VERSION "V5.0.0"

NS_ :

BS_:

BU_: SGW_SG CGW_SG

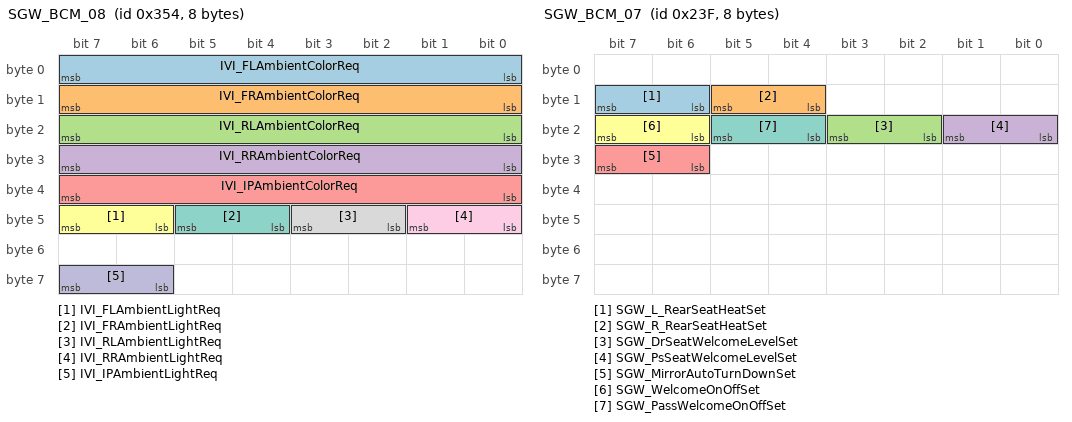
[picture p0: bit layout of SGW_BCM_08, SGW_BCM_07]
BO_ 852 SGW_BCM_08: 8 SGW_SG
 SG_ IVI_FLAmbientColorReq  : 7|8@0+ (1,0) [0|255] "" CGW_SG
 SG_ IVI_FRAmbientColorReq  : 15|8@0+ (1,0) [0|255] "" CGW_SG
 SG_ IVI_RLAmbientColorReq  : 23|8@0+ (1,0) [0|255] "" CGW_SG
 SG_ IVI_RRAmbientColorReq  : 31|8@0+ (1,0) [0|255] "" CGW_SG
 SG_ IVI_IPAmbientColorReq  : 39|8@0+ (1,0) [0|255] "" CGW_SG
 SG_ IVI_FLAmbientLightReq  : 47|2@0+ (1,0) [0|2] "" CGW_SG
 SG_ IVI_FRAmbientLightReq  : 45|2@0+ (1,0) [0|2] "" CGW_SG
 SG_ IVI_RLAmbientLightReq  : 43|2@0+ (1,0) [0|2] "" CGW_SG
 SG_ IVI_RRAmbientLightReq  : 41|2@0+ (1,0) [0|2] "" CGW_SG
 SG_ IVI_IPAmbientLightReq  : 63|2@0+ (1,0) [0|2] "" CGW_SG

BO_ 575 SGW_BCM_07: 8 SGW_SG
 SG_ SGW_L_RearSeatHeatSet  : 15|2@0+ (1,0) [0|3] "" CGW_SG
 SG_ SGW_R_RearSeatHeatSet  : 13|2@0+ (1,0) [0|3] "" CGW_SG
 SG_ SGW_DrSeatWelcomeLevelSet  : 19|2@0+ (1,0) [0|3] "" CGW_SG
 SG_ SGW_PsSeatWelcomeLevelSet  : 17|2@0+ (1,0) [0|3] "" CGW_SG
 SG_ SGW_MirrorAutoTurnDownSet  : 31|2@0+ (1,0) [0|3] "" CGW_SG
 SG_ SGW_WelcomeOnOffSet  : 23|2@0+ (1,0) [0|3] "" CGW_SG
 SG_ SGW_PassWelcomeOnOffSet  : 21|2@0+ (1,0) [0|3] "" CGW_SG

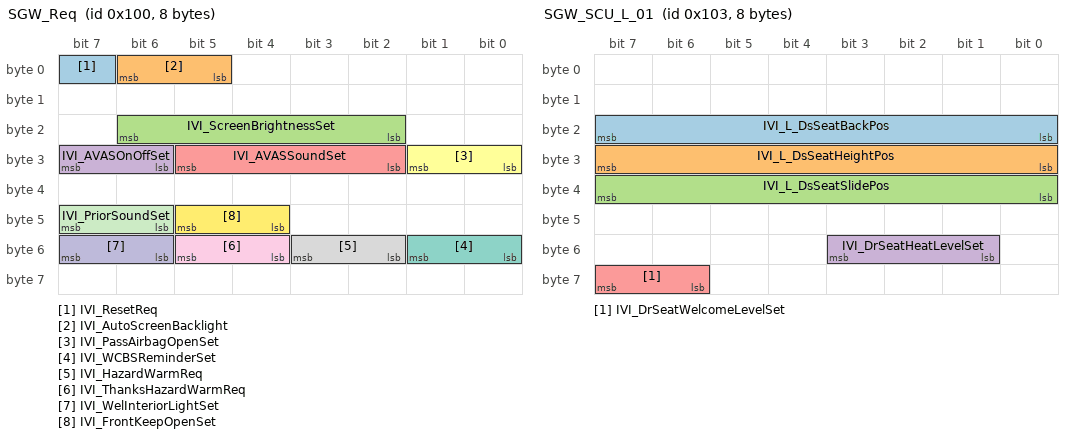
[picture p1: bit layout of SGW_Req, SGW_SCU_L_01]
BO_ 256 SGW_Req: 8 SGW_SG
 SG_ IVI_ResetReq  : 7|1@0+ (1,0) [0|1] "" CGW_SG
 SG_ IVI_AutoScreenBacklight  : 6|2@0+ (1,0) [0|3] "" CGW_SG
 SG_ IVI_ScreenBrightnessSet  : 22|5@0+ (1,0) [0|31] "" CGW_SG
 SG_ IVI_AVASOnOffSet  : 31|2@0+ (1,0) [0|3] "" CGW_SG
 SG_ IVI_AVASSoundSet  : 29|4@0+ (1,0) [0|9] "" CGW_SG
 SG_ IVI_PassAirbagOpenSet  : 25|2@0+ (1,0) [0|3] "" CGW_SG
 SG_ IVI_WCBSReminderSet  : 49|2@0+ (1,0) [0|3] "" CGW_SG
 SG_ IVI_HazardWarmReq  : 51|2@0+ (1,0) [0|2] "" CGW_SG
 SG_ IVI_ThanksHazardWarmReq  : 53|2@0+ (1,0) [0|1] "" CGW_SG
 SG_ IVI_WelInteriorLightSet  : 55|2@0+ (1,0) [0|2] "" CGW_SG
 SG_ IVI_PriorSoundSet  : 47|2@0+ (1,0) [0|3] "" CGW_SG
 SG_ IVI_FrontKeepOpenSet  : 45|2@0+ (1,0) [0|3] "" CGW_SG

BO_ 259 SGW_SCU_L_01: 8 SGW_SG
 SG_ IVI_L_DsSeatBackPos  : 23|8@0+ (1,0) [0|100] "percent" CGW_SG
 SG_ IVI_L_DsSeatHeightPos  : 31|8@0+ (1,0) [0|100] "percent" CGW_SG
 SG_ IVI_L_DsSeatSlidePos  : 39|8@0+ (1,0) [0|100] "percent" CGW_SG
 SG_ IVI_DrSeatHeatLevelSet  : 51|3@0+ (1,0) [0|7] "" CGW_SG
 SG_ IVI_DrSeatWelcomeLevelSet  : 63|2@0+ (1,0) [0|3] "" CGW_SG

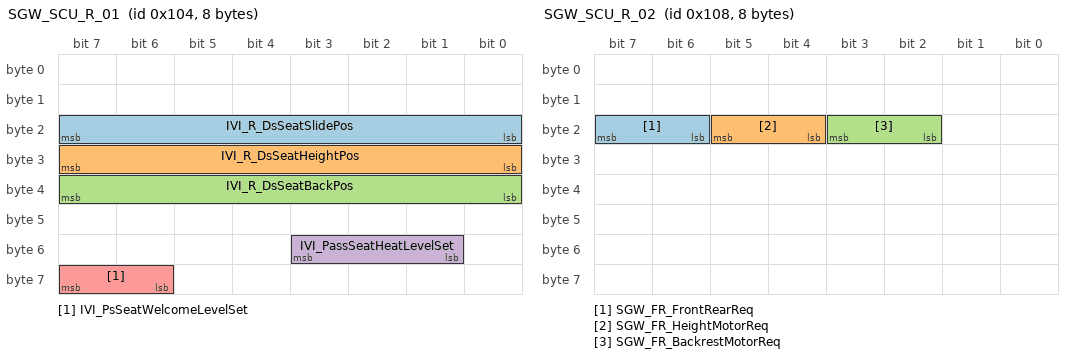
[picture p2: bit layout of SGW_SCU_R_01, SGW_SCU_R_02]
BO_ 260 SGW_SCU_R_01: 8 SGW_SG
 SG_ IVI_R_DsSeatSlidePos  : 23|8@0+ (1,0) [0|100] "percent" CGW_SG
 SG_ IVI_R_DsSeatHeightPos  : 31|8@0+ (1,0) [0|100] "percent" CGW_SG
 SG_ IVI_R_DsSeatBackPos  : 39|8@0+ (1,0) [0|100] "percent" CGW_SG
 SG_ IVI_PassSeatHeatLevelSet  : 51|3@0+ (1,0) [0|7] "" CGW_SG
 SG_ IVI_PsSeatWelcomeLevelSet  : 63|2@0+ (1,0) [0|3] "" CGW_SG

BO_ 264 SGW_SCU_R_02: 8 SGW_SG
 SG_ SGW_FR_FrontRearReq  : 23|2@0+ (1,0) [0|2] "" CGW_SG
 SG_ SGW_FR_HeightMotorReq  : 21|2@0+ (1,0) [0|2] "" CGW_SG
 SG_ SGW_FR_BackrestMotorReq  : 19|2@0+ (1,0) [0|2] "" CGW_SG

BO_ 710 SGW_SteerWhPos: 8 SGW_SG
 SG_ IVI_StWAnglePos  : 31|8@0+ (1,-100) [-100|100] "percent" CGW_SG
 SG_ IVI_StWLengthPos  : 39|8@0+ (1,-100) [-100|100] "percent" CGW_SG

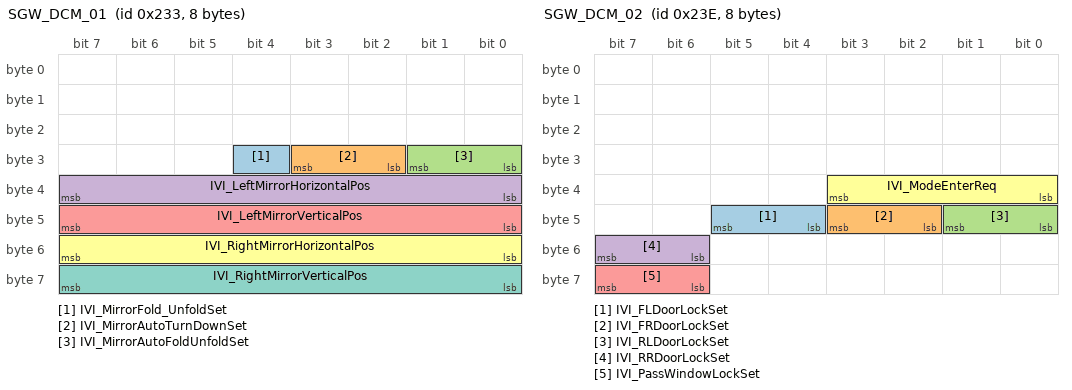
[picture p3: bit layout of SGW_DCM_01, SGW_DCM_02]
BO_ 563 SGW_DCM_01: 8 SGW_SG
 SG_ IVI_MirrorFold_UnfoldSet  : 28|1@0+ (1,0) [0|1] "" CGW_SG
 SG_ IVI_MirrorAutoTurnDownSet  : 27|2@0+ (1,0) [0|3] "" CGW_SG
 SG_ IVI_MirrorAutoFoldUnfoldSet  : 25|2@0+ (1,0) [0|3] "" CGW_SG
 SG_ IVI_LeftMirrorHorizontalPos  : 39|8@0+ (1,0) [0|100] "percent" CGW_SG
 SG_ IVI_LeftMirrorVerticalPos  : 47|8@0+ (1,0) [0|100] "percent" CGW_SG
 SG_ IVI_RightMirrorHorizontalPos  : 55|8@0+ (1,0) [0|100] "percent" CGW_SG
 SG_ IVI_RightMirrorVerticalPos  : 63|8@0+ (1,0) [0|100] "percent" CGW_SG

BO_ 574 SGW_DCM_02: 8 SGW_SG
 SG_ IVI_FLDoorLockSet  : 45|2@0+ (1,0) [0|3] "" CGW_SG
 SG_ IVI_FRDoorLockSet  : 43|2@0+ (1,0) [0|3] "" CGW_SG
 SG_ IVI_RLDoorLockSet  : 41|2@0+ (1,0) [0|3] "" CGW_SG
 SG_ IVI_RRDoorLockSet  : 55|2@0+ (1,0) [0|3] "" CGW_SG
 SG_ IVI_PassWindowLockSet  : 63|2@0+ (1,0) [0|3] "" CGW_SG
 SG_ IVI_ModeEnterReq  : 35|4@0+ (1,0) [0|15] "" CGW_SG

BO_ 689 SGW_HUD_01: 8 SGW_SG
 SG_ IVI_HUDALTITUDESet  : 7|8@0+ (1,0) [0|255] "" CGW_SG
 SG_ IVI_HUDOnOffSet  : 15|2@0+ (1,0) [0|3] "" CGW_SG

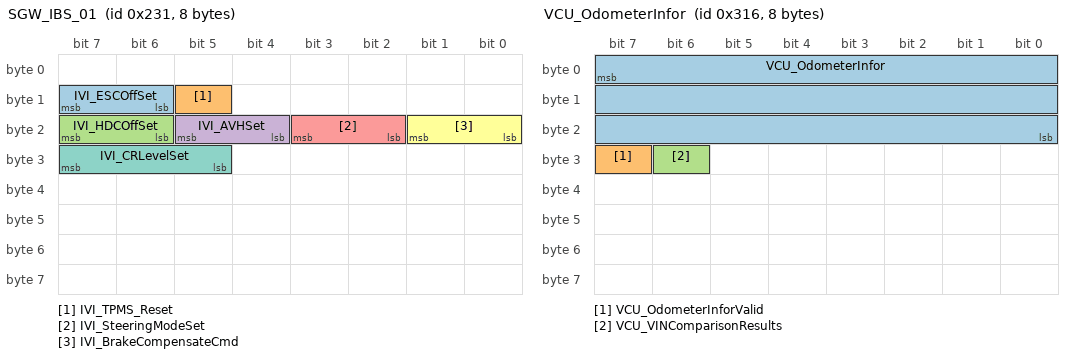
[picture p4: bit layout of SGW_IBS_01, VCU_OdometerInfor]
BO_ 561 SGW_IBS_01: 8 SGW_SG
 SG_ IVI_ESCOffSet  : 15|2@0+ (1,0) [0|3] "" CGW_SG
 SG_ IVI_TPMS_Reset  : 13|1@0+ (1,0) [0|1] "" CGW_SG
 SG_ IVI_HDCOffSet  : 23|2@0+ (1,0) [0|3] "" CGW_SG
 SG_ IVI_AVHSet  : 21|2@0+ (1,0) [0|3] "" CGW_SG
 SG_ IVI_SteeringModeSet  : 19|2@0+ (1,0) [0|3] "" CGW_SG
 SG_ IVI_BrakeCompensateCmd  : 17|2@0+ (1,0) [0|3] "" CGW_SG
 SG_ IVI_CRLevelSet  : 31|3@0+ (1,0) [0|7] "" CGW_SG

BO_ 790 VCU_OdometerInfor: 8 CGW_SG
 SG_ VCU_OdometerInfor  : 7|24@0+ (0.1,0) [0|999999.9] "km" SGW_SG
 SG_ VCU_OdometerInforValid  : 31|1@0+ (1,0) [0|1] "" SGW_SG
 SG_ VCU_VINComparisonResults  : 30|1@0+ (1,0) [0|1] "" SGW_SG

BO_ 945 SGW_OdometerInfor_02: 8 SGW_SG
 SG_ SGW_OdometerInfor  : 23|24@0+ (0.1,0) [0|999999.9] "" CGW_SG
 SG_ SGW_OdometerInforValid  : 47|1@0+ (1,0) [0|1] "" CGW_SG

BO_ 946 SGW_OdometerInfor_03: 8 SGW_SG
 SG_ SGW_VIN  : 7|64@0+ (1,0) [0|6.51062E+18] "" CGW_SG

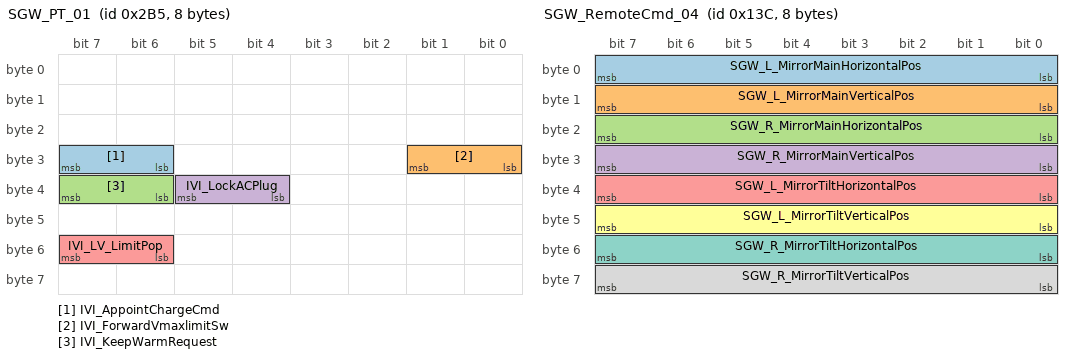
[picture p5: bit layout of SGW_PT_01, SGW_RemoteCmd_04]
BO_ 693 SGW_PT_01: 8 SGW_SG
 SG_ IVI_AppointChargeCmd  : 31|2@0+ (1,0) [0|2] "" CGW_SG
 SG_ IVI_ForwardVmaxlimitSw  : 25|2@0+ (1,0) [0|3] "" CGW_SG
 SG_ IVI_KeepWarmRequest  : 39|2@0+ (1,0) [0|2] "" CGW_SG
 SG_ IVI_LockACPlug  : 37|2@0+ (1,0) [0|2] "" CGW_SG
 SG_ IVI_LV_LimitPop  : 55|2@0+ (1,0) [0|2] "" CGW_SG

BO_ 694 IVI_01: 8 CGW_SG
 SG_ IVI_GearRequest  : 15|3@0+ (1,0) [0|5] "" SGW_SG

BO_ 261 SGW_RemoteCmd_01: 8 SGW_SG
 SG_ SGW_RemoteAirCondAUTOReq  : 13|2@0+ (1,0) [0|3] "" CGW_SG
 SG_ SGW_RemoteAirCondOnOFFReq  : 15|2@0+ (1,0) [0|3] "" CGW_SG
 SG_ SGW_RearDoorAngleSet  : 19|2@0+ (1,0) [0|2] "" CGW_SG
 SG_ SGW_FrontDoorAngleSet  : 21|2@0+ (1,0) [0|2] "" CGW_SG
 SG_ SGW_RemoteFrontDefrostReq  : 23|2@0+ (1,0) [0|3] "" CGW_SG
 SG_ SGW_RemoteSteerHeatReq  : 25|2@0+ (1,0) [0|3] "" CGW_SG
 SG_ SGW_RemoteDrSeatHeatReq  : 28|3@0+ (1,0) [0|4] "" CGW_SG
 SG_ SGW_LeftChdLockCtrlReq  : 31|2@0+ (1,0) [0|2] "" CGW_SG
 SG_ SGW_RearDefrostCtrlSet  : 32|1@0+ (1,0) [0|1] "" CGW_SG
 SG_ SGW_RemoteFrontWindHeatReq  : 34|2@0+ (1,0) [0|3] "" CGW_SG
 SG_ SGW_RemoteRearMirHeatReq  : 36|2@0+ (1,0) [0|3] "" CGW_SG
 SG_ SGW_RemotePassSeatHeatReq  : 39|3@0+ (1,0) [0|4] "" CGW_SG
 SG_ SGW_oneTouchCoolSet  : 43|2@0+ (1,0) [0|2] "" CGW_SG
 SG_ SGW_RemoteRearWindHeatReq  : 47|2@0+ (1,0) [0|3] "" CGW_SG
 SG_ SGW_TakePicCtrl  : 51|3@0+ (1,0) [0|7] "" CGW_SG
 SG_ SGW_RemoteACOnOffReq  : 57|2@0+ (1,0) [0|2] "" CGW_SG
 SG_ SGW_RightChdLockCtrlReq  : 59|2@0+ (1,0) [0|2] "" CGW_SG
 SG_ SGW_RemoteTailgateLockCtrlReq  : 63|2@0+ (1,0) [0|3] "" CGW_SG
 SG_ SGW_HDCOffSet  : 7|2@0+ (1,0) [0|3] "" Vector__XXX
 SG_ SGW_AVHSet  : 5|2@0+ (1,0) [0|3] "" Vector__XXX
 SG_ SGW_SteeringModeSet  : 61|2@0+ (1,0) [0|3] "" Vector__XXX
 SG_ SGW_AVASSoundSet  : 3|4@0+ (1,0) [0|9] "" Vector__XXX
 SG_ SGW_DriveModeSet  : 11|3@0+ (1,0) [0|4] "" Vector__XXX
 SG_ SGW_ImuCarParkBeStolen  : 55|3@0+ (1,0) [0|4] "" Vector__XXX

BO_ 262 SGW_RemoteCmd_02: 8 SGW_SG
 SG_ IVI_HUDScreenBrightnessSet  : 31|5@0+ (1,0) [0|31] "" CGW_SG

BO_ 263 SGW_RemoteCmd_03: 8 SGW_SG
 SG_ SGW_AutoCloseWinFunSet  : 1|2@0+ (1,0) [0|2] "" CGW_SG
 SG_ SGW_RemoteDrvSetTempSteplsReq  : 7|6@0+ (1,0) [0|63] "" CGW_SG
 SG_ SGW_FrontWiperAutoSet  : 9|2@0+ (1,0) [0|2] "" CGW_SG
 SG_ SGW_RemotePassSetTempSteplsReq  : 15|6@0+ (1,0) [0|63] "" CGW_SG
 SG_ SGW_AllDoorReq  : 17|2@0+ (1,0) [0|2] "" CGW_SG
 SG_ SGW_RemoteCarSearchReq  : 19|2@0+ (1,0) [0|3] "" CGW_SG
 SG_ SGW_RemoteLockCtrlReq  : 21|2@0+ (1,0) [0|3] "" CGW_SG
 SG_ SGW_RRDoorReq  : 25|2@0+ (1,0) [0|2] "" CGW_SG
 SG_ SGW_RLDoorReq  : 27|2@0+ (1,0) [0|2] "" CGW_SG
 SG_ SGW_FRDoorReq  : 29|2@0+ (1,0) [0|2] "" CGW_SG
 SG_ SGW_FLDoorReq  : 31|2@0+ (1,0) [0|2] "" CGW_SG
 SG_ SGW_WelInteriorLightSet  : 39|2@0+ (1,0) [0|2] "" CGW_SG
 SG_ SGW_CarSharingLightSet  : 37|2@0+ (1,0) [0|2] "" CGW_SG
 SG_ SGW_CarSharingColorSet  : 47|8@0+ (1,0) [0|255] "" CGW_SG
 SG_ SGW_CarSharingTimeSet  : 35|4@0+ (1,0) [0|10] "s" CGW_SG
 SG_ SGW_FRDomeLampSet  : 55|2@0+ (1,0) [0|2] "" CGW_SG
 SG_ SGW_RRDomeLampSet  : 53|2@0+ (1,0) [0|2] "" CGW_SG

BO_ 316 SGW_RemoteCmd_04: 8 SGW_SG
 SG_ SGW_L_MirrorMainHorizontalPos  : 7|8@0+ (1,0) [0|100] "percent" CGW_SG
 SG_ SGW_L_MirrorMainVerticalPos  : 15|8@0+ (1,0) [0|100] "percent" CGW_SG
 SG_ SGW_R_MirrorMainHorizontalPos  : 23|8@0+ (1,0) [0|100] "percent" CGW_SG
 SG_ SGW_R_MirrorMainVerticalPos  : 31|8@0+ (1,0) [0|100] "percent" CGW_SG
 SG_ SGW_L_MirrorTiltHorizontalPos  : 39|8@0+ (1,0) [0|100] "percent" CGW_SG
 SG_ SGW_L_MirrorTiltVerticalPos  : 47|8@0+ (1,0) [0|100] "percent" CGW_SG
 SG_ SGW_R_MirrorTiltHorizontalPos  : 55|8@0+ (1,0) [0|100] "percent" CGW_SG
 SG_ SGW_R_MirrorTiltVerticalPos  : 63|8@0+ (1,0) [0|100] "percent" CGW_SG

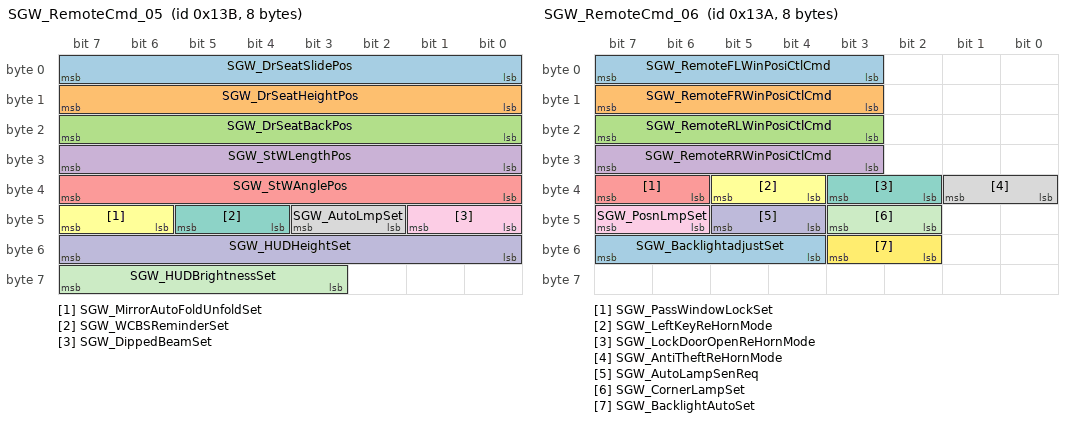
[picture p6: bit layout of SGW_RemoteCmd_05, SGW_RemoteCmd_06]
BO_ 315 SGW_RemoteCmd_05: 8 SGW_SG
 SG_ SGW_DrSeatSlidePos  : 7|8@0+ (1,0) [0|100] "percent" CGW_SG
 SG_ SGW_DrSeatHeightPos  : 15|8@0+ (1,0) [0|100] "percent" CGW_SG
 SG_ SGW_DrSeatBackPos  : 23|8@0+ (1,0) [0|100] "percent" CGW_SG
 SG_ SGW_StWLengthPos  : 31|8@0+ (1,-100) [-100|100] "percent" CGW_SG
 SG_ SGW_StWAnglePos  : 39|8@0+ (1,-100) [-100|100] "percent" CGW_SG
 SG_ SGW_MirrorAutoFoldUnfoldSet  : 47|2@0+ (1,0) [0|3] "" CGW_SG
 SG_ SGW_WCBSReminderSet  : 45|2@0+ (1,0) [0|3] "" CGW_SG
 SG_ SGW_AutoLmpSet  : 43|2@0+ (1,0) [0|3] "" CGW_SG
 SG_ SGW_DippedBeamSet  : 41|2@0+ (1,0) [0|3] "" CGW_SG
 SG_ SGW_HUDHeightSet  : 55|8@0+ (1,0) [0|255] "" CGW_SG
 SG_ SGW_HUDBrightnessSet  : 63|5@0+ (1,0) [0|31] "" CGW_SG

BO_ 314 SGW_RemoteCmd_06: 8 SGW_SG
 SG_ SGW_RemoteFLWinPosiCtlCmd  : 7|5@0+ (1,0) [0|21] "" CGW_SG
 SG_ SGW_RemoteFRWinPosiCtlCmd  : 15|5@0+ (1,0) [0|21] "" CGW_SG
 SG_ SGW_RemoteRLWinPosiCtlCmd  : 23|5@0+ (1,0) [0|21] "" CGW_SG
 SG_ SGW_RemoteRRWinPosiCtlCmd  : 31|5@0+ (1,0) [0|21] "" CGW_SG
 SG_ SGW_PassWindowLockSet  : 39|2@0+ (1,0) [0|3] "" CGW_SG
 SG_ SGW_LeftKeyReHornMode  : 37|2@0+ (1,0) [0|2] "" CGW_SG
 SG_ SGW_LockDoorOpenReHornMode  : 35|2@0+ (1,0) [0|2] "" CGW_SG
 SG_ SGW_AntiTheftReHornMode  : 33|2@0+ (1,0) [0|2] "" CGW_SG
 SG_ SGW_PosnLmpSet  : 47|2@0+ (1,0) [0|2] "" CGW_SG
 SG_ SGW_AutoLampSenReq  : 45|2@0+ (1,0) [0|3] "" CGW_SG
 SG_ SGW_CornerLampSet  : 43|2@0+ (1,0) [0|3] "" CGW_SG
 SG_ SGW_BacklightAutoSet  : 51|2@0+ (1,0) [0|2] "" CGW_SG
 SG_ SGW_BacklightadjustSet  : 55|4@0+ (1,0) [0|13] "" CGW_SG

BO_ 562 SGW_TCU_01: 8 SGW_SG
 SG_ SGW_DrvSetTempSteplsReq  : 7|6@0+ (1,0) [0|63] "" CGW_SG
 SG_ SGW_DemistReq  : 1|2@0+ (1,0) [0|3] "" CGW_SG
 SG_ SGW_HVACBatterySaveModeSetReq  : 15|2@0+ (1,0) [0|3] "" CGW_SG
 SG_ SGW_PassSetTempSteplsReq  : 13|6@0+ (1,0) [0|63] "" CGW_SG
 SG_ SGW_AirCondAUTOReq  : 23|2@0+ (1,0) [0|3] "" CGW_SG
 SG_ SGW_DualReq  : 21|2@0+ (1,0) [0|3] "" CGW_SG
 SG_ SGW_AirDistributionModeReq  : 19|3@0+ (1,0) [0|7] "" CGW_SG
 SG_ SGW_FrontDefrostReq  : 16|2@0+ (1,0) [0|3] "" CGW_SG
 SG_ SGW_AqsReq  : 39|2@0+ (1,0) [0|3] "" CGW_SG
 SG_ SGW_ClimateSystemStsReq  : 35|2@0+ (1,0) [0|3] "" CGW_SG
 SG_ SGW_ACCmprStsReq  : 33|2@0+ (1,0) [0|3] "" CGW_SG
 SG_ SGW_AirCirclnReq  : 47|2@0+ (1,0) [0|3] "" CGW_SG
 SG_ SGW_BlowersteplsSpdReq  : 43|4@0+ (1,0) [0|15] "" CGW_SG
 SG_ SGW_PresetModeEnable  : 55|2@0+ (1,0) [0|2] "" CGW_SG
 SG_ SGW_PresetModeReq  : 53|3@0+ (1,0) [0|7] "" CGW_SG
 SG_ SGW_VentilationModeReq  : 50|2@0+ (1,0) [0|2] "" CGW_SG
 SG_ SGW_AirCondEcoSet  : 60|2@0+ (1,0) [0|3] "" CGW_SG

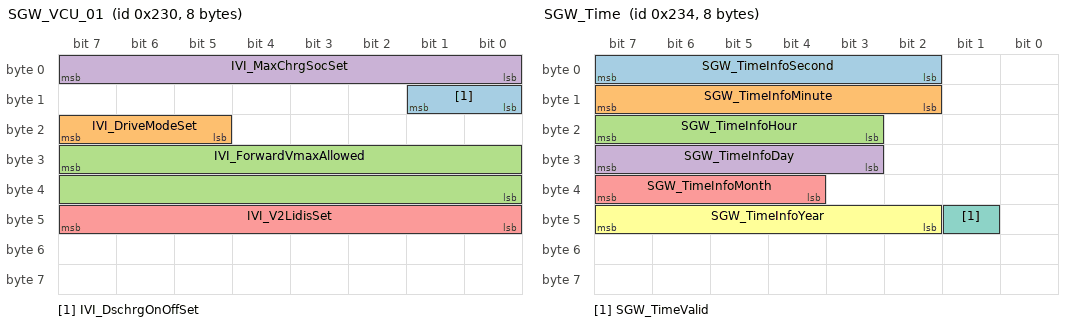
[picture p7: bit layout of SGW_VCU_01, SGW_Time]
BO_ 560 SGW_VCU_01: 8 SGW_SG
 SG_ IVI_DschrgOnOffSet  : 9|2@0+ (1,0) [0|3] "" CGW_SG
 SG_ IVI_DriveModeSet  : 23|3@0+ (1,0) [0|4] "" CGW_SG
 SG_ IVI_ForwardVmaxAllowed  : 31|16@0+ (0.01,0) [0|360] "km/h" CGW_SG
 SG_ IVI_MaxChrgSocSet  : 7|8@0+ (1,0) [0|100] "percent" CGW_SG
 SG_ IVI_V2LidisSet  : 47|8@0+ (1,0) [0|100] "percent" CGW_SG

BO_ 564 SGW_Time: 8 SGW_SG
 SG_ SGW_TimeInfoSecond  : 7|6@0+ (1,0) [0|59] "" CGW_SG
 SG_ SGW_TimeInfoMinute  : 15|6@0+ (1,0) [0|59] "" CGW_SG
 SG_ SGW_TimeInfoHour  : 23|5@0+ (1,0) [0|23] "" CGW_SG
 SG_ SGW_TimeInfoDay  : 31|5@0+ (1,0) [1|31] "" CGW_SG
 SG_ SGW_TimeInfoMonth  : 39|4@0+ (1,0) [1|12] "" CGW_SG
 SG_ SGW_TimeInfoYear  : 47|6@0+ (1,2000) [2000|2059] "" CGW_SG
 SG_ SGW_TimeValid  : 41|1@0+ (1,0) [0|1] "" CGW_SG

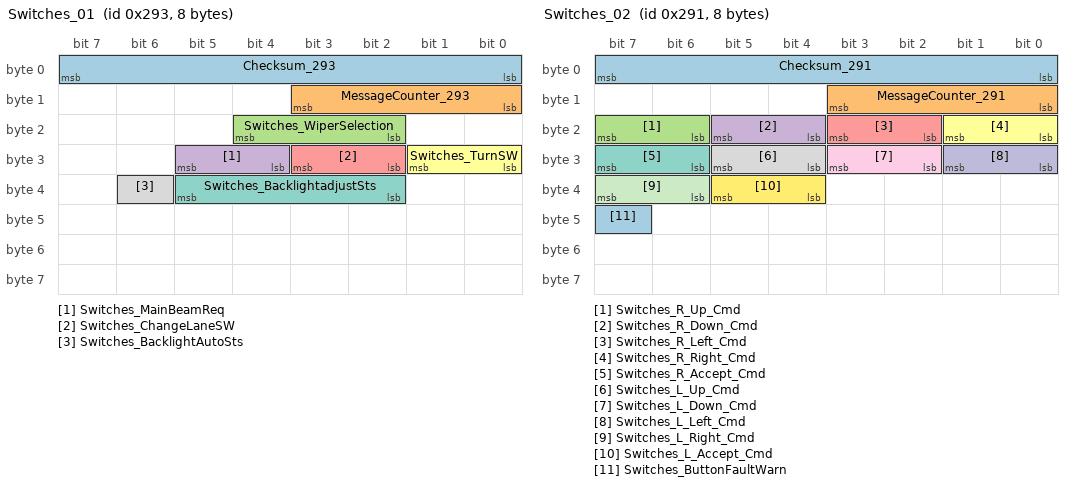
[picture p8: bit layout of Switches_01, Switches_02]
BO_ 659 Switches_01: 8 CGW_SG
 SG_ Checksum_293  : 7|8@0+ (1,0) [0|255] "" SGW_SG
 SG_ MessageCounter_293  : 11|4@0+ (1,0) [0|15] "" SGW_SG
 SG_ Switches_WiperSelection  : 20|3@0+ (1,0) [0|5] "" SGW_SG
 SG_ Switches_MainBeamReq  : 29|2@0+ (1,0) [0|3] "" SGW_SG
 SG_ Switches_ChangeLaneSW  : 27|2@0+ (1,0) [0|3] "" SGW_SG
 SG_ Switches_TurnSW  : 25|2@0+ (1,0) [0|3] "" SGW_SG
 SG_ Switches_BacklightadjustSts  : 37|4@0+ (1,0) [0|12] "" SGW_SG
 SG_ Switches_BacklightAutoSts  : 38|1@0+ (1,0) [0|1] "" SGW_SG

BO_ 657 Switches_02: 8 CGW_SG
 SG_ Checksum_291  : 7|8@0+ (1,0) [0|255] "" SGW_SG
 SG_ MessageCounter_291  : 11|4@0+ (1,0) [0|15] "" SGW_SG
 SG_ Switches_R_Up_Cmd  : 23|2@0+ (1,0) [0|1] "" SGW_SG
 SG_ Switches_R_Down_Cmd  : 21|2@0+ (1,0) [0|1] "" SGW_SG
 SG_ Switches_R_Left_Cmd  : 19|2@0+ (1,0) [0|1] "" SGW_SG
 SG_ Switches_R_Right_Cmd  : 17|2@0+ (1,0) [0|1] "" SGW_SG
 SG_ Switches_R_Accept_Cmd  : 31|2@0+ (1,0) [0|1] "" SGW_SG
 SG_ Switches_L_Up_Cmd  : 29|2@0+ (1,0) [0|1] "" SGW_SG
 SG_ Switches_L_Down_Cmd  : 27|2@0+ (1,0) [0|1] "" SGW_SG
 SG_ Switches_L_Left_Cmd  : 25|2@0+ (1,0) [0|1] "" SGW_SG
 SG_ Switches_L_Right_Cmd  : 39|2@0+ (1,0) [0|1] "" SGW_SG
 SG_ Switches_L_Accept_Cmd  : 37|2@0+ (1,0) [0|1] "" SGW_SG
 SG_ Switches_ButtonFaultWarn  : 47|1@0+ (1,0) [0|1] "" SGW_SG

BO_ 271 Switches_03: 8 CGW_SG
 SG_ Switches_L_SWipe_Cmd  : 0|4@0+ (1,0) [0|15] "" SGW_SG

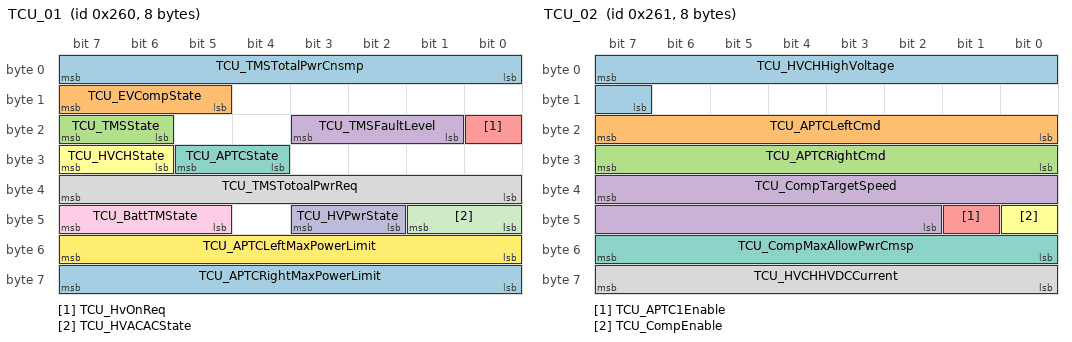
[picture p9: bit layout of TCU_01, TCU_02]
BO_ 608 TCU_01: 8 CGW_SG
 SG_ TCU_TMSTotalPwrCnsmp  : 7|8@0+ (200,0) [0|40000] "w" SGW_SG
 SG_ TCU_EVCompState  : 15|3@0+ (1,0) [0|7] "" SGW_SG
 SG_ TCU_TMSState  : 23|2@0+ (1,0) [0|2] "" SGW_SG
 SG_ TCU_TMSFaultLevel  : 19|3@0+ (1,0) [0|7] "" SGW_SG
 SG_ TCU_HvOnReq  : 16|1@0+ (1,0) [0|1] "" SGW_SG
 SG_ TCU_HVCHState  : 31|2@0+ (1,0) [0|3] "" SGW_SG
 SG_ TCU_APTCState  : 29|2@0+ (1,0) [0|3] "" SGW_SG
 SG_ TCU_TMSTotoalPwrReq  : 39|8@0+ (200,0) [0|40000] "w" SGW_SG
 SG_ TCU_BattTMState  : 47|3@0+ (1,0) [0|7] "" SGW_SG
 SG_ TCU_HVPwrState  : 43|2@0+ (1,0) [0|3] "" SGW_SG
 SG_ TCU_HVACACState  : 41|2@0+ (1,0) [0|3] "" SGW_SG
 SG_ TCU_APTCLeftMaxPowerLimit  : 55|8@0+ (0.04,0) [0|10.2] "KW" SGW_SG
 SG_ TCU_APTCRightMaxPowerLimit  : 63|8@0+ (0.04,0) [0|10.2] "KW" SGW_SG

BO_ 609 TCU_02: 8 CGW_SG
 SG_ TCU_HVCHHighVoltage  : 7|9@0+ (1,0) [0|508] "V" SGW_SG
 SG_ TCU_APTCLeftCmd  : 23|8@0+ (1,0) [0|100] "percent" SGW_SG
 SG_ TCU_APTCRightCmd  : 31|8@0+ (1,0) [0|100] "percent" SGW_SG
 SG_ TCU_CompTargetSpeed  : 39|14@0+ (1,0) [0|9200] "rpm" SGW_SG
 SG_ TCU_APTC1Enable  : 41|1@0+ (1,0) [0|1] "" SGW_SG
 SG_ TCU_CompEnable  : 40|1@0+ (1,0) [0|1] "" SGW_SG
 SG_ TCU_CompMaxAllowPwrCmsp  : 55|8@0+ (0.04,0) [0|10.16] "KW" SGW_SG
 SG_ TCU_HVCHHVDCCurrent  : 63|8@0+ (0.25,0) [0|63.5] "A" SGW_SG

BO_ 610 TCU_03: 8 CGW_SG
 SG_ TCU_CabinTemperature  : 23|8@0+ (1,-50) [-50|205] "celsius" SGW_SG
 SG_ TCU_CabinTemperatureValid  : 31|1@0+ (1,0) [0|1] "" SGW_SG

BO_ 768 TCU_IVI: 8 CGW_SG
 SG_ TCU_AirCondAUTOSts  : 3|1@0+ (1,0) [0|1] "" SGW_SG
 SG_ TCU_AirCirclnSts  : 5|2@0+ (1,0) [0|2] "" SGW_SG
 SG_ TCU_AirCondEcoSetSts  : 8|1@0+ (1,0) [0|1] "" SGW_SG
 SG_ TCU_SelfDryingSetSts  : 9|1@0+ (1,0) [0|1] "" SGW_SG
 SG_ TCU_DrvTempSts  : 15|6@0+ (1,0) [0|63] "" SGW_SG
 SG_ TCU_AqsSts  : 16|1@0+ (1,0) [0|1] "" SGW_SG
 SG_ TCU_DualSts  : 17|1@0+ (1,0) [0|1] "" SGW_SG
 SG_ TCU_PassTempSts  : 23|6@0+ (1,0) [0|63] "" SGW_SG
 SG_ TCU_CoolantLowWarnReq  : 25|2@0+ (1,0) [0|3] "" SGW_SG
 SG_ TCU_FreonLowWarnReq  : 27|2@0+ (1,0) [0|3] "" SGW_SG
 SG_ TCU_BlowerSpdSts  : 31|4@0+ (1,0) [0|15] "" SGW_SG
 SG_ TCU_AirDistributionModeSts  : 39|3@0+ (1,0) [0|7] "" SGW_SG
 SG_ TCU_PresetModeSts  : 35|3@0+ (1,0) [0|7] "" SGW_SG
 SG_ TCU_VentilationModeSts  : 32|1@0+ (1,0) [0|1] "" SGW_SG
 SG_ TCU_ACCmprSts  : 42|1@0+ (1,0) [0|1] "" SGW_SG
 SG_ TCU_ClimateSystemSts  : 43|1@0+ (1,0) [0|1] "" SGW_SG
 SG_ TCU_PowerLimitSts  : 44|1@0+ (1,0) [0|1] "" SGW_SG
 SG_ TCU_OutsideAQSLevel  : 47|3@0+ (1,0) [0|7] "" SGW_SG
 SG_ TCU_WindowClosRemind  : 50|1@0+ (1,0) [0|1] "" SGW_SG
 SG_ TCU_DemistSts  : 51|1@0+ (1,0) [0|1] "" SGW_SG

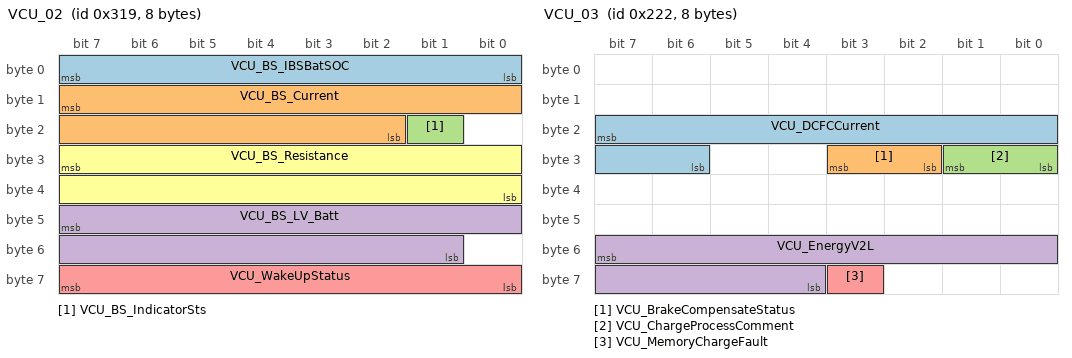
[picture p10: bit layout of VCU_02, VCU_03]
BO_ 793 VCU_02: 8 CGW_SG
 SG_ VCU_BS_IBSBatSOC  : 7|8@0+ (1,0) [0|100] "percent" SGW_SG
 SG_ VCU_BS_Current  : 15|14@0+ (0.001,-8.192) [-8.192|8.191] "" SGW_SG
 SG_ VCU_BS_IndicatorSts  : 17|1@0+ (1,0) [0|1] "" SGW_SG
 SG_ VCU_BS_LV_Batt  : 47|15@0+ (0.001,0) [0|32.767] "V" SGW_SG
 SG_ VCU_WakeUpStatus  : 63|8@0+ (1,0) [0|255] "" SGW_SG
 SG_ VCU_BS_Resistance  : 31|16@0+ (0.01,0) [0|65535] "mOhm" SGW_SG

BO_ 546 VCU_03: 8 CGW_SG
 SG_ VCU_DCFCCurrent  : 23|10@0+ (1,0) [0|1023] "A" SGW_SG
 SG_ VCU_BrakeCompensateStatus  : 27|2@0+ (1,0) [0|3] "" SGW_SG
 SG_ VCU_ChargeProcessComment  : 25|2@0+ (1,0) [0|3] "" SGW_SG
 SG_ VCU_EnergyV2L  : 55|12@0+ (0.1,0) [0|102.3] "kWh" SGW_SG
 SG_ VCU_MemoryChargeFault  : 59|1@0+ (1,0) [0|1] "" SGW_SG

BO_ 547 VCU_04: 8 CGW_SG
 SG_ VCU_ForwardVmaxlimitStatus  : 15|1@0+ (1,0) [0|1] "" SGW_SG
 SG_ VCU_ManuallyUnlockComment  : 14|1@0+ (1,0) [0|1] "" SGW_SG

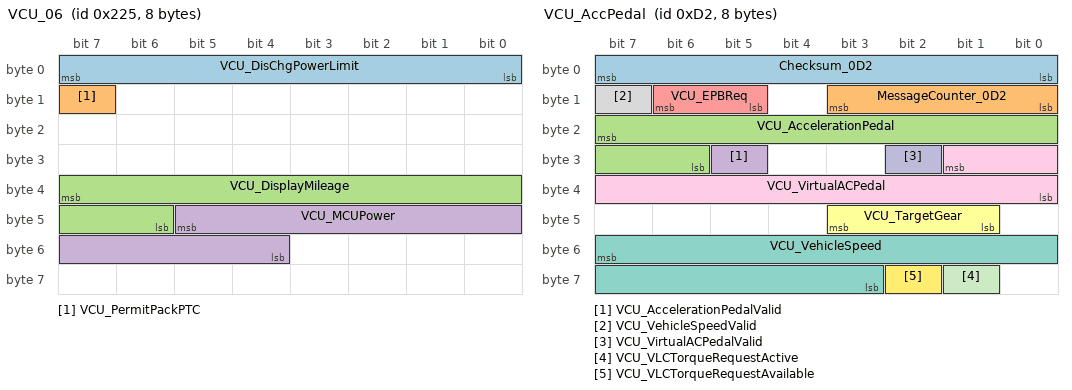
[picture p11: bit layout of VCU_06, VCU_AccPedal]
BO_ 549 VCU_06: 8 CGW_SG
 SG_ VCU_DisChgPowerLimit  : 7|8@0+ (0.1,0) [0|25.5] "kW" SGW_SG
 SG_ VCU_PermitPackPTC  : 15|1@0+ (1,0) [0|1] "" SGW_SG
 SG_ VCU_DisplayMileage  : 39|10@0+ (1,0) [0|1023] "km" SGW_SG
 SG_ VCU_MCUPower  : 45|10@0+ (1,-400) [-400|623] "kW" SGW_SG

BO_ 210 VCU_AccPedal: 8 CGW_SG
 SG_ Checksum_0D2  : 7|8@0+ (1,0) [0|255] "" SGW_SG
 SG_ MessageCounter_0D2  : 11|4@0+ (1,0) [0|15] "" SGW_SG
 SG_ VCU_AccelerationPedal  : 23|10@0+ (0.1,0) [0|100] "percent" SGW_SG
 SG_ VCU_AccelerationPedalValid  : 29|1@0+ (1,0) [0|1] "" SGW_SG
 SG_ VCU_EPBReq  : 14|2@0+ (1,0) [0|3] "" SGW_SG
 SG_ VCU_TargetGear  : 43|3@0+ (1,0) [0|4] "" SGW_SG
 SG_ VCU_VehicleSpeed  : 55|13@0+ (0.05625,0) [0|360] "km/h" SGW_SG
 SG_ VCU_VehicleSpeedValid  : 15|1@0+ (1,0) [0|1] "" SGW_SG
 SG_ VCU_VirtualACPedal  : 25|10@0+ (0.1,0) [0|100] "percent" SGW_SG
 SG_ VCU_VirtualACPedalValid  : 26|1@0+ (1,0) [0|1] "" SGW_SG
 SG_ VCU_VLCTorqueRequestActive  : 57|1@0+ (1,0) [0|1] "" SGW_SG
 SG_ VCU_VLCTorqueRequestAvailable  : 58|1@0+ (1,0) [0|1] "" SGW_SG

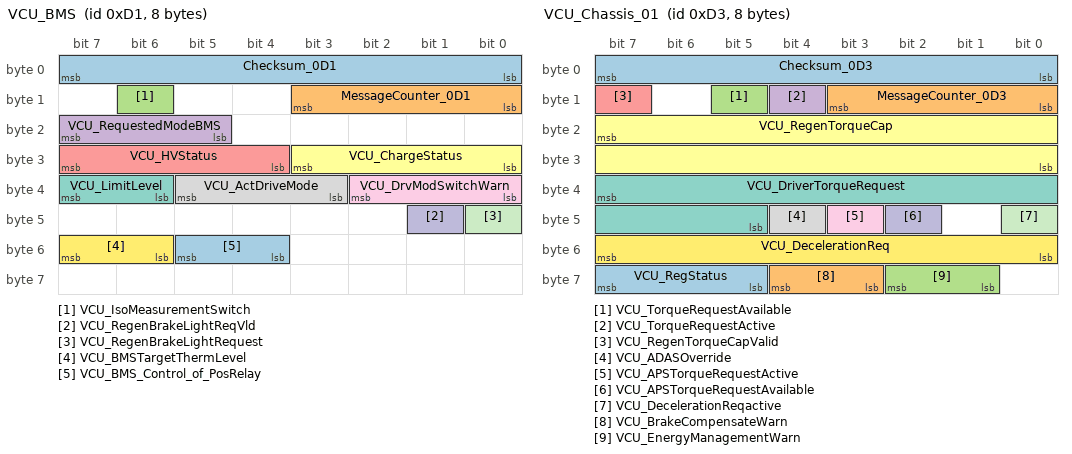
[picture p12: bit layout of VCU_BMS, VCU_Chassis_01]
BO_ 209 VCU_BMS: 8 CGW_SG
 SG_ Checksum_0D1  : 7|8@0+ (1,0) [0|255] "" SGW_SG
 SG_ MessageCounter_0D1  : 11|4@0+ (1,0) [0|15] "" SGW_SG
 SG_ VCU_IsoMeasurementSwitch  : 14|1@0+ (1,0) [0|1] "" SGW_SG
 SG_ VCU_RequestedModeBMS  : 23|3@0+ (1,0) [0|7] "" SGW_SG
 SG_ VCU_HVStatus  : 31|4@0+ (1,0) [0|5] "" SGW_SG
 SG_ VCU_ChargeStatus  : 27|4@0+ (1,0) [0|14] "" SGW_SG
 SG_ VCU_LimitLevel  : 39|2@0+ (1,0) [0|3] "" SGW_SG
 SG_ VCU_ActDriveMode  : 37|3@0+ (1,0) [0|4] "" SGW_SG
 SG_ VCU_DrvModSwitchWarn  : 34|3@0+ (1,0) [0|7] "" SGW_SG
 SG_ VCU_RegenBrakeLightReqVld  : 41|1@0+ (1,0) [0|1] "" SGW_SG
 SG_ VCU_RegenBrakeLightRequest  : 40|1@0+ (1,0) [0|1] "" SGW_SG
 SG_ VCU_BMSTargetThermLevel  : 55|2@0+ (1,0) [0|3] "" SGW_SG
 SG_ VCU_BMS_Control_of_PosRelay  : 53|2@0+ (1,0) [0|2] "" SGW_SG

BO_ 211 VCU_Chassis_01: 8 CGW_SG
 SG_ Checksum_0D3  : 7|8@0+ (1,0) [0|255] "" SGW_SG
 SG_ MessageCounter_0D3  : 11|4@0+ (1,0) [0|15] "" SGW_SG
 SG_ VCU_TorqueRequestAvailable  : 13|1@0+ (1,0) [0|1] "" SGW_SG
 SG_ VCU_TorqueRequestActive  : 12|1@0+ (1,0) [0|1] "" SGW_SG
 SG_ VCU_RegenTorqueCapValid  : 15|1@0+ (1,0) [0|1] "" SGW_SG
 SG_ VCU_RegenTorqueCap  : 23|16@0+ (1,-20000) [-20000|20000] "" SGW_SG
 SG_ VCU_DriverTorqueRequest  : 39|11@0+ (1,-1023) [-1023|1022] "" SGW_SG
 SG_ VCU_ADASOverride  : 44|1@0+ (1,0) [0|1] "" SGW_SG
 SG_ VCU_APSTorqueRequestActive  : 43|1@0+ (1,0) [0|1] "" SGW_SG
 SG_ VCU_APSTorqueRequestAvailable  : 42|1@0+ (1,0) [0|1] "" SGW_SG
 SG_ VCU_DecelerationReqactive  : 40|1@0+ (1,0) [0|1] "" SGW_SG
 SG_ VCU_DecelerationReq  : 55|8@0+ (0.05,-5) [-5|7.75] "m/s^2" SGW_SG
 SG_ VCU_RegStatus  : 63|3@0+ (1,0) [0|7] "" SGW_SG
 SG_ VCU_BrakeCompensateWarn  : 60|2@0+ (1,0) [0|3] "" SGW_SG
 SG_ VCU_EnergyManagementWarn  : 58|2@0+ (1,0) [0|3] "" SGW_SG

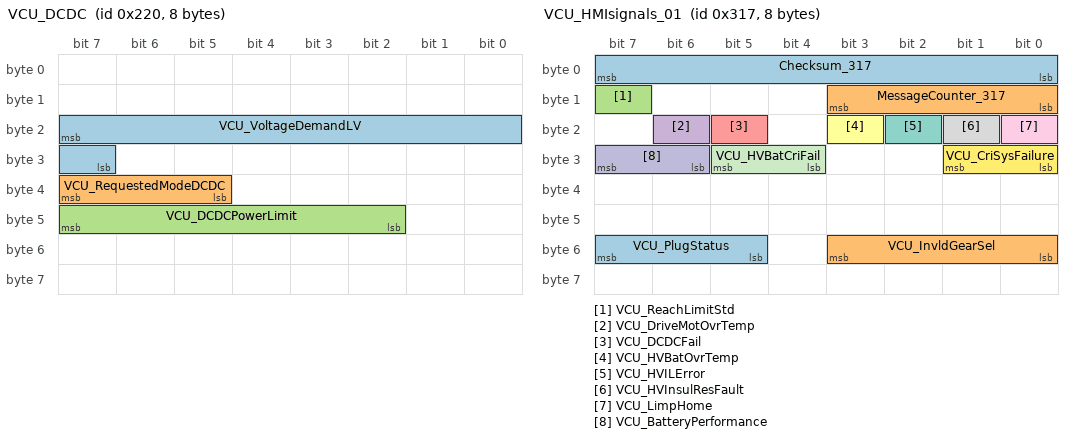
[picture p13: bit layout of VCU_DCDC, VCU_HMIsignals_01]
BO_ 544 VCU_DCDC: 8 CGW_SG
 SG_ VCU_VoltageDemandLV  : 23|9@0+ (0.125,0) [0|63.625] "V" SGW_SG
 SG_ VCU_RequestedModeDCDC  : 39|3@0+ (1,0) [0|2] "" SGW_SG
 SG_ VCU_DCDCPowerLimit  : 47|6@0+ (0.1,0) [0|6.3] "kW" SGW_SG

BO_ 791 VCU_HMIsignals_01: 8 CGW_SG
 SG_ Checksum_317  : 7|8@0+ (1,0) [0|255] "" SGW_SG
 SG_ MessageCounter_317  : 11|4@0+ (1,0) [0|15] "" SGW_SG
 SG_ VCU_ReachLimitStd  : 15|1@0+ (1,0) [0|1] "" SGW_SG
 SG_ VCU_DriveMotOvrTemp  : 22|1@0+ (1,0) [0|1] "" SGW_SG
 SG_ VCU_DCDCFail  : 21|1@0+ (1,0) [0|1] "" SGW_SG
 SG_ VCU_HVBatOvrTemp  : 19|1@0+ (1,0) [0|1] "" SGW_SG
 SG_ VCU_HVILError  : 18|1@0+ (1,0) [0|1] "" SGW_SG
 SG_ VCU_HVInsulResFault  : 17|1@0+ (1,0) [0|1] "" SGW_SG
 SG_ VCU_LimpHome  : 16|1@0+ (1,0) [0|1] "" SGW_SG
 SG_ VCU_BatteryPerformance  : 31|2@0+ (1,0) [0|3] "" SGW_SG
 SG_ VCU_HVBatCriFail  : 29|2@0+ (1,0) [0|3] "" SGW_SG
 SG_ VCU_CriSysFailure  : 25|2@0+ (1,0) [0|3] "" SGW_SG
 SG_ VCU_PlugStatus  : 55|3@0+ (1,0) [0|7] "" SGW_SG
 SG_ VCU_InvldGearSel  : 51|4@0+ (1,0) [0|15] "" SGW_SG

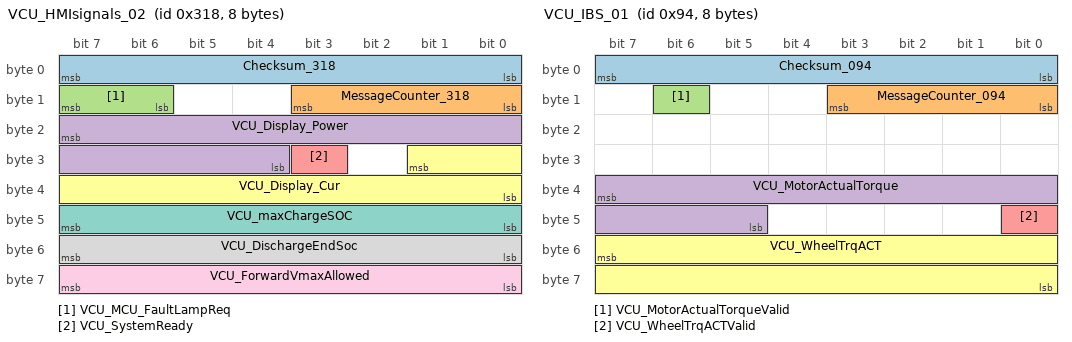
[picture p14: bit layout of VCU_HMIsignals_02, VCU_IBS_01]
BO_ 792 VCU_HMIsignals_02: 8 CGW_SG
 SG_ Checksum_318  : 7|8@0+ (1,0) [0|255] "" SGW_SG
 SG_ MessageCounter_318  : 11|4@0+ (1,0) [0|15] "" SGW_SG
 SG_ VCU_MCU_FaultLampReq  : 15|2@0+ (1,0) [0|3] "" SGW_SG
 SG_ VCU_Display_Power  : 23|12@0+ (0.1,0) [0|409.5] "kW" SGW_SG
 SG_ VCU_SystemReady  : 27|1@0+ (1,0) [0|1] "" SGW_SG
 SG_ VCU_Display_Cur  : 25|10@0+ (1,0) [0|1023] "A" SGW_SG
 SG_ VCU_maxChargeSOC  : 47|8@0+ (1,0) [0|255] "" SGW_SG
 SG_ VCU_DischargeEndSoc  : 55|8@0+ (1,0) [0|255] "percent" SGW_SG
 SG_ VCU_ForwardVmaxAllowed  : 63|8@0+ (1,0) [0|255] "" SGW_SG

BO_ 795 VCU_HMIsignals_03: 8 CGW_SG
 SG_ VCU_Display_voltage  : 23|10@0+ (1,0) [0|1023] "V" SGW_SG

BO_ 148 VCU_IBS_01: 8 CGW_SG
 SG_ Checksum_094  : 7|8@0+ (1,0) [0|255] "" SGW_SG
 SG_ MessageCounter_094  : 11|4@0+ (1,0) [0|15] "" SGW_SG
 SG_ VCU_MotorActualTorqueValid  : 14|1@0+ (1,0) [0|1] "" SGW_SG
 SG_ VCU_MotorActualTorque  : 39|11@0+ (1,-1024) [-1024|1023] "" SGW_SG
 SG_ VCU_WheelTrqACTValid  : 40|1@0+ (1,0) [0|1] "" SGW_SG
 SG_ VCU_WheelTrqACT  : 55|16@0+ (1,-20000) [-20000|20000] "Nm" SGW_SG

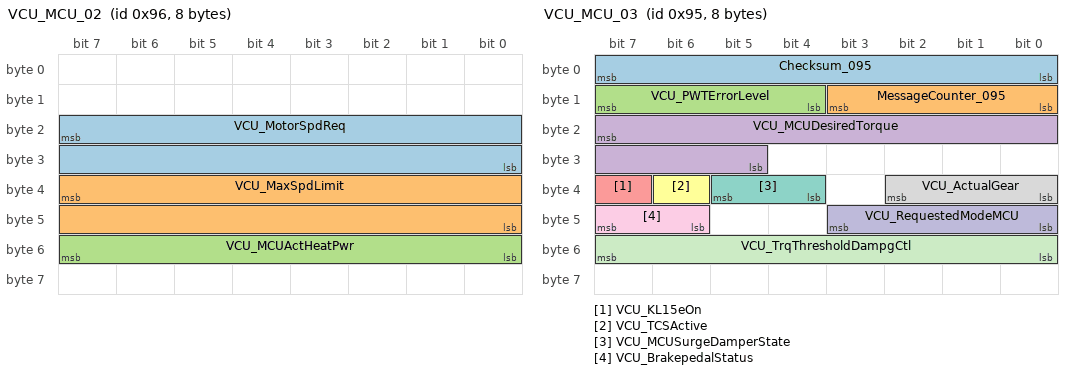
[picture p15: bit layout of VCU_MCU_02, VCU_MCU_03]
BO_ 150 VCU_MCU_02: 8 CGW_SG
 SG_ VCU_MotorSpdReq  : 23|16@0+ (1,-32767) [-32767|32767] "" SGW_SG
 SG_ VCU_MaxSpdLimit  : 39|16@0+ (1,-32767) [-32767|32767] "" SGW_SG
 SG_ VCU_MCUActHeatPwr  : 55|8@0+ (0.1,0) [0|10] "kW" SGW_SG

BO_ 149 VCU_MCU_03: 8 CGW_SG
 SG_ Checksum_095  : 7|8@0+ (1,0) [0|255] "" SGW_SG
 SG_ MessageCounter_095  : 11|4@0+ (1,0) [0|15] "" SGW_SG
 SG_ VCU_PWTErrorLevel  : 15|4@0+ (1,0) [0|15] "" SGW_SG
 SG_ VCU_MCUDesiredTorque  : 23|11@0+ (1,-1023) [-1023|1022] "Nm" SGW_SG
 SG_ VCU_KL15eOn  : 39|1@0+ (1,0) [0|1] "" SGW_SG
 SG_ VCU_TCSActive  : 38|1@0+ (1,0) [0|1] "" SGW_SG
 SG_ VCU_MCUSurgeDamperState  : 37|2@0+ (1,0) [0|2] "SED" SGW_SG
 SG_ VCU_ActualGear  : 34|3@0+ (1,0) [0|4] "" SGW_SG
 SG_ VCU_BrakepedalStatus  : 47|2@0+ (1,0) [0|2] "" SGW_SG
 SG_ VCU_RequestedModeMCU  : 43|4@0+ (1,0) [0|4] "" SGW_SG
 SG_ VCU_TrqThresholdDampgCtl  : 55|8@0+ (0.1,0) [0|25] "Nm" SGW_SG

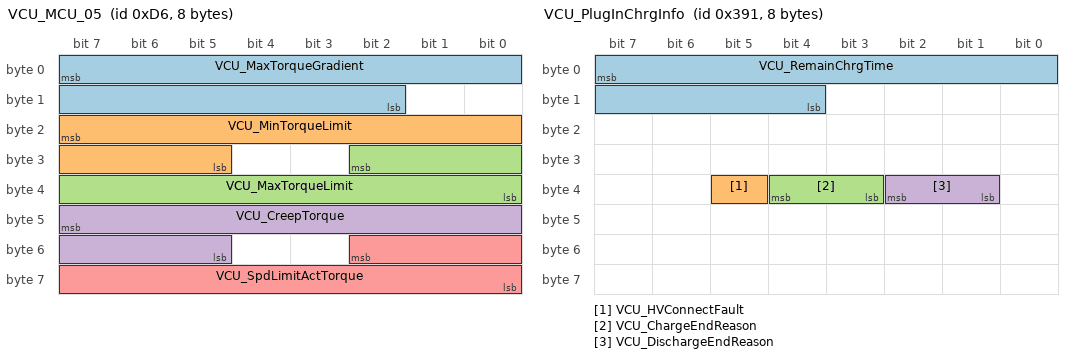
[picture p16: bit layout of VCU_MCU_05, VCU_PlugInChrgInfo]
BO_ 214 VCU_MCU_05: 8 CGW_SG
 SG_ VCU_MaxTorqueGradient  : 7|14@0+ (32,0) [0|524192] "Nm/s" SGW_SG
 SG_ VCU_MinTorqueLimit  : 23|11@0+ (1,-1023) [-1023|1022] "Nm" SGW_SG
 SG_ VCU_MaxTorqueLimit  : 26|11@0+ (1,-1023) [-1023|1022] "Nm" SGW_SG
 SG_ VCU_CreepTorque  : 47|11@0+ (1,-1024) [-1024|1023] "" SGW_SG
 SG_ VCU_SpdLimitActTorque  : 50|11@0+ (1,-1024) [-1024|1023] "" SGW_SG

BO_ 913 VCU_PlugInChrgInfo: 8 CGW_SG
 SG_ VCU_RemainChrgTime  : 7|12@0+ (1,0) [0|3600] "min" SGW_SG
 SG_ VCU_HVConnectFault  : 37|1@0+ (1,0) [0|1] "" SGW_SG
 SG_ VCU_ChargeEndReason  : 36|2@0+ (1,0) [0|3] "" SGW_SG
 SG_ VCU_DischargeEndReason  : 34|2@0+ (1,0) [0|3] "" SGW_SG

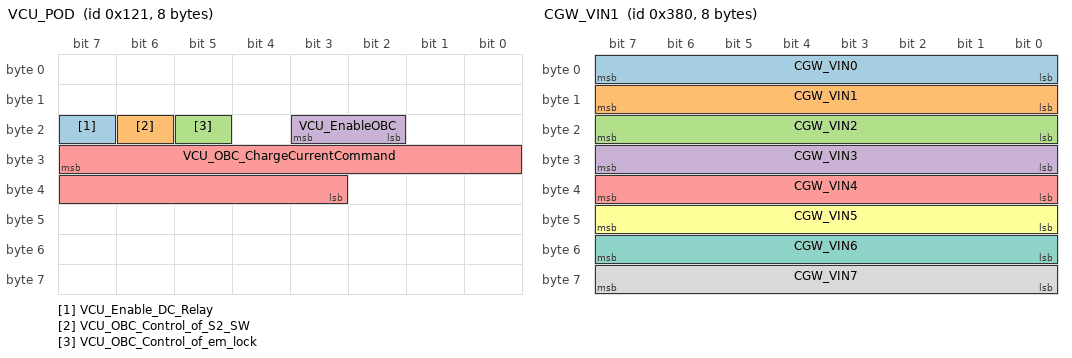
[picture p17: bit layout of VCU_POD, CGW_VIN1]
BO_ 289 VCU_POD: 8 CGW_SG
 SG_ VCU_Enable_DC_Relay  : 23|1@0+ (1,0) [0|1] "" SGW_SG
 SG_ VCU_OBC_Control_of_S2_SW  : 22|1@0+ (1,0) [0|1] "" SGW_SG
 SG_ VCU_OBC_Control_of_em_lock  : 21|1@0+ (1,0) [0|1] "" SGW_SG
 SG_ VCU_EnableOBC  : 19|2@0+ (1,0) [0|3] "" SGW_SG
 SG_ VCU_OBC_ChargeCurrentCommand  : 31|13@0+ (0.1,0) [0|500] "A" SGW_SG

BO_ 545 VCU_TCU: 8 CGW_SG
 SG_ VCU_RequestedModeTCU  : 15|2@0+ (1,0) [0|3] "" SGW_SG
 SG_ VCU_TCUPowerAllowed  : 13|13@0+ (40,0) [0|64000] "W" SGW_SG

BO_ 663 WCBS_01: 8 CGW_SG
 SG_ WCBS1_Reminder  : 0|1@0+ (1,0) [0|1] "" SGW_SG
 SG_ WCBS1_ReminderSts  : 1|1@0+ (1,0) [0|1] "" SGW_SG

BO_ 664 WCBS_02: 8 CGW_SG
 SG_ WCBS2_Reminder  : 0|1@0+ (1,0) [0|1] "" SGW_SG
 SG_ WCBS2_ReminderSts  : 1|1@0+ (1,0) [0|1] "" SGW_SG

BO_ 317 BCM_SynReq_01: 8 CGW_SG
 SG_ BCM_SynRequest  : 7|24@0+ (1,0) [0|16777215] "" SGW_SG

BO_ 319 VCU_SynReq_01: 8 CGW_SG
 SG_ VCU_SynRequest  : 7|24@0+ (1,0) [0|16777215] "" SGW_SG

BO_ 896 CGW_VIN1: 8 CGW_SG
 SG_ CGW_VIN0  : 7|8@0+ (1,0) [0|255] "" SGW_SG
 SG_ CGW_VIN1  : 15|8@0+ (1,0) [0|255] "" SGW_SG
 SG_ CGW_VIN2  : 23|8@0+ (1,0) [0|255] "" SGW_SG
 SG_ CGW_VIN3  : 31|8@0+ (1,0) [0|255] "" SGW_SG
 SG_ CGW_VIN4  : 39|8@0+ (1,0) [0|255] "" SGW_SG
 SG_ CGW_VIN5  : 47|8@0+ (1,0) [0|255] "" SGW_SG
 SG_ CGW_VIN6  : 55|8@0+ (1,0) [0|255] "" SGW_SG
 SG_ CGW_VIN7  : 63|8@0+ (1,0) [0|255] "" SGW_SG

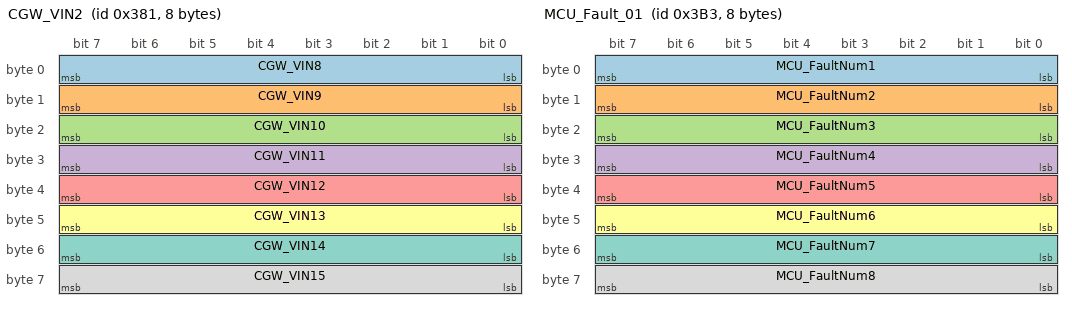
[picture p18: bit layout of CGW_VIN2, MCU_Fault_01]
BO_ 897 CGW_VIN2: 8 CGW_SG
 SG_ CGW_VIN8  : 7|8@0+ (1,0) [0|255] "" SGW_SG
 SG_ CGW_VIN9  : 15|8@0+ (1,0) [0|255] "" SGW_SG
 SG_ CGW_VIN10  : 23|8@0+ (1,0) [0|255] "" SGW_SG
 SG_ CGW_VIN11  : 31|8@0+ (1,0) [0|255] "" SGW_SG
 SG_ CGW_VIN12  : 39|8@0+ (1,0) [0|255] "" SGW_SG
 SG_ CGW_VIN13  : 47|8@0+ (1,0) [0|255] "" SGW_SG
 SG_ CGW_VIN14  : 55|8@0+ (1,0) [0|255] "" SGW_SG
 SG_ CGW_VIN15  : 63|8@0+ (1,0) [0|255] "" SGW_SG

BO_ 898 CGW_VIN3VER: 8 CGW_SG
 SG_ CGW_VIN16  : 7|8@0+ (1,0) [0|255] "" SGW_SG
 SG_ CGW_VERSION1  : 15|8@0+ (1,0) [0|5] "" SGW_SG
 SG_ CGW_VERSION2  : 23|8@0+ (1,0) [0|255] "" SGW_SG

BO_ 858 CGW_02: 8 CGW_SG
 SG_ CGW_SGWSts  : 0|1@0+ (1,0) [0|1] "" SGW_SG
 SG_ CGW_CGWSts  : 1|1@0+ (1,0) [0|1] "" SGW_SG
 SG_ CGW_CBMSts  : 2|1@0+ (1,0) [0|1] "" SGW_SG
 SG_ CGW_DCM_FLSts  : 3|1@0+ (1,0) [0|1] "" SGW_SG
 SG_ CGW_DCM_FRSts  : 4|1@0+ (1,0) [0|1] "" SGW_SG
 SG_ CGW_DCM_RLSts  : 5|1@0+ (1,0) [0|1] "" SGW_SG
 SG_ CGW_DCM_RRSts  : 6|1@0+ (1,0) [0|1] "" SGW_SG
 SG_ CGW_SCU_LSts  : 7|1@0+ (1,0) [0|1] "" SGW_SG
 SG_ CGW_SCU_RSts  : 8|1@0+ (1,0) [0|1] "" SGW_SG
 SG_ CGW_HLRSts  : 9|1@0+ (1,0) [0|1] "" SGW_SG
 SG_ CGW_HLLSts  : 10|1@0+ (1,0) [0|1] "" SGW_SG
 SG_ CGW_MFP_RCSts  : 11|1@0+ (1,0) [0|1] "" SGW_SG
 SG_ CGW_MFP_FCSts  : 12|1@0+ (1,0) [0|1] "" SGW_SG
 SG_ CGW_IVISts  : 13|1@0+ (1,0) [0|1] "" SGW_SG
 SG_ CGW_ADCUSts  : 14|1@0+ (1,0) [0|1] "" SGW_SG
 SG_ CGW_VCUSts  : 15|1@0+ (1,0) [0|1] "" SGW_SG
 SG_ CGW_BMSSts  : 16|1@0+ (1,0) [0|1] "" SGW_SG
 SG_ CGW_BCMSts  : 17|1@0+ (1,0) [0|1] "" SGW_SG
 SG_ CGW_SWPSts  : 18|1@0+ (1,0) [0|1] "" SGW_SG
 SG_ CGW_HOD_HeatingSts  : 19|1@0+ (1,0) [0|1] "" SGW_SG
 SG_ CGW_SwichesSts  : 20|1@0+ (1,0) [0|1] "" SGW_SG
 SG_ CGW_PRNDSts  : 21|1@0+ (1,0) [0|1] "" SGW_SG

BO_ 857 SGW_06: 8 SGW_SG
 SG_ SGW_SGWSts  : 0|1@0+ (1,0) [0|1] "" CGW_SG
 SG_ SGW_CGWSts  : 1|1@0+ (1,0) [0|1] "" CGW_SG
 SG_ SGW_CBMSts  : 2|1@0+ (1,0) [0|1] "" CGW_SG
 SG_ SGW_DCM_FLSts  : 3|1@0+ (1,0) [0|1] "" CGW_SG
 SG_ SGW_DCM_FRSts  : 4|1@0+ (1,0) [0|1] "" CGW_SG
 SG_ SGW_DCM_RLSts  : 5|1@0+ (1,0) [0|1] "" CGW_SG
 SG_ SGW_DCM_RRSts  : 6|1@0+ (1,0) [0|1] "" CGW_SG
 SG_ SGW_SCU_LSts  : 7|1@0+ (1,0) [0|1] "" CGW_SG
 SG_ SGW_SCU_RSts  : 8|1@0+ (1,0) [0|1] "" CGW_SG
 SG_ SGW_HLRSts  : 9|1@0+ (1,0) [0|1] "" CGW_SG
 SG_ SGW_HLLSts  : 10|1@0+ (1,0) [0|1] "" CGW_SG
 SG_ SGW_MFP_RCSts  : 11|1@0+ (1,0) [0|1] "" CGW_SG
 SG_ SGW_MFP_FCSts  : 12|1@0+ (1,0) [0|1] "" CGW_SG
 SG_ SGW_IVISts  : 13|1@0+ (1,0) [0|1] "" CGW_SG
 SG_ SGW_ADCUSts  : 14|1@0+ (1,0) [0|1] "" CGW_SG
 SG_ SGW_VCUSts  : 15|1@0+ (1,0) [0|1] "" CGW_SG
 SG_ SGW_BMSSts  : 16|1@0+ (1,0) [0|1] "" CGW_SG
 SG_ SGW_BCMSts  : 17|1@0+ (1,0) [0|1] "" CGW_SG
 SG_ SGW_SWPSts  : 18|1@0+ (1,0) [0|1] "" CGW_SG
 SG_ SGW_HOD_HeatingSts  : 19|1@0+ (1,0) [0|1] "" CGW_SG
 SG_ SGW_SwichesSts  : 20|1@0+ (1,0) [0|1] "" CGW_SG
 SG_ SGW_PRNDSts  : 21|1@0+ (1,0) [0|1] "" CGW_SG

BO_ 1283 NM_SGW: 8 SGW_SG
 SG_ SGW_RMR  : 8|1@0+ (1,0) [0|1] "" CGW_SG
 SG_ SGW_AWB  : 12|1@0+ (1,0) [0|1] "" CGW_SG
 SG_ SGW_PNI  : 14|1@0+ (1,0) [0|1] "" CGW_SG
 SG_ SGW_PNC0  : 24|1@0+ (1,0) [0|1] "" CGW_SG
 SG_ SGW_PNC1  : 25|1@0+ (1,0) [0|1] "" CGW_SG
 SG_ SGW_PNC2  : 26|1@0+ (1,0) [0|1] "" CGW_SG
 SG_ SGW_PNC3  : 27|1@0+ (1,0) [0|1] "" CGW_SG
 SG_ SGW_PNC4  : 28|1@0+ (1,0) [0|1] "" CGW_SG
 SG_ SGW_PNC5  : 29|1@0+ (1,0) [0|1] "" CGW_SG
 SG_ SGW_PNC6  : 30|1@0+ (1,0) [0|1] "" CGW_SG
 SG_ SGW_PNC7  : 31|1@0+ (1,0) [0|1] "" CGW_SG
 SG_ SGW_PNC8  : 32|1@0+ (1,0) [0|1] "" CGW_SG
 SG_ SGW_PNC9  : 33|1@0+ (1,0) [0|1] "" CGW_SG
 SG_ SGW_PNC10  : 34|1@0+ (1,0) [0|1] "" CGW_SG
 SG_ SGW_PNC11  : 35|1@0+ (1,0) [0|1] "" CGW_SG
 SG_ SGW_PNC12  : 36|1@0+ (1,0) [0|1] "" CGW_SG
 SG_ SGW_PNC13  : 37|1@0+ (1,0) [0|1] "" CGW_SG
 SG_ SGW_PNC14  : 38|1@0+ (1,0) [0|1] "" CGW_SG
 SG_ SGW_PNC15  : 39|1@0+ (1,0) [0|1] "" CGW_SG
 SG_ SGW_PNC16  : 40|1@0+ (1,0) [0|1] "" CGW_SG
 SG_ SGW_PNC17  : 41|1@0+ (1,0) [0|1] "" CGW_SG
 SG_ SGW_PNC18  : 42|1@0+ (1,0) [0|1] "" CGW_SG
 SG_ SGW_PNC19  : 43|1@0+ (1,0) [0|1] "" CGW_SG
 SG_ SGW_PNC20  : 44|1@0+ (1,0) [0|1] "" CGW_SG
 SG_ SGW_PNC21  : 45|1@0+ (1,0) [0|1] "" CGW_SG
 SG_ SGW_PNC22  : 46|1@0+ (1,0) [0|1] "" CGW_SG
 SG_ SGW_PNC23  : 47|1@0+ (1,0) [0|1] "" CGW_SG
 SG_ SGW_PNC24  : 48|1@0+ (1,0) [0|1] "" CGW_SG
 SG_ SGW_PNC25  : 49|1@0+ (1,0) [0|1] "" CGW_SG
 SG_ SGW_PNC26  : 50|1@0+ (1,0) [0|1] "" CGW_SG
 SG_ SGW_PNC27  : 51|1@0+ (1,0) [0|1] "" CGW_SG
 SG_ SGW_PNC28  : 52|1@0+ (1,0) [0|1] "" CGW_SG
 SG_ SGW_PNC29  : 53|1@0+ (1,0) [0|1] "" CGW_SG
 SG_ SGW_PNC30  : 54|1@0+ (1,0) [0|1] "" CGW_SG
 SG_ SGW_PNC31  : 55|1@0+ (1,0) [0|1] "" CGW_SG
 SG_ SGW_PNC32  : 56|1@0+ (1,0) [0|1] "" CGW_SG
 SG_ SGW_PNC33  : 57|1@0+ (1,0) [0|1] "" CGW_SG
 SG_ SGW_PNC34  : 58|1@0+ (1,0) [0|1] "" CGW_SG
 SG_ SGW_PNC35  : 59|1@0+ (1,0) [0|1] "" CGW_SG
 SG_ SGW_PNC36  : 60|1@0+ (1,0) [0|1] "" CGW_SG
 SG_ SGW_PNC37  : 61|1@0+ (1,0) [0|1] "" CGW_SG
 SG_ SGW_PNC38  : 62|1@0+ (1,0) [0|1] "" CGW_SG
 SG_ SGW_PNC39  : 63|1@0+ (1,0) [0|1] "" CGW_SG

BO_ 1282 NM_CGW: 8 CGW_SG
 SG_ CGW_RMR  : 8|1@0+ (1,0) [0|1] "" SGW_SG
 SG_ CGW_AWB  : 12|1@0+ (1,0) [0|1] "" SGW_SG
 SG_ CGW_PNI  : 14|1@0+ (1,0) [0|1] "" SGW_SG
 SG_ CGW_PNC0  : 24|1@0+ (1,0) [0|1] "" SGW_SG
 SG_ CGW_PNC1  : 25|1@0+ (1,0) [0|1] "" SGW_SG
 SG_ CGW_PNC2  : 26|1@0+ (1,0) [0|1] "" SGW_SG
 SG_ CGW_PNC3  : 27|1@0+ (1,0) [0|1] "" SGW_SG
 SG_ CGW_PNC4  : 28|1@0+ (1,0) [0|1] "" SGW_SG
 SG_ CGW_PNC5  : 29|1@0+ (1,0) [0|1] "" SGW_SG
 SG_ CGW_PNC6  : 30|1@0+ (1,0) [0|1] "" SGW_SG
 SG_ CGW_PNC7  : 31|1@0+ (1,0) [0|1] "" SGW_SG
 SG_ CGW_PNC8  : 32|1@0+ (1,0) [0|1] "" SGW_SG
 SG_ CGW_PNC9  : 33|1@0+ (1,0) [0|1] "" SGW_SG
 SG_ CGW_PNC10  : 34|1@0+ (1,0) [0|1] "" SGW_SG
 SG_ CGW_PNC11  : 35|1@0+ (1,0) [0|1] "" SGW_SG
 SG_ CGW_PNC12  : 36|1@0+ (1,0) [0|1] "" SGW_SG
 SG_ CGW_PNC13  : 37|1@0+ (1,0) [0|1] "" SGW_SG
 SG_ CGW_PNC14  : 38|1@0+ (1,0) [0|1] "" SGW_SG
 SG_ CGW_PNC15  : 39|1@0+ (1,0) [0|1] "" SGW_SG
 SG_ CGW_PNC16  : 40|1@0+ (1,0) [0|1] "" SGW_SG
 SG_ CGW_PNC17  : 41|1@0+ (1,0) [0|1] "" SGW_SG
 SG_ CGW_PNC18  : 42|1@0+ (1,0) [0|1] "" SGW_SG
 SG_ CGW_PNC19  : 43|1@0+ (1,0) [0|1] "" SGW_SG
 SG_ CGW_PNC20  : 44|1@0+ (1,0) [0|1] "" SGW_SG
 SG_ CGW_PNC21  : 45|1@0+ (1,0) [0|1] "" SGW_SG
 SG_ CGW_PNC22  : 46|1@0+ (1,0) [0|1] "" SGW_SG
 SG_ CGW_PNC23  : 47|1@0+ (1,0) [0|1] "" SGW_SG
 SG_ CGW_PNC24  : 48|1@0+ (1,0) [0|1] "" SGW_SG
 SG_ CGW_PNC25  : 49|1@0+ (1,0) [0|1] "" SGW_SG
 SG_ CGW_PNC26  : 50|1@0+ (1,0) [0|1] "" SGW_SG
 SG_ CGW_PNC27  : 51|1@0+ (1,0) [0|1] "" SGW_SG
 SG_ CGW_PNC28  : 52|1@0+ (1,0) [0|1] "" SGW_SG
 SG_ CGW_PNC29  : 53|1@0+ (1,0) [0|1] "" SGW_SG
 SG_ CGW_PNC30  : 54|1@0+ (1,0) [0|1] "" SGW_SG
 SG_ CGW_PNC31  : 55|1@0+ (1,0) [0|1] "" SGW_SG
 SG_ CGW_PNC32  : 56|1@0+ (1,0) [0|1] "" SGW_SG
 SG_ CGW_PNC33  : 57|1@0+ (1,0) [0|1] "" SGW_SG
 SG_ CGW_PNC34  : 58|1@0+ (1,0) [0|1] "" SGW_SG
 SG_ CGW_PNC35  : 59|1@0+ (1,0) [0|1] "" SGW_SG
 SG_ CGW_PNC36  : 60|1@0+ (1,0) [0|1] "" SGW_SG
 SG_ CGW_PNC37  : 61|1@0+ (1,0) [0|1] "" SGW_SG
 SG_ CGW_PNC38  : 62|1@0+ (1,0) [0|1] "" SGW_SG
 SG_ CGW_PNC39  : 63|1@0+ (1,0) [0|1] "" SGW_SG

BO_ 2047 DiagReq_ALL: 8 SGW_SG
 SG_ ALL_DiagReq  : 7|64@0+ (1,0) [0|1] "" CGW_SG

BO_ 2015 DiagReq_FUN: 8 SGW_SG
 SG_ FUN_DiagReq  : 7|64@0+ (1,0) [0|1] "" CGW_SG

BO_ 1843 DiagReq_OBD: 8 SGW_SG
 SG_ OBD_DiagReq  : 7|64@0+ (1,0) [0|1] "" CGW_SG

BO_ 2016 DiagReq_VCU_OBD: 8 SGW_SG
 SG_ VCU_OBD_DiagReq  : 7|64@0+ (1,0) [0|1] "" CGW_SG

BO_ 2024 DiagResp_VCU_OBD: 8 CGW_SG
 SG_ VCU_OBD_DiagResp  : 7|64@0+ (1,0) [0|1] "" SGW_SG

BO_ 2025 DiagReq_BD: 8 SGW_SG
 SG_ BD_DiagReq  : 7|64@0+ (1,0) [0|1] "" CGW_SG

BO_ 2029 DiagReq_ET: 8 SGW_SG
 SG_ ET_DiagReq  : 7|64@0+ (1,0) [0|1] "" CGW_SG

BO_ 2026 DiagReq_PT: 8 SGW_SG
 SG_ PT_DiagReq  : 7|64@0+ (1,0) [0|1] "" CGW_SG

BO_ 2027 DiagReq_CH: 8 SGW_SG
 SG_ CH_DiagReq  : 7|64@0+ (1,0) [0|1] "" CGW_SG

BO_ 1922 DiagReq_CGW: 8 SGW_SG
 SG_ CGW_DiagReq  : 7|64@0+ (1,0) [0|1] "" CGW_SG

BO_ 1921 DiagReq_BCM1: 8 SGW_SG
 SG_ BCM1_DiagReq  : 7|64@0+ (1,0) [0|1] "" CGW_SG

BO_ 1946 DiagReq_BCM2: 8 SGW_SG
 SG_ BCM2_DiagReq  : 7|64@0+ (1,0) [0|1] "" CGW_SG

BO_ 1947 DiagReq_SCUL: 8 SGW_SG
 SG_ SCUL_DiagReq  : 7|64@0+ (1,0) [0|1] "" CGW_SG

BO_ 1948 DiagReq_SCUR: 8 SGW_SG
 SG_ SCUR_DiagReq  : 7|64@0+ (1,0) [0|1] "" CGW_SG

BO_ 1951 DiagReq_WCBS_01: 8 SGW_SG
 SG_ WCBS1_DiagReq  : 7|64@0+ (1,0) [0|1] "" CGW_SG

BO_ 1952 DiagReq_WCBS_02: 8 SGW_SG
 SG_ WCBS2_DiagReq  : 7|64@0+ (1,0) [0|1] "" CGW_SG

BO_ 1967 DiagReq_DCM_FL: 8 SGW_SG
 SG_ DCM_FL_DiagReq  : 7|64@0+ (1,0) [0|1] "" CGW_SG

BO_ 1975 DiagReq_DCM_FR: 8 SGW_SG
 SG_ DCM_FR_DiagReq  : 7|64@0+ (1,0) [0|1] "" CGW_SG

BO_ 1979 DiagReq_DCM_RL: 8 SGW_SG
 SG_ DCM_RL_DiagReq  : 7|64@0+ (1,0) [0|1] "" CGW_SG

BO_ 1980 DiagReq_DCM_RR: 8 SGW_SG
 SG_ DCM_RR_DiagReq  : 7|64@0+ (1,0) [0|1] "" CGW_SG

BO_ 1950 DiagReq_HLR: 8 SGW_SG
 SG_ HLR_DiagReq  : 7|64@0+ (1,0) [0|1] "" CGW_SG

BO_ 1949 DiagReq_HLL: 8 SGW_SG
 SG_ HLL_DiagReq  : 7|64@0+ (1,0) [0|1] "" CGW_SG

BO_ 1963 DiagReq_PAT: 8 SGW_SG
 SG_ PAT_DiagReq  : 7|64@0+ (1,0) [0|1] "" CGW_SG

BO_ 1924 DiagReq_IVI: 8 SGW_SG
 SG_ IVI_DiagReq  : 7|64@0+ (1,0) [0|1] "" CGW_SG

BO_ 1933 DiagReq_HUD: 8 SGW_SG
 SG_ HUD_DiagReq  : 7|64@0+ (1,0) [0|1] "" CGW_SG

BO_ 1945 DiagReq_MFP_RC: 8 SGW_SG
 SG_ MFP_RC_DiagReq  : 7|64@0+ (1,0) [0|1] "" CGW_SG

BO_ 1942 DiagReq_MFP_FC: 8 SGW_SG
 SG_ MFP_FC_DiagReq  : 7|64@0+ (1,0) [0|1] "" CGW_SG

BO_ 1927 DiagReq_SWP: 8 SGW_SG
 SG_ SWP_DiagReq  : 7|64@0+ (1,0) [0|1] "" CGW_SG

BO_ 1926 DiagReq_Switches: 8 SGW_SG
 SG_ Switches_DiagReq  : 7|64@0+ (1,0) [0|1] "" CGW_SG

BO_ 1940 DiagReq_Switches2: 8 SGW_SG
 SG_ Switches2_DiagReq  : 7|64@0+ (1,0) [0|1] "" CGW_SG

BO_ 1929 DiagReq_HOD_heating: 8 SGW_SG
 SG_ HOD_heating_DiagReq  : 7|64@0+ (1,0) [0|1] "" CGW_SG

BO_ 1934 DiagReq_DIM: 8 SGW_SG
 SG_ DIM_DiagReq  : 7|64@0+ (1,0) [0|1] "" CGW_SG

BO_ 1928 DiagReq_NDT: 8 SGW_SG
 SG_ NDT_DiagReq  : 7|64@0+ (1,0) [0|1] "" CGW_SG

BO_ 1991 DiagReq_POD: 8 SGW_SG
 SG_ POD_DiagReq  : 7|64@0+ (1,0) [0|1] "" CGW_SG

BO_ 1939 DiagReq_BMS: 8 SGW_SG
 SG_ BMS_DiagReq  : 7|64@0+ (1,0) [0|1] "" CGW_SG

BO_ 1992 DiagReq_TCU: 8 SGW_SG
 SG_ TCU_DiagReq  : 7|64@0+ (1,0) [0|1] "" CGW_SG

BO_ 1998 DiagReq_AIRPTC: 8 SGW_SG
 SG_ AIRPTC_DiagReq  : 7|64@0+ (1,0) [0|1] "" CGW_SG

BO_ 1964 DiagReq_VCU: 8 SGW_SG
 SG_ VCU_DiagReq  : 7|64@0+ (1,0) [0|1] "" CGW_SG

BO_ 1986 DiagReq_MCU: 8 SGW_SG
 SG_ MCU_DiagReq  : 7|64@0+ (1,0) [0|1] "" CGW_SG

BO_ 1999 DiagReq_PRND: 8 SGW_SG
 SG_ PRND_DiagReq  : 7|64@0+ (1,0) [0|1] "" CGW_SG

BO_ 1993 DiagReq_EVCOM: 8 SGW_SG
 SG_ EVCOM_DiagReq  : 7|64@0+ (1,0) [0|1] "" CGW_SG

BO_ 1958 DiagReq_IBS: 8 SGW_SG
 SG_ IBS_DiagReq  : 7|64@0+ (1,0) [0|1] "" CGW_SG

BO_ 2033 DiagReq_ACU: 8 SGW_SG
 SG_ ACU_DiagReq  : 7|64@0+ (1,0) [0|1] "" CGW_SG

BO_ 1961 DiagReq_EPS: 8 SGW_SG
 SG_ EPS_DiagReq  : 7|64@0+ (1,0) [0|1] "" CGW_SG

BO_ 1987 DiagReq_AVAS: 8 SGW_SG
 SG_ AVAS_DiagReq  : 7|64@0+ (1,0) [0|1] "" CGW_SG

BO_ 1984 DiagReq_ADCU: 8 SGW_SG
 SG_ ADCU_DiagReq  : 7|64@0+ (1,0) [0|1] "" CGW_SG

BO_ 1794 DiagResp_CGW: 8 CGW_SG
 SG_ CGW_DiagResp  : 7|64@0+ (1,0) [0|1] "" SGW_SG

BO_ 1793 DiagResp_BCM1: 8 CGW_SG
 SG_ BCM1_DiagResp  : 7|64@0+ (1,0) [0|1] "" SGW_SG

BO_ 1818 DiagResp_BCM2: 8 CGW_SG
 SG_ BCM2_DiagResp  : 7|64@0+ (1,0) [0|1] "" SGW_SG

BO_ 1819 DiagResp_SCUL: 8 CGW_SG
 SG_ SCUL_DiagResp  : 7|64@0+ (1,0) [0|1] "" SGW_SG

BO_ 1820 DiagResp_SCUR: 8 CGW_SG
 SG_ SCUR_DiagResp  : 7|64@0+ (1,0) [0|1] "" SGW_SG

BO_ 1823 DiagResp_WCBS1: 8 CGW_SG
 SG_ WCBS1_DiagResp  : 7|64@0+ (1,0) [0|1] "" SGW_SG

BO_ 1824 DiagResp_WCBS2: 8 CGW_SG
 SG_ WCBS2_DiagResp  : 7|64@0+ (1,0) [0|1] "" SGW_SG

BO_ 1839 DiagResp_DCM_FL: 8 CGW_SG
 SG_ DCM_FL_DiagResp  : 7|64@0+ (1,0) [0|1] "" SGW_SG

BO_ 1847 DiagResp_DCM_FR: 8 CGW_SG
 SG_ DCM_FR_DiagResp  : 7|64@0+ (1,0) [0|1] "" SGW_SG

BO_ 1851 DiagResp_DCM_RL: 8 CGW_SG
 SG_ DCM_RL_DiagResp  : 7|64@0+ (1,0) [0|1] "" SGW_SG

BO_ 1852 DiagResp_DCM_RR: 8 CGW_SG
 SG_ DCM_RR_DiagResp  : 7|64@0+ (1,0) [0|1] "" SGW_SG

BO_ 1822 DiagResp_HLR: 8 CGW_SG
 SG_ HLR_DiagResp  : 7|64@0+ (1,0) [0|1] "" SGW_SG

BO_ 1821 DiagResp_HLL: 8 CGW_SG
 SG_ HLL_DiagResp  : 7|64@0+ (1,0) [0|1] "" SGW_SG

BO_ 1835 DiagResp_PAT: 8 CGW_SG
 SG_ PAT_DiagResp  : 7|64@0+ (1,0) [0|1] "" SGW_SG

BO_ 1796 DiagResp_IVI: 8 CGW_SG
 SG_ IVI_DiagResp  : 7|64@0+ (1,0) [0|1] "" SGW_SG

BO_ 1805 DiagResp_HUD: 8 CGW_SG
 SG_ HUD_DiagResp  : 7|64@0+ (1,0) [0|1] "" SGW_SG

BO_ 1817 DiagResp_MFP_RC: 8 CGW_SG
 SG_ MFP_RC_DiagResp  : 7|64@0+ (1,0) [0|1] "" SGW_SG

BO_ 1814 DiagResp_MFP_FC: 8 CGW_SG
 SG_ MFP_FC_DiagResp  : 7|64@0+ (1,0) [0|1] "" SGW_SG

BO_ 1799 DiagResp_SWP: 8 CGW_SG
 SG_ SWP_DiagResp  : 7|64@0+ (1,0) [0|1] "" SGW_SG

BO_ 1798 DiagResp_Switches: 8 CGW_SG
 SG_ Switches_DiagResp  : 7|64@0+ (1,0) [0|1] "" SGW_SG

BO_ 1812 DiagResp_Switches2: 8 CGW_SG
 SG_ Switches2_DiagResp  : 7|64@0+ (1,0) [0|1] "" SGW_SG

BO_ 1801 DiagResp_HOD_heating: 8 CGW_SG
 SG_ HOD_heating_DiagResp  : 7|64@0+ (1,0) [0|1] "" SGW_SG

BO_ 1806 DiagResp_DIM: 8 CGW_SG
 SG_ DIM_DiagResp  : 7|64@0+ (1,0) [0|1] "" SGW_SG

BO_ 1800 DiagResp_NDT: 8 CGW_SG
 SG_ NDT_DiagResp  : 7|64@0+ (1,0) [0|1] "" SGW_SG

BO_ 1863 DiagResp_POD: 8 CGW_SG
 SG_ POD_DiagResp  : 7|64@0+ (1,0) [0|1] "" SGW_SG

BO_ 1811 DiagResp_BMS: 8 CGW_SG
 SG_ BMS_DiagResp  : 7|64@0+ (1,0) [0|1] "" SGW_SG

BO_ 1864 DiagResp_TCU: 8 CGW_SG
 SG_ TCU_DiagResp  : 7|64@0+ (1,0) [0|1] "" SGW_SG

BO_ 1870 DiagResp_APTC: 8 CGW_SG
 SG_ AIRPTC_DiagResp  : 7|64@0+ (1,0) [0|1] "" SGW_SG

BO_ 1836 DiagResp_VCU: 8 CGW_SG
 SG_ VCU_DiagResp  : 7|64@0+ (1,0) [0|1] "" SGW_SG

BO_ 1858 DiagResp_MCU: 8 CGW_SG
 SG_ MCU_DiagResp  : 7|64@0+ (1,0) [0|1] "" SGW_SG

BO_ 1871 DiagResp_PRND: 8 CGW_SG
 SG_ PRND_DiagResp  : 7|64@0+ (1,0) [0|1] "" SGW_SG

BO_ 1865 DiagResp_EVCOM: 8 CGW_SG
 SG_ EVCOM_DiagResp  : 7|64@0+ (1,0) [0|1] "" SGW_SG

BO_ 1830 DiagResp_IBS: 8 CGW_SG
 SG_ IBS_DiagResp  : 7|64@0+ (1,0) [0|1] "" SGW_SG

BO_ 2041 DiagResp_ACU: 8 CGW_SG
 SG_ ACU_DiagResp  : 7|64@0+ (1,0) [0|1] "" SGW_SG

BO_ 1859 DiagResp_AVAS: 8 CGW_SG
 SG_ AVAS_DiagResp  : 7|64@0+ (1,0) [0|1] "" SGW_SG

BO_ 1833 DiagResp_EPS: 8 CGW_SG
 SG_ EPS_DiagResp  : 7|64@0+ (1,0) [0|1] "" SGW_SG

BO_ 1856 DiagResp_ADCU: 8 CGW_SG
 SG_ ADCU_DiagResp  : 7|64@0+ (1,0) [0|1] "" SGW_SG

BO_ 1027 SGW_DiagInfor: 8 SGW_SG
 SG_ SGW_DTC_Number  : 7|8@0+ (1,0) [0|255] "" CGW_SG

BO_ 1029 ERA_DiagInfor: 8 SGW_SG
 SG_ ERA_DTC_Number  : 7|8@0+ (1,0) [0|255] "" CGW_SG

BO_ 1034 CBM_DiagInfor: 8 SGW_SG
 SG_ CBM_DTC_Number  : 7|8@0+ (1,0) [0|255] "" CGW_SG

BO_ 1026 CGW_DiagInfor: 8 CGW_SG
 SG_ CGW_DTC_Number  : 7|8@0+ (1,0) [0|255] "" SGW_SG

BO_ 1025 BCM1_DiagInfor: 8 CGW_SG
 SG_ BCM1_DTC_Number  : 7|8@0+ (1,0) [0|255] "" SGW_SG

BO_ 1050 BCM2_DiagInfor: 8 CGW_SG
 SG_ BCM2_DTC_Number  : 7|8@0+ (1,0) [0|255] "" SGW_SG

BO_ 1051 SCUL_DiagInfor: 8 CGW_SG
 SG_ SCUL_DTC_Number  : 7|8@0+ (1,0) [0|255] "" SGW_SG

BO_ 1052 SCUR_DiagInfor: 8 CGW_SG
 SG_ SCUR_DTC_Number  : 7|8@0+ (1,0) [0|255] "" SGW_SG

BO_ 1055 WCBS1_DiagInfor: 8 CGW_SG
 SG_ WCBS1_DTC_Number  : 7|8@0+ (1,0) [0|255] "" SGW_SG

BO_ 1056 WCBS2_DiagInfor: 8 CGW_SG
 SG_ WCBS2_DTC_Number  : 7|8@0+ (1,0) [0|255] "" SGW_SG

BO_ 1071 DCM_FL_DiagInfor: 8 CGW_SG
 SG_ DCM_FL_DTC_Number  : 7|8@0+ (1,0) [0|255] "" SGW_SG

BO_ 1083 DCM_FR_DiagInfor: 8 CGW_SG
 SG_ DCM_FR_DTC_Number  : 7|8@0+ (1,0) [0|255] "" SGW_SG

BO_ 1079 DCM_RL_DiagInfor: 8 CGW_SG
 SG_ DCM_RL_DTC_Number  : 7|8@0+ (1,0) [0|255] "" SGW_SG

BO_ 1084 DCM_RR_DiagInfor: 8 CGW_SG
 SG_ DCM_RR_DTC_Number  : 7|8@0+ (1,0) [0|255] "" SGW_SG

BO_ 1086 HLR_DiagInfor: 8 CGW_SG
 SG_ HLR_DTC_Number  : 7|8@0+ (1,0) [0|255] "" SGW_SG

BO_ 1053 HLL_DiagInfor: 8 CGW_SG
 SG_ HLL_DTC_Number  : 7|8@0+ (1,0) [0|255] "" SGW_SG

BO_ 1067 PAT_DiagInfor: 8 CGW_SG
 SG_ PAT_DTC_Number  : 7|8@0+ (1,0) [0|255] "" SGW_SG

BO_ 1088 ADCU_DiagInfor: 8 CGW_SG
 SG_ ADCU_DTC_Number  : 7|8@0+ (1,0) [0|255] "" SGW_SG

BO_ 1092 IVI_DiagInfor: 8 CGW_SG
 SG_ IVI_DTC_Number  : 7|8@0+ (1,0) [0|255] "" SGW_SG

BO_ 1037 HUD_DiagInfor: 8 CGW_SG
 SG_ HUD_DTC_Number  : 7|8@0+ (1,0) [0|255] "" SGW_SG

BO_ 1049 MFP_RC_DiagInfor: 8 CGW_SG
 SG_ MFP_RC_DTC_Number  : 7|8@0+ (1,0) [0|255] "" SGW_SG

BO_ 1046 MFP_FC_DiagInfor: 8 CGW_SG
 SG_ MFP_FC_DTC_Number  : 7|8@0+ (1,0) [0|255] "" SGW_SG

BO_ 1031 SWP_DiagInfor: 8 CGW_SG
 SG_ SWP_DTC_Number  : 7|8@0+ (1,0) [0|255] "" SGW_SG

BO_ 1030 Switches_DiagInfor: 8 CGW_SG
 SG_ Switches_DTC_Number  : 7|8@0+ (1,0) [0|255] "" SGW_SG

BO_ 1033 HOD_heating_DiagInfor: 8 CGW_SG
 SG_ HOD_heating_DTC_Number  : 7|8@0+ (1,0) [0|255] "" SGW_SG

BO_ 1038 DIM_DiagInfor: 8 CGW_SG
 SG_ DIM_DTC_Number  : 7|8@0+ (1,0) [0|255] "" SGW_SG

BO_ 1032 NDT_DiagInfor: 8 CGW_SG
 SG_ NDT_DTC_Number  : 7|8@0+ (1,0) [0|255] "" SGW_SG

BO_ 1095 POD_DiagInfor: 8 CGW_SG
 SG_ POD_DTC_Number  : 7|8@0+ (1,0) [0|255] "" SGW_SG

BO_ 1043 BMS_DiagInfor: 8 CGW_SG
 SG_ BMS_DTC_Number  : 7|8@0+ (1,0) [0|255] "" SGW_SG

BO_ 1096 TCU_DiagInfor: 8 CGW_SG
 SG_ TCU_DTC_Number  : 7|8@0+ (1,0) [0|255] "" SGW_SG

BO_ 1102 APTC_DiagInfor: 8 CGW_SG
 SG_ AIRPTC_DTC_Number  : 7|8@0+ (1,0) [0|255] "" SGW_SG

BO_ 1068 VCU_DiagInfor: 8 CGW_SG
 SG_ VCU_DTC_Number  : 7|8@0+ (1,0) [0|255] "" SGW_SG

BO_ 1090 MCU_DiagInfor: 8 CGW_SG
 SG_ MCU_DTC_Number  : 7|8@0+ (1,0) [0|255] "" SGW_SG

BO_ 1103 PRND_DiagInfor: 8 CGW_SG
 SG_ PRND_DTC_Number  : 7|8@0+ (1,0) [0|255] "" SGW_SG

BO_ 1097 EVCOM_DiagInfor: 8 CGW_SG
 SG_ EVCOM_DTC_Number  : 7|8@0+ (1,0) [0|255] "" SGW_SG

BO_ 1062 IBS_DiagInfor: 8 CGW_SG
 SG_ IBS_DTC_Number  : 7|8@0+ (1,0) [0|255] "" SGW_SG

BO_ 1273 ACU_DiagInfor: 8 CGW_SG
 SG_ ACU_DTC_Number  : 7|8@0+ (1,0) [0|255] "" SGW_SG

BO_ 1091 AVAS_DiagInfor: 8 CGW_SG
 SG_ AVAS_DTC_Number  : 7|8@0+ (1,0) [0|255] "" SGW_SG

BO_ 1065 EPS_DiagInfor: 8 CGW_SG
 SG_ EPS_DTC_Number  : 7|8@0+ (1,0) [0|255] "" SGW_SG

BO_ 947 MCU_Fault_01: 8 CGW_SG
 SG_ MCU_FaultNum1  : 7|8@0+ (1,0) [0|255] "" SGW_SG
 SG_ MCU_FaultNum2  : 15|8@0+ (1,0) [0|255] "" SGW_SG
 SG_ MCU_FaultNum3  : 23|8@0+ (1,0) [0|255] "" SGW_SG
 SG_ MCU_FaultNum4  : 31|8@0+ (1,0) [0|255] "" SGW_SG
 SG_ MCU_FaultNum5  : 39|8@0+ (1,0) [0|255] "" SGW_SG
 SG_ MCU_FaultNum6  : 47|8@0+ (1,0) [0|255] "" SGW_SG
 SG_ MCU_FaultNum7  : 55|8@0+ (1,0) [0|255] "" SGW_SG
 SG_ MCU_FaultNum8  : 63|8@0+ (1,0) [0|255] "" SGW_SG

BO_ 948 MCU_Fault_02: 8 CGW_SG
 SG_ MCU_FaultNum9  : 7|8@0+ (1,0) [0|255] "" SGW_SG
 SG_ MCU_FaultNum10  : 15|8@0+ (1,0) [0|255] "" SGW_SG
 SG_ MCU_TotalFaultNum  : 23|8@0+ (1,0) [0|255] "" SGW_SG

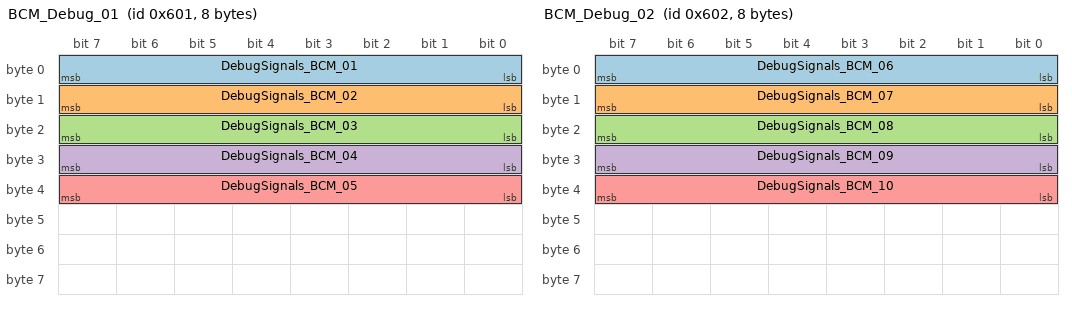
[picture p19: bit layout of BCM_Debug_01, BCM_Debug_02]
BO_ 1537 BCM_Debug_01: 8 CGW_SG
 SG_ DebugSignals_BCM_01  : 7|8@0+ (1,0) [0|255] "" SGW_SG
 SG_ DebugSignals_BCM_02  : 15|8@0+ (1,0) [0|255] "" SGW_SG
 SG_ DebugSignals_BCM_03  : 23|8@0+ (1,0) [0|255] "" SGW_SG
 SG_ DebugSignals_BCM_04  : 31|8@0+ (1,0) [0|255] "" SGW_SG
 SG_ DebugSignals_BCM_05  : 39|8@0+ (1,0) [0|255] "" SGW_SG

BO_ 1538 BCM_Debug_02: 8 CGW_SG
 SG_ DebugSignals_BCM_06  : 7|8@0+ (1,0) [0|255] "" SGW_SG
 SG_ DebugSignals_BCM_07  : 15|8@0+ (1,0) [0|255] "" SGW_SG
 SG_ DebugSignals_BCM_08  : 23|8@0+ (1,0) [0|255] "" SGW_SG
 SG_ DebugSignals_BCM_09  : 31|8@0+ (1,0) [0|255] "" SGW_SG
 SG_ DebugSignals_BCM_10  : 39|8@0+ (1,0) [0|255] "" SGW_SG

CM_ SG_ 852 IVI_FLAmbientColorReq "Driver door color require";
CM_ SG_ 852 IVI_FRAmbientColorReq "FR door color require";
CM_ SG_ 852 IVI_RLAmbientColorReq "RL door color require";
CM_ SG_ 852 IVI_RRAmbientColorReq "RR door color require";
CM_ SG_ 852 IVI_IPAmbientColorReq "IP door color require";
CM_ SG_ 852 IVI_FLAmbientLightReq "DCM_FL atmosphere lamp control signal";
CM_ SG_ 852 IVI_FRAmbientLightReq "DCM_FR atmosphere lamp control signal";
CM_ SG_ 852 IVI_RLAmbientLightReq "DCM_RL atmosphere lamp control signal";
CM_ SG_ 852 IVI_RRAmbientLightReq "DCM_RR atmosphere lamp control signal";
CM_ SG_ 852 IVI_IPAmbientLightReq "Instrument atmosphere lamp control signal";
CM_ SG_ 575 SGW_L_RearSeatHeatSet "Rear left seat heating level setting";
CM_ SG_ 575 SGW_R_RearSeatHeatSet "Rear right seat heating level setting";
CM_ SG_ 575 SGW_DrSeatWelcomeLevelSet "Driver Seat welcome position level setting";
CM_ SG_ 575 SGW_PsSeatWelcomeLevelSet "Passenger Seat welcome position level setting";
CM_ SG_ 575 SGW_MirrorAutoTurnDownSet "Automatic rearview mirror down control signal";
CM_ SG_ 575 SGW_WelcomeOnOffSet "Welcome set signal";
CM_ SG_ 575 SGW_PassWelcomeOnOffSet "Passenger welcome set signal";
CM_ SG_ 256 IVI_ResetReq "reset switch control";
CM_ SG_ 256 IVI_AutoScreenBacklight "Automatically adjust screen backlight brightness";
CM_ SG_ 256 IVI_ScreenBrightnessSet "Set Screen backlight brightness";
CM_ SG_ 256 IVI_AVASOnOffSet "AVAS ON OFF set";
CM_ SG_ 256 IVI_AVASSoundSet "Control signal AVAS sound selection";
CM_ SG_ 256 IVI_PassAirbagOpenSet "Passenger airbag open control.";
CM_ SG_ 256 IVI_WCBSReminderSet "Wireless Charging Function Set";
CM_ SG_ 256 IVI_HazardWarmReq "The voice hazard warning require";
CM_ SG_ 256 IVI_ThanksHazardWarmReq "Thanks other driver the light request";
CM_ SG_ 256 IVI_WelInteriorLightSet "SWP setup to automatically activate the welcome light";
CM_ SG_ 256 IVI_PriorSoundSet "Enable/Disable sound reminder prior door automatic via speaker on SWP";
CM_ SG_ 256 IVI_FrontKeepOpenSet "Enable/Disable the “keep the front door opened” on SWP";
CM_ SG_ 259 IVI_L_DsSeatBackPos "Driver seat backrest percentage request";
CM_ SG_ 259 IVI_L_DsSeatHeightPos "Driver seat height percentage request";
CM_ SG_ 259 IVI_L_DsSeatSlidePos "Driver seat slide percentage request";
CM_ SG_ 259 IVI_DrSeatHeatLevelSet "Driver seat heating level setting signal";
CM_ SG_ 259 IVI_DrSeatWelcomeLevelSet "Driver Seat welcome position level setting";
CM_ SG_ 260 IVI_R_DsSeatSlidePos "Passenger seat slide percentage request";
CM_ SG_ 260 IVI_R_DsSeatHeightPos "Passenger seat height percentage request";
CM_ SG_ 260 IVI_R_DsSeatBackPos "Passenger seat backrest percentage request";
CM_ SG_ 260 IVI_PassSeatHeatLevelSet "passenger seat heating control signal";
CM_ SG_ 260 IVI_PsSeatWelcomeLevelSet "Passenger Seat welcome position level setting";
CM_ SG_ 264 SGW_FR_FrontRearReq "Passenger forward and backward request";
CM_ SG_ 264 SGW_FR_HeightMotorReq "Passenger height request";
CM_ SG_ 264 SGW_FR_BackrestMotorReq "Passenger backrest request";
CM_ SG_ 710 IVI_StWAnglePos "Steering wheel angle position request";
CM_ SG_ 710 IVI_StWLengthPos "Steering wheel length position request";
CM_ SG_ 563 IVI_MirrorFold_UnfoldSet "IVI Mirror fold or unfold button signal";
CM_ SG_ 563 IVI_MirrorAutoTurnDownSet "Automatic rearview mirror down control signal";
CM_ SG_ 563 IVI_MirrorAutoFoldUnfoldSet "Automatic folding of exterior mirrors sets the signal";
CM_ SG_ 563 IVI_LeftMirrorHorizontalPos "Left and right position of left rearview mirror (percentage)";
CM_ SG_ 563 IVI_LeftMirrorVerticalPos "Up and down positions of the left rearview mirror (percentage)";
CM_ SG_ 563 IVI_RightMirrorHorizontalPos "Right rearview mirror left and right position (percentage)";
CM_ SG_ 563 IVI_RightMirrorVerticalPos "Right rearview mirror up and down position (percentage)";
CM_ SG_ 574 IVI_FLDoorLockSet "FL unlocked request";
CM_ SG_ 574 IVI_FRDoorLockSet "FR unlocked request";
CM_ SG_ 574 IVI_RLDoorLockSet "RL unlocked request";
CM_ SG_ 574 IVI_RRDoorLockSet "RR unlocked request";
CM_ SG_ 574 IVI_PassWindowLockSet "Passenger window lock control";
CM_ SG_ 574 IVI_ModeEnterReq "IVI mode entry request";
CM_ SG_ 689 IVI_HUDALTITUDESet "height setting signal";
CM_ SG_ 689 IVI_HUDOnOffSet "HUD switch control";
CM_ SG_ 561 IVI_ESCOffSet "ESC On/Off switch setting signal";
CM_ SG_ 561 IVI_TPMS_Reset "Reset TPMS";
CM_ SG_ 561 IVI_HDCOffSet "HDC On/Off switch setting signal";
CM_ SG_ 561 IVI_AVHSet "AVH On/Off switch setting signal";
CM_ SG_ 561 IVI_SteeringModeSet "Steering mode set";
CM_ SG_ 561 IVI_BrakeCompensateCmd "Brake compensation setting instruction";
CM_ SG_ 561 IVI_CRLevelSet "The user specified  energy recovery level";
CM_ SG_ 790 VCU_OdometerInfor "Total mileage";
CM_ SG_ 790 VCU_OdometerInforValid "VCU total mileage effective marker signal";
CM_ SG_ 790 VCU_VINComparisonResults "VIN Comparison Results";
CM_ SG_ 945 SGW_OdometerInfor "SGW sends backup total mileage signal";
CM_ SG_ 945 SGW_OdometerInforValid "SGW external total mileage effective marker signal";
CM_ SG_ 946 SGW_VIN "SGW sends the last eight digits of the VIN";
CM_ SG_ 693 IVI_AppointChargeCmd "Charging end command";
CM_ SG_ 693 IVI_ForwardVmaxlimitSw "maximum speed limit in D gear setting";
CM_ SG_ 693 IVI_KeepWarmRequest "Keeping warm function opening instruction";
CM_ SG_ 693 IVI_LockACPlug "Unlock electronic lock by IVI";
CM_ SG_ 693 IVI_LV_LimitPop "Operation pop-up prompt";
CM_ SG_ 694 IVI_GearRequest "Gear request";
CM_ SG_ 261 SGW_RemoteAirCondAUTOReq "Remote Air-Conditioner AUTO module switch request signal";
CM_ SG_ 261 SGW_RemoteAirCondOnOFFReq "SGW remote air conditioning switch control signal";
CM_ SG_ 261 SGW_RearDoorAngleSet "SGW rear door angle setting";
CM_ SG_ 261 SGW_FrontDoorAngleSet "SGW front door angle setting";
CM_ SG_ 261 SGW_RemoteFrontDefrostReq "Remote front Defrost command";
CM_ SG_ 261 SGW_RemoteSteerHeatReq "Remote request Steering wheel heating control request";
CM_ SG_ 261 SGW_RemoteDrSeatHeatReq "Remote request master driver heating control request";
CM_ SG_ 261 SGW_LeftChdLockCtrlReq "Left child lock remote control request";
CM_ SG_ 261 SGW_RearDefrostCtrlSet "Remote tailgate window heating command";
CM_ SG_ 261 SGW_RemoteFrontWindHeatReq "Remote control front windshield heating";
CM_ SG_ 261 SGW_RemoteRearMirHeatReq "Remote Rear mirror Heating request";
CM_ SG_ 261 SGW_RemotePassSeatHeatReq "Remote request passenger heating control request";
CM_ SG_ 261 SGW_oneTouchCoolSet "Max cooling setting";
CM_ SG_ 261 SGW_RemoteRearWindHeatReq "Remote control rear windshield heating";
CM_ SG_ 261 SGW_TakePicCtrl "take picture control.";
CM_ SG_ 261 SGW_RemoteACOnOffReq "SGW remote AC on off request";
CM_ SG_ 261 SGW_RightChdLockCtrlReq "Right child lock remote control request";
CM_ SG_ 261 SGW_RemoteTailgateLockCtrlReq "SGW remote tailgate control request.";
CM_ SG_ 261 SGW_HDCOffSet "HDC On/Off switch setting signal";
CM_ SG_ 261 SGW_AVHSet "AVH On/Off switch setting signal";
CM_ SG_ 261 SGW_SteeringModeSet "Steering mode set";
CM_ SG_ 261 SGW_AVASSoundSet "Control signal AVAS sound selection";
CM_ SG_ 261 SGW_DriveModeSet "Driving mode set.";
CM_ SG_ 261 SGW_ImuCarParkBeStolen "IMU Car Park Be Stolen";
CM_ SG_ 262 IVI_HUDScreenBrightnessSet "Set HUD Screen backlight brightness";
CM_ SG_ 263 SGW_AutoCloseWinFunSet "Auto close window function setting via SGW";
CM_ SG_ 263 SGW_RemoteDrvSetTempSteplsReq "Remote driver seat area set temperature";
CM_ SG_ 263 SGW_FrontWiperAutoSet "Front wiper auto mode set";
CM_ SG_ 263 SGW_RemotePassSetTempSteplsReq "Remote passenger seat area set temperature";
CM_ SG_ 263 SGW_AllDoorReq "Four door opening and closing request";
CM_ SG_ 263 SGW_RemoteCarSearchReq "SGW remote search car request.";
CM_ SG_ 263 SGW_RemoteLockCtrlReq "Remote lock control command";
CM_ SG_ 263 SGW_RRDoorReq "SGW right rear door open close request";
CM_ SG_ 263 SGW_RLDoorReq "SGW Left Rear Door Open/Close Request";
CM_ SG_ 263 SGW_FRDoorReq "SGW Right Front Door Open/Close Request";
CM_ SG_ 263 SGW_FLDoorReq "SGW Left Front Door Open/Close Request";
CM_ SG_ 263 SGW_WelInteriorLightSet "APP set up to automatically activate the welcome light";
CM_ SG_ 263 SGW_CarSharingLightSet "Car sharing light set";
CM_ SG_ 263 SGW_CarSharingColorSet "Car sharing color set";
CM_ SG_ 263 SGW_CarSharingTimeSet "Car sharing welcome light runtime set";
CM_ SG_ 263 SGW_FRDomeLampSet "Front Roof Lamp ON/OFF set";
CM_ SG_ 263 SGW_RRDomeLampSet "Rear Roof Lamp ON/OFF set";
CM_ SG_ 316 SGW_L_MirrorMainHorizontalPos "Left exterior mirror horizontal automatic adjustment request in main mode";
CM_ SG_ 316 SGW_L_MirrorMainVerticalPos "Left exterior mirror vertical automatic adjustment request in main mode";
CM_ SG_ 316 SGW_R_MirrorMainHorizontalPos "Right exterior mirror horizontal automatic adjustment request in main mode";
CM_ SG_ 316 SGW_R_MirrorMainVerticalPos "Right exterior mirror vertical automatic adjustment request in main mode";
CM_ SG_ 316 SGW_L_MirrorTiltHorizontalPos "Left exterior mirror horizontal automatic adjustment request in tilt mode";
CM_ SG_ 316 SGW_L_MirrorTiltVerticalPos "Left exterior mirror vertical automatic adjustment request in tilt mode";
CM_ SG_ 316 SGW_R_MirrorTiltHorizontalPos "Right exterior mirror horizontal automatic adjustment request in tilt mode";
CM_ SG_ 316 SGW_R_MirrorTiltVerticalPos "Right exterior mirror vertical automatic adjustment request in tilt mode";
CM_ SG_ 315 SGW_DrSeatSlidePos "Driver seat slide automatic adjustment request";
CM_ SG_ 315 SGW_DrSeatHeightPos "Driver seat height automatic adjustment request";
CM_ SG_ 315 SGW_DrSeatBackPos "Driver seat backrest automatic adjustment request";
CM_ SG_ 315 SGW_StWLengthPos "Steering wheel length automatic adjustment request";
CM_ SG_ 315 SGW_StWAnglePos "Steering wheel angle automatic adjustment request";
CM_ SG_ 315 SGW_MirrorAutoFoldUnfoldSet "Exterior mirrors automatic folding and unfolding setting request";
CM_ SG_ 315 SGW_WCBSReminderSet "Wireless charging device forget reminder setting request";
CM_ SG_ 315 SGW_AutoLmpSet "Auto light control signal";
CM_ SG_ 315 SGW_DippedBeamSet "Dipped beam control signal";
CM_ SG_ 315 SGW_HUDHeightSet "HUD height control.";
CM_ SG_ 315 SGW_HUDBrightnessSet "HUD Brightnesscontrol.";
CM_ SG_ 314 SGW_RemoteFLWinPosiCtlCmd "Remote control FL window";
CM_ SG_ 314 SGW_RemoteFRWinPosiCtlCmd "Remote control FR window";
CM_ SG_ 314 SGW_RemoteRLWinPosiCtlCmd "Remote control RL window";
CM_ SG_ 314 SGW_RemoteRRWinPosiCtlCmd "Remote control RR window";
CM_ SG_ 314 SGW_PassWindowLockSet "Passenger window lock control via user profile";
CM_ SG_ 314 SGW_LeftKeyReHornMode "Horn reminder mode for keys left in the car via user profile";
CM_ SG_ 314 SGW_LockDoorOpenReHornMode "Reminder Lock event with Open door state mode via user profile";
CM_ SG_ 314 SGW_AntiTheftReHornMode "Anti-theft horn alert mode via user profile";
CM_ SG_ 314 SGW_PosnLmpSet "Control location lights via APP and cloud";
CM_ SG_ 314 SGW_AutoLampSenReq "The dipped beam headlamp automatic control sensitivity setting signal via user profile";
CM_ SG_ 314 SGW_CornerLampSet "Auto corner lamp set signal via user profile";
CM_ SG_ 314 SGW_BacklightAutoSet "Mobile APP setting steering wheel backlight automatic control";
CM_ SG_ 314 SGW_BacklightadjustSet "Steering wheel backlight brightness setting signal";
CM_ SG_ 562 SGW_DrvSetTempSteplsReq "driver seat area set temperature";
CM_ SG_ 562 SGW_DemistReq "Demist request";
CM_ SG_ 562 SGW_HVACBatterySaveModeSetReq "HVAC battery save mode set request";
CM_ SG_ 562 SGW_PassSetTempSteplsReq "passenger seat area set temperature";
CM_ SG_ 562 SGW_AirCondAUTOReq "Air AUTO module switch request signal";
CM_ SG_ 562 SGW_DualReq "dual-zone synchronous mode switching request signal";
CM_ SG_ 562 SGW_AirDistributionModeReq "Air distribution mode request";
CM_ SG_ 562 SGW_FrontDefrostReq "Front Defrost request";
CM_ SG_ 562 SGW_AqsReq "AQS request";
CM_ SG_ 562 SGW_ClimateSystemStsReq "Climate system state request signal";
CM_ SG_ 562 SGW_ACCmprStsReq "AC state request signal";
CM_ SG_ 562 SGW_AirCirclnReq "Cycle mode request";
CM_ SG_ 562 SGW_BlowersteplsSpdReq "Blower Stepless Speed request";
CM_ SG_ 562 SGW_PresetModeEnable "Preset Mode Enable Command";
CM_ SG_ 562 SGW_PresetModeReq "Preset Mode Request";
CM_ SG_ 562 SGW_VentilationModeReq "Ventilation Mode Request";
CM_ SG_ 562 SGW_AirCondEcoSet "ECO mode setting";
CM_ SG_ 560 IVI_DschrgOnOffSet "discharging turn ON or OFF set.";
CM_ SG_ 560 IVI_DriveModeSet "Driving mode set.";
CM_ SG_ 560 IVI_ForwardVmaxAllowed "D-gear maximum speed setting value";
CM_ SG_ 560 IVI_MaxChrgSocSet "Target charge level setting signal";
CM_ SG_ 560 IVI_V2LidisSet "V2L minimum power value set by the user";
CM_ SG_ 564 SGW_TimeInfoSecond "Time informatioin, Second(UTC time)";
CM_ SG_ 564 SGW_TimeInfoMinute "Time informatioin, Minute(UTC time)";
CM_ SG_ 564 SGW_TimeInfoHour "Time informatioin, Hour(UTC time)";
CM_ SG_ 564 SGW_TimeInfoDay "Time informatioin, Day(UTC time)";
CM_ SG_ 564 SGW_TimeInfoMonth "Time informatioin, Month(UTC time)";
CM_ SG_ 564 SGW_TimeInfoYear "Time informatioin, Year(UTC time)";
CM_ SG_ 564 SGW_TimeValid "Time Valid";
CM_ SG_ 659 Checksum_293 "Checksum signal for frame";
CM_ SG_ 659 MessageCounter_293 "Message counter signal for frame";
CM_ SG_ 659 Switches_WiperSelection "Control wiper selection";
CM_ SG_ 659 Switches_MainBeamReq "SW high beam request signal";
CM_ SG_ 659 Switches_ChangeLaneSW "Left and right lane change light switch";
CM_ SG_ 659 Switches_TurnSW "Left and right turn light switch";
CM_ SG_ 659 Switches_BacklightadjustSts "Backlight brightness control signal";
CM_ SG_ 659 Switches_BacklightAutoSts "Steering wheel backlight automatic control setting status";
CM_ SG_ 657 Checksum_291 "Checksum signal for frame";
CM_ SG_ 657 MessageCounter_291 "Message counter signal for frame";
CM_ SG_ 657 Switches_R_Up_Cmd "Up button in the right area of the steering wheel";
CM_ SG_ 657 Switches_R_Down_Cmd "Down button in the right area of the steering wheel";
CM_ SG_ 657 Switches_R_Left_Cmd "Left button in the Right area of the steering wheel";
CM_ SG_ 657 Switches_R_Right_Cmd "Right button in the Right area of the steering wheel";
CM_ SG_ 657 Switches_R_Accept_Cmd "OK button in the right area of the steering wheel";
CM_ SG_ 657 Switches_L_Up_Cmd "EN:Up button in the left area of the steering wheel";
CM_ SG_ 657 Switches_L_Down_Cmd "EN:Down button in the left area of the steering wheel";
CM_ SG_ 657 Switches_L_Left_Cmd "EN:Left button in the left area of the steering wheel";
CM_ SG_ 657 Switches_L_Right_Cmd "EN:Right button in the left area of the steering wheel";
CM_ SG_ 657 Switches_L_Accept_Cmd "EN:OK button in the left area of the steering wheel";
CM_ SG_ 657 Switches_ButtonFaultWarn "Steering wheel button fault warn";
CM_ SG_ 271 Switches_L_SWipe_Cmd "Left sliding signal of steering wheel";
CM_ SG_ 608 TCU_TMSTotalPwrCnsmp "TMS TotalPower Consumption";
CM_ SG_ 608 TCU_EVCompState "Compressor work state";
CM_ SG_ 608 TCU_TMSState "Thermal management control state";
CM_ SG_ 608 TCU_TMSFaultLevel "TMS SYSTEM Error level";
CM_ SG_ 608 TCU_HvOnReq "Forbidden to disconnect the high voltage (thermal management) request";
CM_ SG_ 608 TCU_HVCHState "Water heater work state";
CM_ SG_ 608 TCU_APTCState "Air heater work state";
CM_ SG_ 608 TCU_TMSTotoalPwrReq "AC system total power request";
CM_ SG_ 608 TCU_BattTMState "TCU battery Thermal management system status";
CM_ SG_ 608 TCU_HVPwrState "TCU High voltage supply Status";
CM_ SG_ 608 TCU_HVACACState "Front HVAC Cool Or Heat Or Vent Auto State";
CM_ SG_ 608 TCU_APTCLeftMaxPowerLimit "Limit power";
CM_ SG_ 608 TCU_APTCRightMaxPowerLimit "Limit power";
CM_ SG_ 609 TCU_HVCHHighVoltage "HVCH High Voltage Measurement";
CM_ SG_ 609 TCU_APTCLeftCmd "Actual power output percent of APTC Left zone";
CM_ SG_ 609 TCU_APTCRightCmd "Actual power output percent of APTC Right zone";
CM_ SG_ 609 TCU_CompTargetSpeed "Compressor Target Speed";
CM_ SG_ 609 TCU_APTC1Enable "AIR PTC Operate Enable Command";
CM_ SG_ 609 TCU_CompEnable "Compressor Operate Enable Command";
CM_ SG_ 609 TCU_CompMaxAllowPwrCmsp "Compressor Maximum Allowed Power Comsuption";
CM_ SG_ 609 TCU_HVCHHVDCCurrent "Current Draw of HV-PTC";
CM_ SG_ 610 TCU_CabinTemperature "Cabin temperature";
CM_ SG_ 610 TCU_CabinTemperatureValid "Cabin temperature Valid";
CM_ SG_ 768 TCU_AirCondAUTOSts "AUTO status";
CM_ SG_ 768 TCU_AirCirclnSts "Cycle Mode status";
CM_ SG_ 768 TCU_AirCondEcoSetSts "ECO status";
CM_ SG_ 768 TCU_SelfDryingSetSts "Self-Drying Set status";
CM_ SG_ 768 TCU_DrvTempSts "DrvTemp status";
CM_ SG_ 768 TCU_AqsSts "AQS status";
CM_ SG_ 768 TCU_DualSts "Temperature zone status";
CM_ SG_ 768 TCU_PassTempSts "PasstTemp status";
CM_ SG_ 768 TCU_CoolantLowWarnReq "Coolant Low Warn";
CM_ SG_ 768 TCU_FreonLowWarnReq "Freon Low alarm";
CM_ SG_ 768 TCU_BlowerSpdSts "Air volume status";
CM_ SG_ 768 TCU_AirDistributionModeSts "Air distribution mode status";
CM_ SG_ 768 TCU_PresetModeSts "Preset Mode Status";
CM_ SG_ 768 TCU_VentilationModeSts "Ventilation Mode Status";
CM_ SG_ 768 TCU_ACCmprSts "AC status signal";
CM_ SG_ 768 TCU_ClimateSystemSts "Climate system state feedback signal";
CM_ SG_ 768 TCU_PowerLimitSts "The power limit status of the air conditioner";
CM_ SG_ 768 TCU_OutsideAQSLevel "Outdoor air quality rating";
CM_ SG_ 768 TCU_WindowClosRemind "Window closing reminder";
CM_ SG_ 768 TCU_DemistSts "Demist status";
CM_ SG_ 793 VCU_BS_IBSBatSOC "LV Battery SOC";
CM_ SG_ 793 VCU_BS_Current "LV Battery current(Route Lin signal ' BS_BatCrntRawVal')";
CM_ SG_ 793 VCU_BS_IndicatorSts "Battery failure";
CM_ SG_ 793 VCU_BS_LV_Batt "LV Battery voltage(Route Lin signal 'BS_BatVltHIRes')";
CM_ SG_ 793 VCU_WakeUpStatus "VCU Wake Up Status";
CM_ SG_ 793 VCU_BS_Resistance "Internal resistance of Battery";
CM_ SG_ 546 VCU_DCFCCurrent "DC charging current calculated by VCU";
CM_ SG_ 546 VCU_BrakeCompensateStatus "Brake compensation open state";
CM_ SG_ 546 VCU_ChargeProcessComment "Abnormal prompt in charging stage";
CM_ SG_ 546 VCU_EnergyV2L "VCU feedback discharge quantity signal";
CM_ SG_ 546 VCU_MemoryChargeFault "Charging fault status of VCU memory";
CM_ SG_ 547 VCU_ForwardVmaxlimitStatus "maximum speed limit status in D gear";
CM_ SG_ 547 VCU_ManuallyUnlockComment "Manual unlock electronic lock reminder signal";
CM_ SG_ 549 VCU_DisChgPowerLimit "Discharge power limitation";
CM_ SG_ 549 VCU_PermitPackPTC "PackPTC relay close permit instruction";
CM_ SG_ 549 VCU_DisplayMileage "VCU Dynamic Mileage";
CM_ SG_ 549 VCU_MCUPower "MCU real-time power consumption";
CM_ SG_ 210 Checksum_0D2 "Checksum signal for frame";
CM_ SG_ 210 MessageCounter_0D2 "Message counter signal for frame";
CM_ SG_ 210 VCU_AccelerationPedal "Acceleration Pedal percentage";
CM_ SG_ 210 VCU_AccelerationPedalValid "Acceleration Pedal percentage valid status";
CM_ SG_ 210 VCU_EPBReq "VCU request EPB";
CM_ SG_ 210 VCU_TargetGear "Target Gear position";
CM_ SG_ 210 VCU_VehicleSpeed "VCU calculates the output vehicle speed";
CM_ SG_ 210 VCU_VehicleSpeedValid "Speed Validity Flag";
CM_ SG_ 210 VCU_VirtualACPedal "Virtual acceleration Pedal percentage";
CM_ SG_ 210 VCU_VirtualACPedalValid "Virtual acceleration Pedal percentage valid status";
CM_ SG_ 210 VCU_VLCTorqueRequestActive "Is the VCU responding to VLC torque request function activated";
CM_ SG_ 210 VCU_VLCTorqueRequestAvailable "Is VCU available to respond to VLC torque requests";
CM_ SG_ 209 Checksum_0D1 "Checksum signal for frame";
CM_ SG_ 209 MessageCounter_0D1 "Message counter signal for frame";
CM_ SG_ 209 VCU_IsoMeasurementSwitch "Insulation detection enable instruction.";
CM_ SG_ 209 VCU_RequestedModeBMS "Interface to request eletric energy storage target mode";
CM_ SG_ 209 VCU_HVStatus "HV System state";
CM_ SG_ 209 VCU_ChargeStatus "Charge state";
CM_ SG_ 209 VCU_LimitLevel "Low-voltage energy management limit level";
CM_ SG_ 209 VCU_ActDriveMode "Actual drive mode";
CM_ SG_ 209 VCU_DrvModSwitchWarn "Warning dispaly when dirve mode swich";
CM_ SG_ 209 VCU_RegenBrakeLightReqVld "Valid status of Request to illuminate the brake lights from the Powertrain";
CM_ SG_ 209 VCU_RegenBrakeLightRequest "Request to illuminate the brake lights from the Powertrain if regen creates deceleration greater than 0.07g.";
CM_ SG_ 209 VCU_BMSTargetThermLevel "BMS target temperature level";
CM_ SG_ 209 VCU_BMS_Control_of_PosRelay "Request for closing positive relay";
CM_ SG_ 211 Checksum_0D3 "Checksum signal for frame";
CM_ SG_ 211 MessageCounter_0D3 "Message counter signal for frame";
CM_ SG_ 211 VCU_TorqueRequestAvailable "Available status of VCU in response to the external torque request";
CM_ SG_ 211 VCU_TorqueRequestActive "Active status of VCU in response to the external torque request";
CM_ SG_ 211 VCU_RegenTorqueCapValid "brake recovery torque cap valid";
CM_ SG_ 211 VCU_RegenTorqueCap "Maximum brake recovery torque of motor";
CM_ SG_ 211 VCU_DriverTorqueRequest "Driver torque request";
CM_ SG_ 211 VCU_ADASOverride "Override signal";
CM_ SG_ 211 VCU_APSTorqueRequestActive "Is the VCU responding to VLC torque request function activated";
CM_ SG_ 211 VCU_APSTorqueRequestAvailable "Is VCU available to respond to VLC torque requests";
CM_ SG_ 211 VCU_DecelerationReqactive "Request deceleration from IBS";
CM_ SG_ 211 VCU_DecelerationReq "One-pedal VCU deceleration request";
CM_ SG_ 211 VCU_RegStatus "The  energy recovery level";
CM_ SG_ 211 VCU_BrakeCompensateWarn "The warning of brake compensation failure.";
CM_ SG_ 211 VCU_EnergyManagementWarn "The warning of energy management";
CM_ SG_ 544 VCU_VoltageDemandLV "Desired voltage of the DCDC converter LV side (buck mode 14.1v)";
CM_ SG_ 544 VCU_RequestedModeDCDC "Requested state of the DCDC converter";
CM_ SG_ 544 VCU_DCDCPowerLimit "DCDC power limit";
CM_ SG_ 791 Checksum_317 "Checksum signal for frame";
CM_ SG_ 791 MessageCounter_317 "Message counter signal for frame";
CM_ SG_ 791 VCU_ReachLimitStd "SOC reaches the limit level prompt";
CM_ SG_ 791 VCU_DriveMotOvrTemp "Over-temp required via GB/T 19836. Additional components may be needed.";
CM_ SG_ 791 VCU_DCDCFail "DCDC failure status indicator";
CM_ SG_ 791 VCU_HVBatOvrTemp "HV battery over temperature indicator";
CM_ SG_ 791 VCU_HVILError "HVIL error (Interlock monitoring device): required via GB/T 19836";
CM_ SG_ 791 VCU_HVInsulResFault "Insulation resistance/creepage distance indication: rrequired via GB/T 19836";
CM_ SG_ 791 VCU_LimpHome "Limp home: GB/T 4094.2, Table 1, No. 3";
CM_ SG_ 791 VCU_BatteryPerformance "Battery degrade performance";
CM_ SG_ 791 VCU_HVBatCriFail "Traction battery failure: GB/T 4094.2, Table 2, No. 1";
CM_ SG_ 791 VCU_CriSysFailure "System failure tell-tale: GB/T 4094.2, Table 2, No. 3";
CM_ SG_ 791 VCU_PlugStatus "Charge and discharge gun connection state";
CM_ SG_ 791 VCU_InvldGearSel "Invalid Gear Selection Flag";
CM_ SG_ 792 Checksum_318 "Checksum signal for frame";
CM_ SG_ 792 MessageCounter_318 "Message counter signal for frame";
CM_ SG_ 792 VCU_MCU_FaultLampReq "MCU failure indicator";
CM_ SG_ 792 VCU_Display_Power "Charge and discharge power (display)";
CM_ SG_ 792 VCU_SystemReady "Ready lamp indicator";
CM_ SG_ 792 VCU_Display_Cur "Charge and discharge current (display)";
CM_ SG_ 792 VCU_maxChargeSOC "Target charging level setting feedback signal";
CM_ SG_ 792 VCU_DischargeEndSoc "Discharge cutoff SOC";
CM_ SG_ 792 VCU_ForwardVmaxAllowed "Maximum speed setting state of D gear";
CM_ SG_ 795 VCU_Display_voltage "Charge and discharge voltage (display)";
CM_ SG_ 148 Checksum_094 "Checksum signal for frame";
CM_ SG_ 148 MessageCounter_094 "Message counter signal for frame";
CM_ SG_ 148 VCU_MotorActualTorqueValid "the actual torque of motor valid";
CM_ SG_ 148 VCU_MotorActualTorque "the actual torque of motor";
CM_ SG_ 148 VCU_WheelTrqACTValid "Actual motor torque on wheel valid";
CM_ SG_ 148 VCU_WheelTrqACT "Actual motor torque on wheel";
CM_ SG_ 150 VCU_MotorSpdReq "Desired speed electric machine";
CM_ SG_ 150 VCU_MaxSpdLimit "Upper limit output speed of electric machine";
CM_ SG_ 150 VCU_MCUActHeatPwr "Desired heating power of electric machine";
CM_ SG_ 149 Checksum_095 "Checksum signal for frame";
CM_ SG_ 149 MessageCounter_095 "Message counter signal for frame";
CM_ SG_ 149 VCU_PWTErrorLevel "Fault level of the power domain";
CM_ SG_ 149 VCU_MCUDesiredTorque "Desired torque electric machine";
CM_ SG_ 149 VCU_KL15eOn "the bit status of KL15e signal";
CM_ SG_ 149 VCU_TCSActive "EN: Tindicates TCS intervention active,TCS will detect spinning wheels and request torque reduction/limitation";
CM_ SG_ 149 VCU_MCUSurgeDamperState "Requested surge damper state";
CM_ SG_ 149 VCU_ActualGear "The actual gear status";
CM_ SG_ 149 VCU_BrakepedalStatus "the break pedal status";
CM_ SG_ 149 VCU_RequestedModeMCU "Request to the electric machine";
CM_ SG_ 149 VCU_TrqThresholdDampgCtl "Threshold torque for damping control";
CM_ SG_ 214 VCU_MaxTorqueGradient "Maximum allowed change rate of actual torque";
CM_ SG_ 214 VCU_MinTorqueLimit "Lower limit output torque of electric machine";
CM_ SG_ 214 VCU_MaxTorqueLimit "Upper limit output torque of electric machine";
CM_ SG_ 214 VCU_CreepTorque "Creep Torque";
CM_ SG_ 214 VCU_SpdLimitActTorque "Speed Limit Actual Torque";
CM_ SG_ 913 VCU_RemainChrgTime "Remaining charging time (displayed)";
CM_ SG_ 913 VCU_HVConnectFault "Local high voltage failure prompt";
CM_ SG_ 913 VCU_ChargeEndReason "Reason for stopping charging";
CM_ SG_ 913 VCU_DischargeEndReason "Reason for stopping discharging";
CM_ SG_ 289 VCU_Enable_DC_Relay "enable: Request for closing DC charging relay";
CM_ SG_ 289 VCU_OBC_Control_of_S2_SW "OBC should accept the control signal from VCU to switch the S2 inside the OBC";
CM_ SG_ 289 VCU_OBC_Control_of_em_lock "OBC should accept the control signal from VCU to lock or unlock the actuator in the Inlet for locking or unlocking the charging plug";
CM_ SG_ 289 VCU_EnableOBC "When VCU receiving OBC Charge Status= Ready and detecting the status of S2 is closed,VCU send enable
When VCU detect that the stop charging condition is met, VUC send disable.";
CM_ SG_ 289 VCU_OBC_ChargeCurrentCommand "OBC output charging current according to this signal.";
CM_ SG_ 545 VCU_RequestedModeTCU "Requested mode of TCU";
CM_ SG_ 545 VCU_TCUPowerAllowed "TCU Maximum Allowed Power Comsuption";
CM_ SG_ 663 WCBS1_Reminder "Forgotten Reminder";
CM_ SG_ 663 WCBS1_ReminderSts "Forgetting reminder setting status";
CM_ SG_ 664 WCBS2_Reminder "Forgotten Reminder";
CM_ SG_ 664 WCBS2_ReminderSts "Forgetting reminder setting status";
CM_ SG_ 317 BCM_SynRequest "Counter sychronization request message";
CM_ SG_ 319 VCU_SynRequest "Counter sychronization request message";
CM_ SG_ 896 CGW_VIN0 "World Manufacturers Identification";
CM_ SG_ 896 CGW_VIN1 "World Manufacturers Identification";
CM_ SG_ 896 CGW_VIN2 "World Manufacturers Identification";
CM_ SG_ 896 CGW_VIN3 "Vehicle Description Section";
CM_ SG_ 896 CGW_VIN4 "Vehicle Description Section";
CM_ SG_ 896 CGW_VIN5 "Vehicle Description Section";
CM_ SG_ 896 CGW_VIN6 "Vehicle Description Section";
CM_ SG_ 896 CGW_VIN7 "Vehicle Description Section";
CM_ SG_ 897 CGW_VIN8 "Vehicle Identification Section";
CM_ SG_ 897 CGW_VIN9 "Vehicle Identification Section";
CM_ SG_ 897 CGW_VIN10 "Vehicle Identification Section";
CM_ SG_ 897 CGW_VIN11 "Vehicle Identification Section";
CM_ SG_ 897 CGW_VIN12 "Vehicle Identification Section";
CM_ SG_ 897 CGW_VIN13 "Vehicle Identification Section";
CM_ SG_ 897 CGW_VIN14 "Vehicle Identification Section";
CM_ SG_ 897 CGW_VIN15 "Vehicle Identification Section";
CM_ SG_ 898 CGW_VIN16 "Vehicle Identification Section";
CM_ SG_ 898 CGW_VERSION1 "Major Release";
CM_ SG_ 898 CGW_VERSION2 "Minor Release";
CM_ SG_ 858 CGW_SGWSts "SGW status at this time";
CM_ SG_ 858 CGW_CGWSts "CGW status at this time";
CM_ SG_ 858 CGW_CBMSts "CBM status at this time";
CM_ SG_ 858 CGW_DCM_FLSts "DCM_FL status at this time";
CM_ SG_ 858 CGW_DCM_FRSts "DCM_FR status at this time";
CM_ SG_ 858 CGW_DCM_RLSts "DCM_RL status at this time";
CM_ SG_ 858 CGW_DCM_RRSts "DCM_RR status at this time";
CM_ SG_ 858 CGW_SCU_LSts "SCU_L status at this time";
CM_ SG_ 858 CGW_SCU_RSts "SCU_R status at this time";
CM_ SG_ 858 CGW_HLRSts "HLR status at this time";
CM_ SG_ 858 CGW_HLLSts "HLL status at this time";
CM_ SG_ 858 CGW_MFP_RCSts "MFP_RC status at this time";
CM_ SG_ 858 CGW_MFP_FCSts "MFP_FC status at this time";
CM_ SG_ 858 CGW_IVISts "IVI  status at this time";
CM_ SG_ 858 CGW_ADCUSts "ADCU status at this time";
CM_ SG_ 858 CGW_VCUSts "VCU  status at this time";
CM_ SG_ 858 CGW_BMSSts "BMS status at this time";
CM_ SG_ 858 CGW_BCMSts "BCM status at this time";
CM_ SG_ 858 CGW_SWPSts "SWP status at this time";
CM_ SG_ 858 CGW_HOD_HeatingSts "HOD_Heating status at this time";
CM_ SG_ 858 CGW_SwichesSts "Swiches status at this time";
CM_ SG_ 858 CGW_PRNDSts "PRND status at this time";
CM_ SG_ 857 SGW_SGWSts "SGW status at this time";
CM_ SG_ 857 SGW_CGWSts "CGW status at this time";
CM_ SG_ 857 SGW_CBMSts "CBM status at this time";
CM_ SG_ 857 SGW_DCM_FLSts "DCM_FL status at this time";
CM_ SG_ 857 SGW_DCM_FRSts "DCM_FR status at this time";
CM_ SG_ 857 SGW_DCM_RLSts "DCM_RL status at this time";
CM_ SG_ 857 SGW_DCM_RRSts "DCM_RR status at this time";
CM_ SG_ 857 SGW_SCU_LSts "SCU_L status at this time";
CM_ SG_ 857 SGW_SCU_RSts "SCU_R status at this time";
CM_ SG_ 857 SGW_HLRSts "HLR status at this time";
CM_ SG_ 857 SGW_HLLSts "HLL status at this time";
CM_ SG_ 857 SGW_MFP_RCSts "MFP_RC status at this time";
CM_ SG_ 857 SGW_MFP_FCSts "MFP_FC status at this time";
CM_ SG_ 857 SGW_IVISts "IVI  status at this time";
CM_ SG_ 857 SGW_ADCUSts "ADCU status at this time";
CM_ SG_ 857 SGW_VCUSts "VCU  status at this time";
CM_ SG_ 857 SGW_BMSSts "BMS status at this time";
CM_ SG_ 857 SGW_BCMSts "BCM status at this time";
CM_ SG_ 857 SGW_SWPSts "SWP status at this time";
CM_ SG_ 857 SGW_HOD_HeatingSts "HOD_Heating status at this time";
CM_ SG_ 857 SGW_SwichesSts "Swiches status at this time";
CM_ SG_ 857 SGW_PRNDSts "PRND status at this time";
CM_ SG_ 1283 SGW_RMR "Repeat Message Request";
CM_ SG_ 1283 SGW_AWB "Active Wakeup Bit";
CM_ SG_ 1283 SGW_PNI "Partial network information Bit";
CM_ SG_ 1283 SGW_PNC0 "Partial Network Cluster-SGW";
CM_ SG_ 1283 SGW_PNC1 "Partial Network Cluster-CGW";
CM_ SG_ 1283 SGW_PNC2 "Partial Network Cluster-CBM";
CM_ SG_ 1283 SGW_PNC3 "Partial Network Cluster-DCM_FL";
CM_ SG_ 1283 SGW_PNC4 "Partial Network Cluster-DCM_FR";
CM_ SG_ 1283 SGW_PNC5 "Partial Network Cluster-DCM_RL";
CM_ SG_ 1283 SGW_PNC6 "Partial Network Cluster-DCM_RR";
CM_ SG_ 1283 SGW_PNC7 "Partial Network Cluster-SCU_L";
CM_ SG_ 1283 SGW_PNC8 "Partial Network Cluster-SCU_R";
CM_ SG_ 1283 SGW_PNC9 "Partial Network Cluster-HLR";
CM_ SG_ 1283 SGW_PNC10 "Partial Network Cluster-HLL";
CM_ SG_ 1283 SGW_PNC11 "Partial Network Cluster-MFP_RC";
CM_ SG_ 1283 SGW_PNC12 "Partial Network Cluster-MFP_FC";
CM_ SG_ 1283 SGW_PNC13 "Partial Network Cluster-IVI";
CM_ SG_ 1283 SGW_PNC14 "Partial Network Cluster-ADCU";
CM_ SG_ 1283 SGW_PNC15 "Partial Network Cluster-VCU";
CM_ SG_ 1283 SGW_PNC16 "Partial Network Cluster-BMS";
CM_ SG_ 1283 SGW_PNC17 "Partial Network Cluster-BCM";
CM_ SG_ 1283 SGW_PNC18 "Partial Network Cluster-SWP";
CM_ SG_ 1283 SGW_PNC19 "Partial Network Cluster-HOD_Heating";
CM_ SG_ 1283 SGW_PNC20 "Partial Network Cluster-Swiches";
CM_ SG_ 1283 SGW_PNC21 "Partial Network Cluster-PRND";
CM_ SG_ 1283 SGW_PNC22 "Partial Network Cluster";
CM_ SG_ 1283 SGW_PNC23 "Partial Network Cluster";
CM_ SG_ 1283 SGW_PNC24 "Partial Network Cluster";
CM_ SG_ 1283 SGW_PNC25 "Partial Network Cluster";
CM_ SG_ 1283 SGW_PNC26 "Partial Network Cluster";
CM_ SG_ 1283 SGW_PNC27 "Partial Network Cluster";
CM_ SG_ 1283 SGW_PNC28 "Partial Network Cluster";
CM_ SG_ 1283 SGW_PNC29 "Partial Network Cluster";
CM_ SG_ 1283 SGW_PNC30 "Partial Network Cluster";
CM_ SG_ 1283 SGW_PNC31 "Partial Network Cluster";
CM_ SG_ 1283 SGW_PNC32 "Partial Network Cluster";
CM_ SG_ 1283 SGW_PNC33 "Partial Network Cluster";
CM_ SG_ 1283 SGW_PNC34 "Partial Network Cluster";
CM_ SG_ 1283 SGW_PNC35 "Partial Network Cluster";
CM_ SG_ 1283 SGW_PNC36 "Partial Network Cluster";
CM_ SG_ 1283 SGW_PNC37 "Partial Network Cluster";
CM_ SG_ 1283 SGW_PNC38 "Partial Network Cluster";
CM_ SG_ 1283 SGW_PNC39 "Partial Network Cluster";
CM_ SG_ 1282 CGW_RMR "Repeat Message Request";
CM_ SG_ 1282 CGW_AWB "Active Wakeup Bit";
CM_ SG_ 1282 CGW_PNI "Partial network information Bit";
CM_ SG_ 1282 CGW_PNC0 "Partial Network Cluster-SGW";
CM_ SG_ 1282 CGW_PNC1 "Partial Network Cluster-CGW";
CM_ SG_ 1282 CGW_PNC2 "Partial Network Cluster-CBM";
CM_ SG_ 1282 CGW_PNC3 "Partial Network Cluster-DCM_FL";
CM_ SG_ 1282 CGW_PNC4 "Partial Network Cluster-DCM_FR";
CM_ SG_ 1282 CGW_PNC5 "Partial Network Cluster-DCM_RL";
CM_ SG_ 1282 CGW_PNC6 "Partial Network Cluster-DCM_RR";
CM_ SG_ 1282 CGW_PNC7 "Partial Network Cluster-SCU_L";
CM_ SG_ 1282 CGW_PNC8 "Partial Network Cluster-SCU_R";
CM_ SG_ 1282 CGW_PNC9 "Partial Network Cluster-HLR";
CM_ SG_ 1282 CGW_PNC10 "Partial Network Cluster-HLL";
CM_ SG_ 1282 CGW_PNC11 "Partial Network Cluster-MFP_RC";
CM_ SG_ 1282 CGW_PNC12 "Partial Network Cluster-MFP_FC";
CM_ SG_ 1282 CGW_PNC13 "Partial Network Cluster-IVI";
CM_ SG_ 1282 CGW_PNC14 "Partial Network Cluster-ADCU";
CM_ SG_ 1282 CGW_PNC15 "Partial Network Cluster-VCU";
CM_ SG_ 1282 CGW_PNC16 "Partial Network Cluster-BMS";
CM_ SG_ 1282 CGW_PNC17 "Partial Network Cluster-BCM";
CM_ SG_ 1282 CGW_PNC18 "Partial Network Cluster-SWP";
CM_ SG_ 1282 CGW_PNC19 "Partial Network Cluster-HOD_Heating";
CM_ SG_ 1282 CGW_PNC20 "Partial Network Cluster-Swiches";
CM_ SG_ 1282 CGW_PNC21 "Partial Network Cluster-PRND";
CM_ SG_ 1282 CGW_PNC22 "Partial Network Cluster";
CM_ SG_ 1282 CGW_PNC23 "Partial Network Cluster";
CM_ SG_ 1282 CGW_PNC24 "Partial Network Cluster";
CM_ SG_ 1282 CGW_PNC25 "Partial Network Cluster";
CM_ SG_ 1282 CGW_PNC26 "Partial Network Cluster";
CM_ SG_ 1282 CGW_PNC27 "Partial Network Cluster";
CM_ SG_ 1282 CGW_PNC28 "Partial Network Cluster";
CM_ SG_ 1282 CGW_PNC29 "Partial Network Cluster";
CM_ SG_ 1282 CGW_PNC30 "Partial Network Cluster";
CM_ SG_ 1282 CGW_PNC31 "Partial Network Cluster";
CM_ SG_ 1282 CGW_PNC32 "Partial Network Cluster";
CM_ SG_ 1282 CGW_PNC33 "Partial Network Cluster";
CM_ SG_ 1282 CGW_PNC34 "Partial Network Cluster";
CM_ SG_ 1282 CGW_PNC35 "Partial Network Cluster";
CM_ SG_ 1282 CGW_PNC36 "Partial Network Cluster";
CM_ SG_ 1282 CGW_PNC37 "Partial Network Cluster";
CM_ SG_ 1282 CGW_PNC38 "Partial Network Cluster";
CM_ SG_ 1282 CGW_PNC39 "Partial Network Cluster";
CM_ SG_ 2047 ALL_DiagReq "Diagnostic request";
CM_ SG_ 2015 FUN_DiagReq "Diagnostic request";
CM_ SG_ 1843 OBD_DiagReq "OBD Diagnostic request";
CM_ SG_ 2016 VCU_OBD_DiagReq "VCU_OBD_Diagnostic request";
CM_ SG_ 2024 VCU_OBD_DiagResp "VCU_OBD_Diagnostic response";
CM_ SG_ 2025 BD_DiagReq "Body-CAN Diagnostic request";
CM_ SG_ 2029 ET_DiagReq "Entertainment-CAN Diagnostic request";
CM_ SG_ 2026 PT_DiagReq "Powertrain-CAN Diagnostic request";
CM_ SG_ 2027 CH_DiagReq "Chassis-CAN Diagnostic request";
CM_ SG_ 1922 CGW_DiagReq "Diagnostic request";
CM_ SG_ 1921 BCM1_DiagReq "Diagnostic request";
CM_ SG_ 1946 BCM2_DiagReq "Diagnostic request";
CM_ SG_ 1947 SCUL_DiagReq "Diagnostic request";
CM_ SG_ 1948 SCUR_DiagReq "Diagnostic request";
CM_ SG_ 1951 WCBS1_DiagReq "Diagnostic request";
CM_ SG_ 1952 WCBS2_DiagReq "Diagnostic request";
CM_ SG_ 1967 DCM_FL_DiagReq "Diagnostic request";
CM_ SG_ 1975 DCM_FR_DiagReq "Diagnostic request";
CM_ SG_ 1979 DCM_RL_DiagReq "Diagnostic request";
CM_ SG_ 1980 DCM_RR_DiagReq "Diagnostic request";
CM_ SG_ 1950 HLR_DiagReq "Diagnostic request";
CM_ SG_ 1949 HLL_DiagReq "Diagnostic request";
CM_ SG_ 1963 PAT_DiagReq "Diagnostic request";
CM_ SG_ 1924 IVI_DiagReq "Diagnostic request";
CM_ SG_ 1933 HUD_DiagReq "Diagnostic request";
CM_ SG_ 1945 MFP_RC_DiagReq "Diagnostic request";
CM_ SG_ 1942 MFP_FC_DiagReq "Diagnostic request";
CM_ SG_ 1927 SWP_DiagReq "Diagnostic request";
CM_ SG_ 1926 Switches_DiagReq "Diagnostic request";
CM_ SG_ 1940 Switches2_DiagReq "Diagnostic request";
CM_ SG_ 1929 HOD_heating_DiagReq "Diagnostic request";
CM_ SG_ 1934 DIM_DiagReq "Diagnostic request";
CM_ SG_ 1928 NDT_DiagReq "Diagnostic request";
CM_ SG_ 1991 POD_DiagReq "Diagnostic request";
CM_ SG_ 1939 BMS_DiagReq "Diagnostic request";
CM_ SG_ 1992 TCU_DiagReq "Diagnostic request";
CM_ SG_ 1998 AIRPTC_DiagReq "Diagnostic request";
CM_ SG_ 1964 VCU_DiagReq "Diagnostic request";
CM_ SG_ 1986 MCU_DiagReq "Diagnostic request";
CM_ SG_ 1999 PRND_DiagReq "Diagnostic request";
CM_ SG_ 1993 EVCOM_DiagReq "Diagnostic request";
CM_ SG_ 1958 IBS_DiagReq "Diagnostic request";
CM_ SG_ 2033 ACU_DiagReq "Diagnostic request";
CM_ SG_ 1961 EPS_DiagReq "Diagnostic request";
CM_ SG_ 1987 AVAS_DiagReq "Diagnostic request";
CM_ SG_ 1984 ADCU_DiagReq "Diagnostic request";
CM_ SG_ 1794 CGW_DiagResp "Diagnostic response";
CM_ SG_ 1793 BCM1_DiagResp "Diagnostic response";
CM_ SG_ 1818 BCM2_DiagResp "Diagnostic response";
CM_ SG_ 1819 SCUL_DiagResp "Diagnostic response";
CM_ SG_ 1820 SCUR_DiagResp "Diagnostic response";
CM_ SG_ 1823 WCBS1_DiagResp "Diagnostic response";
CM_ SG_ 1824 WCBS2_DiagResp "Diagnostic response";
CM_ SG_ 1839 DCM_FL_DiagResp "Diagnostic response";
CM_ SG_ 1847 DCM_FR_DiagResp "Diagnostic response";
CM_ SG_ 1851 DCM_RL_DiagResp "Diagnostic response";
CM_ SG_ 1852 DCM_RR_DiagResp "Diagnostic response";
CM_ SG_ 1822 HLR_DiagResp "Diagnostic response";
CM_ SG_ 1821 HLL_DiagResp "Diagnostic response";
CM_ SG_ 1835 PAT_DiagResp "Diagnostic response";
CM_ SG_ 1796 IVI_DiagResp "Diagnostic response";
CM_ SG_ 1805 HUD_DiagResp "Diagnostic response";
CM_ SG_ 1817 MFP_RC_DiagResp "Diagnostic response";
CM_ SG_ 1814 MFP_FC_DiagResp "Diagnostic response";
CM_ SG_ 1799 SWP_DiagResp "Diagnostic response";
CM_ SG_ 1798 Switches_DiagResp "Diagnostic response";
CM_ SG_ 1812 Switches2_DiagResp "Diagnostic response";
CM_ SG_ 1801 HOD_heating_DiagResp "Diagnostic response";
CM_ SG_ 1806 DIM_DiagResp "Diagnostic response";
CM_ SG_ 1800 NDT_DiagResp "Diagnostic response";
CM_ SG_ 1863 POD_DiagResp "Diagnostic response";
CM_ SG_ 1811 BMS_DiagResp "Diagnostic response";
CM_ SG_ 1864 TCU_DiagResp "Diagnostic response";
CM_ SG_ 1870 AIRPTC_DiagResp "Diagnostic response";
CM_ SG_ 1836 VCU_DiagResp "Diagnostic response";
CM_ SG_ 1858 MCU_DiagResp "Diagnostic response";
CM_ SG_ 1871 PRND_DiagResp "Diagnostic response";
CM_ SG_ 1865 EVCOM_DiagResp "Diagnostic response";
CM_ SG_ 1830 IBS_DiagResp "Diagnostic response";
CM_ SG_ 2041 ACU_DiagResp "Diagnostic response";
CM_ SG_ 1859 AVAS_DiagResp "Diagnostic response";
CM_ SG_ 1833 EPS_DiagResp "Diagnostic response";
CM_ SG_ 1856 ADCU_DiagResp "Diagnostic response";
CM_ SG_ 1027 SGW_DTC_Number "Number of current failures";
CM_ SG_ 1029 ERA_DTC_Number "Number of current failures";
CM_ SG_ 1034 CBM_DTC_Number "Number of current failures";
CM_ SG_ 1026 CGW_DTC_Number "Number of current failures";
CM_ SG_ 1025 BCM1_DTC_Number "Number of current failures";
CM_ SG_ 1050 BCM2_DTC_Number "Number of current failures";
CM_ SG_ 1051 SCUL_DTC_Number "Number of current failures";
CM_ SG_ 1052 SCUR_DTC_Number "Number of current failures";
CM_ SG_ 1055 WCBS1_DTC_Number "Number of current failures";
CM_ SG_ 1056 WCBS2_DTC_Number "Number of current failures";
CM_ SG_ 1071 DCM_FL_DTC_Number "Number of current failures";
CM_ SG_ 1083 DCM_FR_DTC_Number "Number of current failures";
CM_ SG_ 1079 DCM_RL_DTC_Number "Number of current failures";
CM_ SG_ 1084 DCM_RR_DTC_Number "Number of current failures";
CM_ SG_ 1086 HLR_DTC_Number "Number of current failures";
CM_ SG_ 1053 HLL_DTC_Number "Number of current failures";
CM_ SG_ 1067 PAT_DTC_Number "Number of current failures";
CM_ SG_ 1088 ADCU_DTC_Number "Number of current failures";
CM_ SG_ 1092 IVI_DTC_Number "Number of current failures";
CM_ SG_ 1037 HUD_DTC_Number "Number of current failures";
CM_ SG_ 1049 MFP_RC_DTC_Number "Number of current failures";
CM_ SG_ 1046 MFP_FC_DTC_Number "Number of current failures";
CM_ SG_ 1031 SWP_DTC_Number "Number of current failures";
CM_ SG_ 1030 Switches_DTC_Number "Number of current failures";
CM_ SG_ 1033 HOD_heating_DTC_Number "Number of current failures";
CM_ SG_ 1038 DIM_DTC_Number "Number of current failures";
CM_ SG_ 1032 NDT_DTC_Number "Number of current failures";
CM_ SG_ 1095 POD_DTC_Number "Number of current failures";
CM_ SG_ 1043 BMS_DTC_Number "Number of current failures";
CM_ SG_ 1096 TCU_DTC_Number "Number of current failures";
CM_ SG_ 1102 AIRPTC_DTC_Number "Number of current failures";
CM_ SG_ 1068 VCU_DTC_Number "Number of current failures";
CM_ SG_ 1090 MCU_DTC_Number "Number of current failures";
CM_ SG_ 1103 PRND_DTC_Number "Number of current failures";
CM_ SG_ 1097 EVCOM_DTC_Number "Number of current failures";
CM_ SG_ 1062 IBS_DTC_Number "Number of current failures";
CM_ SG_ 1273 ACU_DTC_Number "Number of current failures";
CM_ SG_ 1091 AVAS_DTC_Number "Number of current failures";
CM_ SG_ 1065 EPS_DTC_Number "Number of current failures";
CM_ SG_ 947 MCU_FaultNum1 "Real-time fault code of number 1";
CM_ SG_ 947 MCU_FaultNum2 "Real-time fault code of number 2";
CM_ SG_ 947 MCU_FaultNum3 "Real-time fault code of number 3";
CM_ SG_ 947 MCU_FaultNum4 "Real-time fault code of number 4";
CM_ SG_ 947 MCU_FaultNum5 "Real-time fault code of number 5";
CM_ SG_ 947 MCU_FaultNum6 "Real-time fault code of number 6";
CM_ SG_ 947 MCU_FaultNum7 "Real-time fault code of number 7";
CM_ SG_ 947 MCU_FaultNum8 "Real-time fault code of number 8";
CM_ SG_ 948 MCU_FaultNum9 "Real-time fault code of number 9";
CM_ SG_ 948 MCU_FaultNum10 "Real-time fault code of number 10";
CM_ SG_ 948 MCU_TotalFaultNum "Total number of current faults";
BA_DEF_ BO_  "GenMsgSendType" ENUM  "Cyclic","Event","IfActive","CE","CA","NoMsgSendType";
BA_DEF_ BO_  "GenMsgCycleTime" INT 0 0;
BA_DEF_ BO_  "GenMsgCycleTimeFast" INT 0 0;
BA_DEF_ BO_  "CANFD_BRS" ENUM  "0","1";
BA_DEF_ BO_  "GenMsgNrOfRepetition" INT 0 0;
BA_DEF_ BO_  "GenMsgDelayTime" INT 0 0;
BA_DEF_ BO_  "GenMsgILSupport" ENUM  "No","Yes";
BA_DEF_ BO_  "NmMessage" ENUM "No","Yes";
BA_DEF_ BO_  "DiagState" ENUM  "No","Yes";
BA_DEF_ BO_  "DiagRequest" ENUM  "No","Yes";
BA_DEF_ BO_  "DiagResponse" ENUM  "No","Yes";
BA_DEF_ BO_  "VFrameFormat" ENUM  "StandardCAN","ExtendedCAN","reserved","reserved","reserved","reserved","reserved","reserved","reserved","reserved","reserved","reserved","reserved","reserved","StandardCAN_FD","ExtendedCAN_FD";
BA_DEF_ SG_  "GenSigSendType" ENUM  "Cyclic","OnChange","OnWrite","IfActive","OnChangeWithRepetition","OnWriteWithRepetition","IfActiveWithRepetition","NoSigSendType","NotUsed","NotUsed","NotUsed","NotUsed","NotUsed";
BA_DEF_ SG_  "GenSigStartValue" INT 0 0;
BA_DEF_ SG_  "GenSigInvalidValue" INT 0 0;
BA_DEF_DEF_  "GenMsgSendType" "Cyclic";
BA_DEF_DEF_  "GenMsgCycleTime" 0;
BA_DEF_DEF_  "GenSigSendType" "Cyclic";
BA_DEF_DEF_  "GenSigStartValue" 0;
BA_DEF_DEF_  "GenSigInvalidValue" 0;
BA_DEF_DEF_  "GenMsgCycleTimeFast" 0;
BA_DEF_DEF_  "GenMsgNrOfRepetition" 0;
BA_DEF_DEF_  "GenMsgDelayTime" 0;
BA_DEF_DEF_  "CANFD_BRS" "1";
BA_DEF_DEF_  "GenMsgILSupport" "Yes";
BA_DEF_DEF_  "NmMessage" "No";
BA_DEF_DEF_  "DiagState" "No";
BA_DEF_DEF_  "DiagRequest" "No";
BA_DEF_DEF_  "DiagResponse" "No";
BA_DEF_DEF_  "VFrameFormat" "StandardCAN_FD";
BA_ "GenMsgSendType" BO_ 852 1;
BA_ "GenMsgCycleTimeFast" BO_ 852 20;
BA_ "GenMsgNrOfRepetition" BO_ 852 3;
BA_ "GenMsgDelayTime" BO_ 852 20;
BA_ "GenSigSendType" SG_ 852 IVI_FLAmbientColorReq 4;
BA_ "GenSigSendType" SG_ 852 IVI_FRAmbientColorReq 4;
BA_ "GenSigSendType" SG_ 852 IVI_RLAmbientColorReq 4;
BA_ "GenSigSendType" SG_ 852 IVI_RRAmbientColorReq 4;
BA_ "GenSigSendType" SG_ 852 IVI_IPAmbientColorReq 4;
BA_ "GenSigSendType" SG_ 852 IVI_FLAmbientLightReq 4;
BA_ "GenSigSendType" SG_ 852 IVI_FRAmbientLightReq 4;
BA_ "GenSigSendType" SG_ 852 IVI_RLAmbientLightReq 4;
BA_ "GenSigSendType" SG_ 852 IVI_RRAmbientLightReq 4;
BA_ "GenSigSendType" SG_ 852 IVI_IPAmbientLightReq 4;
BA_ "GenMsgSendType" BO_ 575 3;
BA_ "GenMsgCycleTime" BO_ 575 100;
BA_ "GenMsgCycleTimeFast" BO_ 575 20;
BA_ "GenMsgNrOfRepetition" BO_ 575 3;
BA_ "GenMsgDelayTime" BO_ 575 20;
BA_ "GenSigSendType" SG_ 575 SGW_L_RearSeatHeatSet 4;
BA_ "GenSigInvalidValue" SG_ 575 SGW_L_RearSeatHeatSet 3;
BA_ "GenSigSendType" SG_ 575 SGW_R_RearSeatHeatSet 4;
BA_ "GenSigInvalidValue" SG_ 575 SGW_R_RearSeatHeatSet 3;
BA_ "GenSigSendType" SG_ 575 SGW_DrSeatWelcomeLevelSet 4;
BA_ "GenSigInvalidValue" SG_ 575 SGW_DrSeatWelcomeLevelSet 3;
BA_ "GenSigSendType" SG_ 575 SGW_PsSeatWelcomeLevelSet 4;
BA_ "GenSigInvalidValue" SG_ 575 SGW_PsSeatWelcomeLevelSet 3;
BA_ "GenSigSendType" SG_ 575 SGW_MirrorAutoTurnDownSet 4;
BA_ "GenSigInvalidValue" SG_ 575 SGW_MirrorAutoTurnDownSet 3;
BA_ "GenSigSendType" SG_ 575 SGW_WelcomeOnOffSet 4;
BA_ "GenSigInvalidValue" SG_ 575 SGW_WelcomeOnOffSet 3;
BA_ "GenSigSendType" SG_ 575 SGW_PassWelcomeOnOffSet 4;
BA_ "GenSigInvalidValue" SG_ 575 SGW_PassWelcomeOnOffSet 3;
BA_ "GenMsgSendType" BO_ 256 1;
BA_ "GenMsgCycleTimeFast" BO_ 256 20;
BA_ "GenMsgNrOfRepetition" BO_ 256 3;
BA_ "GenMsgDelayTime" BO_ 256 20;
BA_ "GenSigSendType" SG_ 256 IVI_ResetReq 4;
BA_ "GenSigSendType" SG_ 256 IVI_AutoScreenBacklight 4;
BA_ "GenSigSendType" SG_ 256 IVI_ScreenBrightnessSet 4;
BA_ "GenSigStartValue" SG_ 256 IVI_ScreenBrightnessSet 31;
BA_ "GenSigInvalidValue" SG_ 256 IVI_ScreenBrightnessSet 31;
BA_ "GenSigSendType" SG_ 256 IVI_AVASOnOffSet 4;
BA_ "GenSigSendType" SG_ 256 IVI_AVASSoundSet 4;
BA_ "GenSigSendType" SG_ 256 IVI_PassAirbagOpenSet 4;
BA_ "GenSigSendType" SG_ 256 IVI_WCBSReminderSet 4;
BA_ "GenSigSendType" SG_ 256 IVI_HazardWarmReq 4;
BA_ "GenSigSendType" SG_ 256 IVI_ThanksHazardWarmReq 4;
BA_ "GenSigSendType" SG_ 256 IVI_WelInteriorLightSet 4;
BA_ "GenSigSendType" SG_ 256 IVI_PriorSoundSet 4;
BA_ "GenSigSendType" SG_ 256 IVI_FrontKeepOpenSet 4;
BA_ "GenMsgSendType" BO_ 259 1;
BA_ "GenMsgCycleTimeFast" BO_ 259 20;
BA_ "GenMsgNrOfRepetition" BO_ 259 3;
BA_ "GenMsgDelayTime" BO_ 259 20;
BA_ "GenSigSendType" SG_ 259 IVI_L_DsSeatBackPos 4;
BA_ "GenSigStartValue" SG_ 259 IVI_L_DsSeatBackPos 254;
BA_ "GenSigSendType" SG_ 259 IVI_L_DsSeatHeightPos 4;
BA_ "GenSigStartValue" SG_ 259 IVI_L_DsSeatHeightPos 254;
BA_ "GenSigSendType" SG_ 259 IVI_L_DsSeatSlidePos 4;
BA_ "GenSigStartValue" SG_ 259 IVI_L_DsSeatSlidePos 254;
BA_ "GenSigSendType" SG_ 259 IVI_DrSeatHeatLevelSet 4;
BA_ "GenSigSendType" SG_ 259 IVI_DrSeatWelcomeLevelSet 4;
BA_ "GenMsgSendType" BO_ 260 1;
BA_ "GenMsgCycleTimeFast" BO_ 260 20;
BA_ "GenMsgNrOfRepetition" BO_ 260 3;
BA_ "GenMsgDelayTime" BO_ 260 20;
BA_ "GenSigSendType" SG_ 260 IVI_R_DsSeatSlidePos 4;
BA_ "GenSigStartValue" SG_ 260 IVI_R_DsSeatSlidePos 254;
BA_ "GenSigSendType" SG_ 260 IVI_R_DsSeatHeightPos 4;
BA_ "GenSigStartValue" SG_ 260 IVI_R_DsSeatHeightPos 254;
BA_ "GenSigSendType" SG_ 260 IVI_R_DsSeatBackPos 4;
BA_ "GenSigStartValue" SG_ 260 IVI_R_DsSeatBackPos 254;
BA_ "GenSigSendType" SG_ 260 IVI_PassSeatHeatLevelSet 4;
BA_ "GenSigSendType" SG_ 260 IVI_PsSeatWelcomeLevelSet 4;
BA_ "GenSigInvalidValue" SG_ 260 IVI_PsSeatWelcomeLevelSet 3;
BA_ "GenMsgSendType" BO_ 264 3;
BA_ "GenMsgCycleTime" BO_ 264 100;
BA_ "GenMsgCycleTimeFast" BO_ 264 20;
BA_ "GenMsgNrOfRepetition" BO_ 264 3;
BA_ "GenMsgDelayTime" BO_ 264 20;
BA_ "GenSigSendType" SG_ 264 SGW_FR_FrontRearReq 4;
BA_ "GenSigSendType" SG_ 264 SGW_FR_HeightMotorReq 4;
BA_ "GenSigSendType" SG_ 264 SGW_FR_BackrestMotorReq 4;
BA_ "GenMsgSendType" BO_ 710 1;
BA_ "GenMsgCycleTimeFast" BO_ 710 20;
BA_ "GenMsgNrOfRepetition" BO_ 710 3;
BA_ "GenMsgDelayTime" BO_ 710 20;
BA_ "GenSigSendType" SG_ 710 IVI_StWAnglePos 4;
BA_ "GenSigStartValue" SG_ 710 IVI_StWAnglePos 254;
BA_ "GenSigSendType" SG_ 710 IVI_StWLengthPos 4;
BA_ "GenSigStartValue" SG_ 710 IVI_StWLengthPos 254;
BA_ "GenMsgSendType" BO_ 563 1;
BA_ "GenMsgCycleTimeFast" BO_ 563 20;
BA_ "GenMsgNrOfRepetition" BO_ 563 3;
BA_ "GenMsgDelayTime" BO_ 563 20;
BA_ "GenSigSendType" SG_ 563 IVI_MirrorFold_UnfoldSet 4;
BA_ "GenSigSendType" SG_ 563 IVI_MirrorAutoTurnDownSet 4;
BA_ "GenSigInvalidValue" SG_ 563 IVI_MirrorAutoTurnDownSet 3;
BA_ "GenSigSendType" SG_ 563 IVI_MirrorAutoFoldUnfoldSet 4;
BA_ "GenSigInvalidValue" SG_ 563 IVI_MirrorAutoFoldUnfoldSet 3;
BA_ "GenSigSendType" SG_ 563 IVI_LeftMirrorHorizontalPos 4;
BA_ "GenSigStartValue" SG_ 563 IVI_LeftMirrorHorizontalPos 254;
BA_ "GenSigSendType" SG_ 563 IVI_LeftMirrorVerticalPos 4;
BA_ "GenSigStartValue" SG_ 563 IVI_LeftMirrorVerticalPos 254;
BA_ "GenSigSendType" SG_ 563 IVI_RightMirrorHorizontalPos 4;
BA_ "GenSigStartValue" SG_ 563 IVI_RightMirrorHorizontalPos 254;
BA_ "GenSigSendType" SG_ 563 IVI_RightMirrorVerticalPos 4;
BA_ "GenSigStartValue" SG_ 563 IVI_RightMirrorVerticalPos 254;
BA_ "GenMsgSendType" BO_ 574 1;
BA_ "GenMsgCycleTimeFast" BO_ 574 20;
BA_ "GenMsgNrOfRepetition" BO_ 574 3;
BA_ "GenMsgDelayTime" BO_ 574 20;
BA_ "GenSigSendType" SG_ 574 IVI_FLDoorLockSet 4;
BA_ "GenSigSendType" SG_ 574 IVI_FRDoorLockSet 4;
BA_ "GenSigSendType" SG_ 574 IVI_RLDoorLockSet 4;
BA_ "GenSigSendType" SG_ 574 IVI_RRDoorLockSet 4;
BA_ "GenSigSendType" SG_ 574 IVI_PassWindowLockSet 4;
BA_ "GenSigSendType" SG_ 574 IVI_ModeEnterReq 4;
BA_ "GenMsgSendType" BO_ 689 1;
BA_ "GenMsgCycleTimeFast" BO_ 689 20;
BA_ "GenMsgNrOfRepetition" BO_ 689 3;
BA_ "GenMsgDelayTime" BO_ 689 20;
BA_ "GenSigSendType" SG_ 689 IVI_HUDALTITUDESet 4;
BA_ "GenSigSendType" SG_ 689 IVI_HUDOnOffSet 4;
BA_ "GenMsgSendType" BO_ 561 1;
BA_ "GenMsgCycleTimeFast" BO_ 561 20;
BA_ "GenMsgNrOfRepetition" BO_ 561 3;
BA_ "GenMsgDelayTime" BO_ 561 20;
BA_ "GenSigSendType" SG_ 561 IVI_ESCOffSet 4;
BA_ "GenSigSendType" SG_ 561 IVI_TPMS_Reset 4;
BA_ "GenSigSendType" SG_ 561 IVI_HDCOffSet 4;
BA_ "GenSigSendType" SG_ 561 IVI_AVHSet 4;
BA_ "GenSigSendType" SG_ 561 IVI_SteeringModeSet 4;
BA_ "GenSigSendType" SG_ 561 IVI_BrakeCompensateCmd 4;
BA_ "GenSigSendType" SG_ 561 IVI_CRLevelSet 4;
BA_ "GenMsgCycleTime" BO_ 790 200;
BA_ "GenMsgCycleTime" BO_ 945 1000;
BA_ "GenMsgCycleTime" BO_ 946 1000;
BA_ "GenMsgSendType" BO_ 693 1;
BA_ "GenMsgCycleTimeFast" BO_ 693 20;
BA_ "GenMsgNrOfRepetition" BO_ 693 3;
BA_ "GenMsgDelayTime" BO_ 693 20;
BA_ "GenSigSendType" SG_ 693 IVI_AppointChargeCmd 4;
BA_ "GenSigSendType" SG_ 693 IVI_ForwardVmaxlimitSw 4;
BA_ "GenSigSendType" SG_ 693 IVI_KeepWarmRequest 4;
BA_ "GenSigSendType" SG_ 693 IVI_LockACPlug 4;
BA_ "GenSigSendType" SG_ 693 IVI_LV_LimitPop 4;
BA_ "GenMsgSendType" BO_ 694 1;
BA_ "GenMsgCycleTimeFast" BO_ 694 20;
BA_ "GenMsgNrOfRepetition" BO_ 694 3;
BA_ "GenMsgDelayTime" BO_ 694 20;
BA_ "GenSigSendType" SG_ 694 IVI_GearRequest 4;
BA_ "GenSigInvalidValue" SG_ 694 IVI_GearRequest 5;
BA_ "GenMsgSendType" BO_ 261 1;
BA_ "GenMsgCycleTimeFast" BO_ 261 20;
BA_ "GenMsgNrOfRepetition" BO_ 261 3;
BA_ "GenMsgDelayTime" BO_ 261 20;
BA_ "GenSigSendType" SG_ 261 SGW_RemoteAirCondAUTOReq 4;
BA_ "GenSigSendType" SG_ 261 SGW_RemoteAirCondOnOFFReq 4;
BA_ "GenSigInvalidValue" SG_ 261 SGW_RemoteAirCondOnOFFReq 3;
BA_ "GenSigSendType" SG_ 261 SGW_RearDoorAngleSet 4;
BA_ "GenSigSendType" SG_ 261 SGW_FrontDoorAngleSet 4;
BA_ "GenSigSendType" SG_ 261 SGW_RemoteFrontDefrostReq 4;
BA_ "GenSigInvalidValue" SG_ 261 SGW_RemoteFrontDefrostReq 3;
BA_ "GenSigSendType" SG_ 261 SGW_RemoteSteerHeatReq 4;
BA_ "GenSigInvalidValue" SG_ 261 SGW_RemoteSteerHeatReq 3;
BA_ "GenSigSendType" SG_ 261 SGW_RemoteDrSeatHeatReq 4;
BA_ "GenSigSendType" SG_ 261 SGW_LeftChdLockCtrlReq 4;
BA_ "GenSigSendType" SG_ 261 SGW_RearDefrostCtrlSet 4;
BA_ "GenSigSendType" SG_ 261 SGW_RemoteFrontWindHeatReq 4;
BA_ "GenSigInvalidValue" SG_ 261 SGW_RemoteFrontWindHeatReq 3;
BA_ "GenSigSendType" SG_ 261 SGW_RemoteRearMirHeatReq 4;
BA_ "GenSigInvalidValue" SG_ 261 SGW_RemoteRearMirHeatReq 3;
BA_ "GenSigSendType" SG_ 261 SGW_RemotePassSeatHeatReq 4;
BA_ "GenSigSendType" SG_ 261 SGW_oneTouchCoolSet 4;
BA_ "GenSigSendType" SG_ 261 SGW_RemoteRearWindHeatReq 4;
BA_ "GenSigInvalidValue" SG_ 261 SGW_RemoteRearWindHeatReq 3;
BA_ "GenSigSendType" SG_ 261 SGW_TakePicCtrl 4;
BA_ "GenSigSendType" SG_ 261 SGW_RemoteACOnOffReq 4;
BA_ "GenSigSendType" SG_ 261 SGW_RightChdLockCtrlReq 4;
BA_ "GenSigSendType" SG_ 261 SGW_RemoteTailgateLockCtrlReq 4;
BA_ "GenSigSendType" SG_ 261 SGW_HDCOffSet 4;
BA_ "GenSigSendType" SG_ 261 SGW_AVHSet 4;
BA_ "GenSigSendType" SG_ 261 SGW_SteeringModeSet 4;
BA_ "GenSigSendType" SG_ 261 SGW_AVASSoundSet 4;
BA_ "GenSigSendType" SG_ 261 SGW_DriveModeSet 4;
BA_ "GenSigSendType" SG_ 261 SGW_ImuCarParkBeStolen 4;
BA_ "GenMsgSendType" BO_ 262 1;
BA_ "GenMsgCycleTimeFast" BO_ 262 20;
BA_ "GenMsgNrOfRepetition" BO_ 262 3;
BA_ "GenMsgDelayTime" BO_ 262 20;
BA_ "GenSigSendType" SG_ 262 IVI_HUDScreenBrightnessSet 4;
BA_ "GenSigStartValue" SG_ 262 IVI_HUDScreenBrightnessSet 31;
BA_ "GenSigInvalidValue" SG_ 262 IVI_HUDScreenBrightnessSet 31;
BA_ "GenMsgSendType" BO_ 263 1;
BA_ "GenMsgCycleTimeFast" BO_ 263 20;
BA_ "GenMsgNrOfRepetition" BO_ 263 3;
BA_ "GenMsgDelayTime" BO_ 263 20;
BA_ "GenSigSendType" SG_ 263 SGW_AutoCloseWinFunSet 4;
BA_ "GenSigSendType" SG_ 263 SGW_RemoteDrvSetTempSteplsReq 4;
BA_ "GenSigSendType" SG_ 263 SGW_FrontWiperAutoSet 4;
BA_ "GenSigSendType" SG_ 263 SGW_RemotePassSetTempSteplsReq 4;
BA_ "GenSigSendType" SG_ 263 SGW_AllDoorReq 4;
BA_ "GenSigSendType" SG_ 263 SGW_RemoteCarSearchReq 4;
BA_ "GenSigSendType" SG_ 263 SGW_RemoteLockCtrlReq 4;
BA_ "GenSigSendType" SG_ 263 SGW_RRDoorReq 4;
BA_ "GenSigSendType" SG_ 263 SGW_RLDoorReq 4;
BA_ "GenSigSendType" SG_ 263 SGW_FRDoorReq 4;
BA_ "GenSigSendType" SG_ 263 SGW_FLDoorReq 4;
BA_ "GenSigSendType" SG_ 263 SGW_WelInteriorLightSet 4;
BA_ "GenSigSendType" SG_ 263 SGW_CarSharingLightSet 4;
BA_ "GenSigSendType" SG_ 263 SGW_CarSharingColorSet 4;
BA_ "GenSigSendType" SG_ 263 SGW_CarSharingTimeSet 4;
BA_ "GenSigSendType" SG_ 263 SGW_FRDomeLampSet 4;
BA_ "GenSigSendType" SG_ 263 SGW_RRDomeLampSet 4;
BA_ "GenMsgSendType" BO_ 316 1;
BA_ "GenMsgCycleTimeFast" BO_ 316 20;
BA_ "GenMsgNrOfRepetition" BO_ 316 3;
BA_ "GenMsgDelayTime" BO_ 316 20;
BA_ "GenSigSendType" SG_ 316 SGW_L_MirrorMainHorizontalPos 4;
BA_ "GenSigStartValue" SG_ 316 SGW_L_MirrorMainHorizontalPos 254;
BA_ "GenSigSendType" SG_ 316 SGW_L_MirrorMainVerticalPos 4;
BA_ "GenSigStartValue" SG_ 316 SGW_L_MirrorMainVerticalPos 254;
BA_ "GenSigSendType" SG_ 316 SGW_R_MirrorMainHorizontalPos 4;
BA_ "GenSigStartValue" SG_ 316 SGW_R_MirrorMainHorizontalPos 254;
BA_ "GenSigSendType" SG_ 316 SGW_R_MirrorMainVerticalPos 4;
BA_ "GenSigStartValue" SG_ 316 SGW_R_MirrorMainVerticalPos 254;
BA_ "GenSigSendType" SG_ 316 SGW_L_MirrorTiltHorizontalPos 4;
BA_ "GenSigStartValue" SG_ 316 SGW_L_MirrorTiltHorizontalPos 254;
BA_ "GenSigSendType" SG_ 316 SGW_L_MirrorTiltVerticalPos 4;
BA_ "GenSigStartValue" SG_ 316 SGW_L_MirrorTiltVerticalPos 254;
BA_ "GenSigSendType" SG_ 316 SGW_R_MirrorTiltHorizontalPos 4;
BA_ "GenSigStartValue" SG_ 316 SGW_R_MirrorTiltHorizontalPos 254;
BA_ "GenSigSendType" SG_ 316 SGW_R_MirrorTiltVerticalPos 4;
BA_ "GenSigStartValue" SG_ 316 SGW_R_MirrorTiltVerticalPos 254;
BA_ "GenMsgSendType" BO_ 315 1;
BA_ "GenMsgCycleTimeFast" BO_ 315 20;
BA_ "GenMsgNrOfRepetition" BO_ 315 3;
BA_ "GenMsgDelayTime" BO_ 315 20;
BA_ "GenSigSendType" SG_ 315 SGW_DrSeatSlidePos 4;
BA_ "GenSigStartValue" SG_ 315 SGW_DrSeatSlidePos 254;
BA_ "GenSigSendType" SG_ 315 SGW_DrSeatHeightPos 4;
BA_ "GenSigStartValue" SG_ 315 SGW_DrSeatHeightPos 254;
BA_ "GenSigSendType" SG_ 315 SGW_DrSeatBackPos 4;
BA_ "GenSigStartValue" SG_ 315 SGW_DrSeatBackPos 254;
BA_ "GenSigSendType" SG_ 315 SGW_StWLengthPos 4;
BA_ "GenSigStartValue" SG_ 315 SGW_StWLengthPos 254;
BA_ "GenSigSendType" SG_ 315 SGW_StWAnglePos 4;
BA_ "GenSigStartValue" SG_ 315 SGW_StWAnglePos 254;
BA_ "GenSigSendType" SG_ 315 SGW_MirrorAutoFoldUnfoldSet 4;
BA_ "GenSigSendType" SG_ 315 SGW_WCBSReminderSet 4;
BA_ "GenSigSendType" SG_ 315 SGW_AutoLmpSet 4;
BA_ "GenSigSendType" SG_ 315 SGW_DippedBeamSet 4;
BA_ "GenSigSendType" SG_ 315 SGW_HUDHeightSet 4;
BA_ "GenSigStartValue" SG_ 315 SGW_HUDHeightSet 8;
BA_ "GenSigSendType" SG_ 315 SGW_HUDBrightnessSet 4;
BA_ "GenSigStartValue" SG_ 315 SGW_HUDBrightnessSet 95;
BA_ "GenSigInvalidValue" SG_ 315 SGW_HUDBrightnessSet 31;
BA_ "GenMsgSendType" BO_ 314 1;
BA_ "GenMsgCycleTimeFast" BO_ 314 20;
BA_ "GenMsgNrOfRepetition" BO_ 314 3;
BA_ "GenMsgDelayTime" BO_ 314 20;
BA_ "GenSigSendType" SG_ 314 SGW_RemoteFLWinPosiCtlCmd 4;
BA_ "GenSigSendType" SG_ 314 SGW_RemoteFRWinPosiCtlCmd 4;
BA_ "GenSigSendType" SG_ 314 SGW_RemoteRLWinPosiCtlCmd 4;
BA_ "GenSigSendType" SG_ 314 SGW_RemoteRRWinPosiCtlCmd 4;
BA_ "GenSigSendType" SG_ 314 SGW_PassWindowLockSet 4;
BA_ "GenSigSendType" SG_ 314 SGW_LeftKeyReHornMode 4;
BA_ "GenSigSendType" SG_ 314 SGW_LockDoorOpenReHornMode 4;
BA_ "GenSigSendType" SG_ 314 SGW_AntiTheftReHornMode 4;
BA_ "GenSigSendType" SG_ 314 SGW_PosnLmpSet 4;
BA_ "GenSigSendType" SG_ 314 SGW_AutoLampSenReq 4;
BA_ "GenSigSendType" SG_ 314 SGW_CornerLampSet 4;
BA_ "GenSigSendType" SG_ 314 SGW_BacklightAutoSet 4;
BA_ "GenSigSendType" SG_ 314 SGW_BacklightadjustSet 4;
BA_ "GenMsgSendType" BO_ 562 1;
BA_ "GenMsgCycleTimeFast" BO_ 562 20;
BA_ "GenMsgNrOfRepetition" BO_ 562 3;
BA_ "GenMsgDelayTime" BO_ 562 20;
BA_ "GenSigSendType" SG_ 562 SGW_DrvSetTempSteplsReq 4;
BA_ "GenSigSendType" SG_ 562 SGW_DemistReq 4;
BA_ "GenSigSendType" SG_ 562 SGW_HVACBatterySaveModeSetReq 4;
BA_ "GenSigSendType" SG_ 562 SGW_PassSetTempSteplsReq 4;
BA_ "GenSigSendType" SG_ 562 SGW_AirCondAUTOReq 4;
BA_ "GenSigSendType" SG_ 562 SGW_DualReq 4;
BA_ "GenSigSendType" SG_ 562 SGW_AirDistributionModeReq 4;
BA_ "GenSigSendType" SG_ 562 SGW_FrontDefrostReq 4;
BA_ "GenSigSendType" SG_ 562 SGW_AqsReq 4;
BA_ "GenSigSendType" SG_ 562 SGW_ClimateSystemStsReq 4;
BA_ "GenSigSendType" SG_ 562 SGW_ACCmprStsReq 4;
BA_ "GenSigSendType" SG_ 562 SGW_AirCirclnReq 4;
BA_ "GenSigSendType" SG_ 562 SGW_BlowersteplsSpdReq 4;
BA_ "GenSigSendType" SG_ 562 SGW_PresetModeEnable 4;
BA_ "GenSigSendType" SG_ 562 SGW_PresetModeReq 4;
BA_ "GenSigSendType" SG_ 562 SGW_VentilationModeReq 4;
BA_ "GenSigSendType" SG_ 562 SGW_AirCondEcoSet 4;
BA_ "GenMsgSendType" BO_ 560 1;
BA_ "GenMsgCycleTimeFast" BO_ 560 20;
BA_ "GenMsgNrOfRepetition" BO_ 560 3;
BA_ "GenMsgDelayTime" BO_ 560 20;
BA_ "GenSigSendType" SG_ 560 IVI_DschrgOnOffSet 4;
BA_ "GenSigSendType" SG_ 560 IVI_DriveModeSet 4;
BA_ "GenSigSendType" SG_ 560 IVI_ForwardVmaxAllowed 4;
BA_ "GenSigStartValue" SG_ 560 IVI_ForwardVmaxAllowed 36001;
BA_ "GenSigSendType" SG_ 560 IVI_MaxChrgSocSet 4;
BA_ "GenSigStartValue" SG_ 560 IVI_MaxChrgSocSet 254;
BA_ "GenSigInvalidValue" SG_ 560 IVI_MaxChrgSocSet 255;
BA_ "GenSigSendType" SG_ 560 IVI_V2LidisSet 4;
BA_ "GenSigStartValue" SG_ 560 IVI_V2LidisSet 254;
BA_ "GenSigInvalidValue" SG_ 560 IVI_V2LidisSet 255;
BA_ "GenMsgCycleTime" BO_ 564 100;
BA_ "GenSigStartValue" SG_ 564 SGW_TimeInfoDay 1;
BA_ "GenSigStartValue" SG_ 564 SGW_TimeInfoMonth 1;
BA_ "GenSigStartValue" SG_ 564 SGW_TimeValid 1;
BA_ "GenMsgCycleTime" BO_ 659 100;
BA_ "GenSigInvalidValue" SG_ 659 MessageCounter_293 15;
BA_ "GenMsgCycleTime" BO_ 657 100;
BA_ "GenSigInvalidValue" SG_ 657 MessageCounter_291 15;
BA_ "GenMsgSendType" BO_ 271 1;
BA_ "GenMsgCycleTimeFast" BO_ 271 20;
BA_ "GenMsgNrOfRepetition" BO_ 271 3;
BA_ "GenMsgDelayTime" BO_ 271 20;
BA_ "GenSigSendType" SG_ 271 Switches_L_SWipe_Cmd 4;
BA_ "GenMsgCycleTime" BO_ 608 100;
BA_ "GenMsgCycleTime" BO_ 609 100;
BA_ "GenSigInvalidValue" SG_ 609 TCU_HVCHHighVoltage 509;
BA_ "GenSigInvalidValue" SG_ 609 TCU_HVCHHVDCCurrent 255;
BA_ "GenMsgCycleTime" BO_ 610 100;
BA_ "GenSigStartValue" SG_ 610 TCU_CabinTemperature 70;
BA_ "GenMsgCycleTime" BO_ 768 200;
BA_ "GenSigInvalidValue" SG_ 768 TCU_CoolantLowWarnReq 3;
BA_ "GenSigInvalidValue" SG_ 768 TCU_FreonLowWarnReq 3;
BA_ "GenMsgCycleTime" BO_ 793 200;
BA_ "GenSigStartValue" SG_ 793 VCU_BS_IBSBatSOC 80;
BA_ "GenSigInvalidValue" SG_ 793 VCU_BS_IBSBatSOC 255;
BA_ "GenSigInvalidValue" SG_ 793 VCU_BS_Resistance 255;
BA_ "GenMsgCycleTime" BO_ 546 100;
BA_ "GenMsgCycleTime" BO_ 547 100;
BA_ "GenMsgCycleTime" BO_ 549 100;
BA_ "GenMsgCycleTime" BO_ 210 20;
BA_ "GenSigInvalidValue" SG_ 210 MessageCounter_0D2 15;
BA_ "GenMsgCycleTime" BO_ 209 20;
BA_ "GenSigInvalidValue" SG_ 209 MessageCounter_0D1 15;
BA_ "GenSigStartValue" SG_ 209 VCU_IsoMeasurementSwitch 1;
BA_ "GenSigInvalidValue" SG_ 209 VCU_RequestedModeBMS 7;
BA_ "GenMsgCycleTime" BO_ 211 20;
BA_ "GenSigInvalidValue" SG_ 211 MessageCounter_0D3 15;
BA_ "GenMsgCycleTime" BO_ 544 100;
BA_ "GenMsgCycleTime" BO_ 791 200;
BA_ "GenSigInvalidValue" SG_ 791 MessageCounter_317 15;
BA_ "GenMsgCycleTime" BO_ 792 200;
BA_ "GenSigInvalidValue" SG_ 792 MessageCounter_318 15;
BA_ "GenSigStartValue" SG_ 792 VCU_maxChargeSOC 255;
BA_ "GenSigInvalidValue" SG_ 792 VCU_maxChargeSOC 255;
BA_ "GenSigStartValue" SG_ 792 VCU_DischargeEndSoc 50;
BA_ "GenMsgCycleTime" BO_ 795 200;
BA_ "GenMsgCycleTime" BO_ 148 10;
BA_ "GenSigInvalidValue" SG_ 148 MessageCounter_094 15;
BA_ "GenMsgCycleTime" BO_ 150 10;
BA_ "GenSigStartValue" SG_ 150 VCU_MotorSpdReq 32767;
BA_ "GenSigInvalidValue" SG_ 150 VCU_MotorSpdReq 65535;
BA_ "GenSigStartValue" SG_ 150 VCU_MaxSpdLimit 32767;
BA_ "GenSigInvalidValue" SG_ 150 VCU_MaxSpdLimit 65535;
BA_ "GenMsgCycleTime" BO_ 149 10;
BA_ "GenSigInvalidValue" SG_ 149 MessageCounter_095 15;
BA_ "GenSigInvalidValue" SG_ 149 VCU_BrakepedalStatus 2;
BA_ "GenMsgCycleTime" BO_ 214 20;
BA_ "GenMsgCycleTime" BO_ 913 200;
BA_ "GenMsgCycleTime" BO_ 289 50;
BA_ "GenSigStartValue" SG_ 289 VCU_Enable_DC_Relay 1;
BA_ "GenSigStartValue" SG_ 289 VCU_OBC_Control_of_S2_SW 1;
BA_ "GenSigStartValue" SG_ 289 VCU_OBC_Control_of_em_lock 1;
BA_ "GenMsgCycleTime" BO_ 545 100;
BA_ "GenMsgCycleTime" BO_ 663 100;
BA_ "GenMsgCycleTime" BO_ 664 100;
BA_ "GenMsgSendType" BO_ 317 1;
BA_ "GenMsgCycleTimeFast" BO_ 317 50;
BA_ "GenMsgNrOfRepetition" BO_ 317 3;
BA_ "GenMsgDelayTime" BO_ 317 50;
BA_ "GenSigSendType" SG_ 317 BCM_SynRequest 5;
BA_ "GenSigStartValue" SG_ 317 BCM_SynRequest 16777215;
BA_ "GenMsgSendType" BO_ 319 1;
BA_ "GenMsgCycleTimeFast" BO_ 319 50;
BA_ "GenMsgNrOfRepetition" BO_ 319 3;
BA_ "GenMsgDelayTime" BO_ 319 50;
BA_ "GenSigSendType" SG_ 319 VCU_SynRequest 5;
BA_ "GenSigStartValue" SG_ 319 VCU_SynRequest 16777215;
BA_ "GenMsgCycleTime" BO_ 896 500;
BA_ "GenMsgCycleTime" BO_ 897 500;
BA_ "GenMsgCycleTime" BO_ 898 500;
BA_ "GenMsgCycleTime" BO_ 858 200;
BA_ "GenMsgCycleTime" BO_ 857 200;
BA_ "GenMsgSendType" BO_ 1283 1;
BA_ "CANFD_BRS" BO_ 1283 0;
BA_ "VFrameFormat" BO_ 1283 0;
BA_ "NmMessage" BO_ 1283 1;
BA_ "GenSigSendType" SG_ 1283 SGW_RMR 2;
BA_ "GenSigSendType" SG_ 1283 SGW_AWB 2;
BA_ "GenSigSendType" SG_ 1283 SGW_PNI 2;
BA_ "GenSigSendType" SG_ 1283 SGW_PNC0 2;
BA_ "GenSigSendType" SG_ 1283 SGW_PNC1 2;
BA_ "GenSigSendType" SG_ 1283 SGW_PNC2 2;
BA_ "GenSigSendType" SG_ 1283 SGW_PNC3 2;
BA_ "GenSigSendType" SG_ 1283 SGW_PNC4 2;
BA_ "GenSigSendType" SG_ 1283 SGW_PNC5 2;
BA_ "GenSigSendType" SG_ 1283 SGW_PNC6 2;
BA_ "GenSigSendType" SG_ 1283 SGW_PNC7 2;
BA_ "GenSigSendType" SG_ 1283 SGW_PNC8 2;
BA_ "GenSigSendType" SG_ 1283 SGW_PNC9 2;
BA_ "GenSigSendType" SG_ 1283 SGW_PNC10 2;
BA_ "GenSigSendType" SG_ 1283 SGW_PNC11 2;
BA_ "GenSigSendType" SG_ 1283 SGW_PNC12 2;
BA_ "GenSigSendType" SG_ 1283 SGW_PNC13 2;
BA_ "GenSigSendType" SG_ 1283 SGW_PNC14 2;
BA_ "GenSigSendType" SG_ 1283 SGW_PNC15 2;
BA_ "GenSigSendType" SG_ 1283 SGW_PNC16 2;
BA_ "GenSigSendType" SG_ 1283 SGW_PNC17 2;
BA_ "GenSigSendType" SG_ 1283 SGW_PNC18 2;
BA_ "GenSigSendType" SG_ 1283 SGW_PNC19 2;
BA_ "GenSigSendType" SG_ 1283 SGW_PNC20 2;
BA_ "GenSigSendType" SG_ 1283 SGW_PNC21 2;
BA_ "GenSigSendType" SG_ 1283 SGW_PNC22 2;
BA_ "GenSigSendType" SG_ 1283 SGW_PNC23 2;
BA_ "GenSigSendType" SG_ 1283 SGW_PNC24 2;
BA_ "GenSigSendType" SG_ 1283 SGW_PNC25 2;
BA_ "GenSigSendType" SG_ 1283 SGW_PNC26 2;
BA_ "GenSigSendType" SG_ 1283 SGW_PNC27 2;
BA_ "GenSigSendType" SG_ 1283 SGW_PNC28 2;
BA_ "GenSigSendType" SG_ 1283 SGW_PNC29 2;
BA_ "GenSigSendType" SG_ 1283 SGW_PNC30 2;
BA_ "GenSigSendType" SG_ 1283 SGW_PNC31 2;
BA_ "GenSigSendType" SG_ 1283 SGW_PNC32 2;
BA_ "GenSigSendType" SG_ 1283 SGW_PNC33 2;
BA_ "GenSigSendType" SG_ 1283 SGW_PNC34 2;
BA_ "GenSigSendType" SG_ 1283 SGW_PNC35 2;
BA_ "GenSigSendType" SG_ 1283 SGW_PNC36 2;
BA_ "GenSigSendType" SG_ 1283 SGW_PNC37 2;
BA_ "GenSigSendType" SG_ 1283 SGW_PNC38 2;
BA_ "GenSigSendType" SG_ 1283 SGW_PNC39 2;
BA_ "GenMsgSendType" BO_ 1282 1;
BA_ "CANFD_BRS" BO_ 1282 0;
BA_ "VFrameFormat" BO_ 1282 0;
BA_ "NmMessage" BO_ 1282 1;
BA_ "GenSigSendType" SG_ 1282 CGW_RMR 2;
BA_ "GenSigSendType" SG_ 1282 CGW_AWB 2;
BA_ "GenSigSendType" SG_ 1282 CGW_PNI 2;
BA_ "GenSigSendType" SG_ 1282 CGW_PNC0 2;
BA_ "GenSigSendType" SG_ 1282 CGW_PNC1 2;
BA_ "GenSigSendType" SG_ 1282 CGW_PNC2 2;
BA_ "GenSigSendType" SG_ 1282 CGW_PNC3 2;
BA_ "GenSigSendType" SG_ 1282 CGW_PNC4 2;
BA_ "GenSigSendType" SG_ 1282 CGW_PNC5 2;
BA_ "GenSigSendType" SG_ 1282 CGW_PNC6 2;
BA_ "GenSigSendType" SG_ 1282 CGW_PNC7 2;
BA_ "GenSigSendType" SG_ 1282 CGW_PNC8 2;
BA_ "GenSigSendType" SG_ 1282 CGW_PNC9 2;
BA_ "GenSigSendType" SG_ 1282 CGW_PNC10 2;
BA_ "GenSigSendType" SG_ 1282 CGW_PNC11 2;
BA_ "GenSigSendType" SG_ 1282 CGW_PNC12 2;
BA_ "GenSigSendType" SG_ 1282 CGW_PNC13 2;
BA_ "GenSigSendType" SG_ 1282 CGW_PNC14 2;
BA_ "GenSigSendType" SG_ 1282 CGW_PNC15 2;
BA_ "GenSigSendType" SG_ 1282 CGW_PNC16 2;
BA_ "GenSigSendType" SG_ 1282 CGW_PNC17 2;
BA_ "GenSigSendType" SG_ 1282 CGW_PNC18 2;
BA_ "GenSigSendType" SG_ 1282 CGW_PNC19 2;
BA_ "GenSigSendType" SG_ 1282 CGW_PNC20 2;
BA_ "GenSigSendType" SG_ 1282 CGW_PNC21 2;
BA_ "GenSigSendType" SG_ 1282 CGW_PNC22 2;
BA_ "GenSigSendType" SG_ 1282 CGW_PNC23 2;
BA_ "GenSigSendType" SG_ 1282 CGW_PNC24 2;
BA_ "GenSigSendType" SG_ 1282 CGW_PNC25 2;
BA_ "GenSigSendType" SG_ 1282 CGW_PNC26 2;
BA_ "GenSigSendType" SG_ 1282 CGW_PNC27 2;
BA_ "GenSigSendType" SG_ 1282 CGW_PNC28 2;
BA_ "GenSigSendType" SG_ 1282 CGW_PNC29 2;
BA_ "GenSigSendType" SG_ 1282 CGW_PNC30 2;
BA_ "GenSigSendType" SG_ 1282 CGW_PNC31 2;
BA_ "GenSigSendType" SG_ 1282 CGW_PNC32 2;
BA_ "GenSigSendType" SG_ 1282 CGW_PNC33 2;
BA_ "GenSigSendType" SG_ 1282 CGW_PNC34 2;
BA_ "GenSigSendType" SG_ 1282 CGW_PNC35 2;
BA_ "GenSigSendType" SG_ 1282 CGW_PNC36 2;
BA_ "GenSigSendType" SG_ 1282 CGW_PNC37 2;
BA_ "GenSigSendType" SG_ 1282 CGW_PNC38 2;
BA_ "GenSigSendType" SG_ 1282 CGW_PNC39 2;
BA_ "GenMsgSendType" BO_ 2047 1;
BA_ "GenSigSendType" SG_ 2047 ALL_DiagReq 2;
BA_ "DiagRequest" BO_ 2047 1;
BA_ "GenMsgSendType" BO_ 2015 1;
BA_ "GenSigSendType" SG_ 2015 FUN_DiagReq 2;
BA_ "DiagState" BO_ 2015 1;
BA_ "GenMsgSendType" BO_ 1843 1;
BA_ "GenSigSendType" SG_ 1843 OBD_DiagReq 2;
BA_ "DiagRequest" BO_ 1843 1;
BA_ "GenMsgSendType" BO_ 2016 1;
BA_ "GenSigSendType" SG_ 2016 VCU_OBD_DiagReq 2;
BA_ "DiagRequest" BO_ 2016 1;
BA_ "GenMsgSendType" BO_ 2024 1;
BA_ "GenSigSendType" SG_ 2024 VCU_OBD_DiagResp 2;
BA_ "DiagResponse" BO_ 2024 1;
BA_ "GenMsgSendType" BO_ 2025 1;
BA_ "GenSigSendType" SG_ 2025 BD_DiagReq 2;
BA_ "DiagRequest" BO_ 2025 1;
BA_ "GenMsgSendType" BO_ 2029 1;
BA_ "GenSigSendType" SG_ 2029 ET_DiagReq 2;
BA_ "DiagRequest" BO_ 2029 1;
BA_ "GenMsgSendType" BO_ 2026 1;
BA_ "GenSigSendType" SG_ 2026 PT_DiagReq 2;
BA_ "DiagRequest" BO_ 2026 1;
BA_ "GenMsgSendType" BO_ 2027 1;
BA_ "GenSigSendType" SG_ 2027 CH_DiagReq 2;
BA_ "DiagRequest" BO_ 2027 1;
BA_ "GenMsgSendType" BO_ 1922 1;
BA_ "GenSigSendType" SG_ 1922 CGW_DiagReq 2;
BA_ "DiagRequest" BO_ 1922 1;
BA_ "GenMsgSendType" BO_ 1921 1;
BA_ "GenSigSendType" SG_ 1921 BCM1_DiagReq 2;
BA_ "DiagRequest" BO_ 1921 1;
BA_ "GenMsgSendType" BO_ 1946 1;
BA_ "GenSigSendType" SG_ 1946 BCM2_DiagReq 2;
BA_ "DiagRequest" BO_ 1946 1;
BA_ "GenMsgSendType" BO_ 1947 1;
BA_ "GenSigSendType" SG_ 1947 SCUL_DiagReq 2;
BA_ "DiagRequest" BO_ 1947 1;
BA_ "GenMsgSendType" BO_ 1948 1;
BA_ "GenSigSendType" SG_ 1948 SCUR_DiagReq 2;
BA_ "DiagRequest" BO_ 1948 1;
BA_ "GenMsgSendType" BO_ 1951 1;
BA_ "GenSigSendType" SG_ 1951 WCBS1_DiagReq 2;
BA_ "DiagRequest" BO_ 1951 1;
BA_ "GenMsgSendType" BO_ 1952 1;
BA_ "GenSigSendType" SG_ 1952 WCBS2_DiagReq 2;
BA_ "DiagRequest" BO_ 1952 1;
BA_ "GenMsgSendType" BO_ 1967 1;
BA_ "GenSigSendType" SG_ 1967 DCM_FL_DiagReq 2;
BA_ "DiagRequest" BO_ 1967 1;
BA_ "GenMsgSendType" BO_ 1975 1;
BA_ "GenSigSendType" SG_ 1975 DCM_FR_DiagReq 2;
BA_ "DiagRequest" BO_ 1975 1;
BA_ "GenMsgSendType" BO_ 1979 1;
BA_ "GenSigSendType" SG_ 1979 DCM_RL_DiagReq 2;
BA_ "DiagRequest" BO_ 1979 1;
BA_ "GenMsgSendType" BO_ 1980 1;
BA_ "GenSigSendType" SG_ 1980 DCM_RR_DiagReq 2;
BA_ "DiagRequest" BO_ 1980 1;
BA_ "GenMsgSendType" BO_ 1950 1;
BA_ "GenSigSendType" SG_ 1950 HLR_DiagReq 2;
BA_ "DiagRequest" BO_ 1950 1;
BA_ "GenMsgSendType" BO_ 1949 1;
BA_ "GenSigSendType" SG_ 1949 HLL_DiagReq 2;
BA_ "DiagRequest" BO_ 1949 1;
BA_ "GenMsgSendType" BO_ 1963 1;
BA_ "GenSigSendType" SG_ 1963 PAT_DiagReq 2;
BA_ "DiagRequest" BO_ 1963 1;
BA_ "GenMsgSendType" BO_ 1924 1;
BA_ "GenSigSendType" SG_ 1924 IVI_DiagReq 2;
BA_ "DiagRequest" BO_ 1924 1;
BA_ "GenMsgSendType" BO_ 1933 1;
BA_ "GenSigSendType" SG_ 1933 HUD_DiagReq 2;
BA_ "DiagRequest" BO_ 1933 1;
BA_ "GenMsgSendType" BO_ 1945 1;
BA_ "GenSigSendType" SG_ 1945 MFP_RC_DiagReq 2;
BA_ "DiagRequest" BO_ 1945 1;
BA_ "GenMsgSendType" BO_ 1942 1;
BA_ "GenSigSendType" SG_ 1942 MFP_FC_DiagReq 2;
BA_ "DiagRequest" BO_ 1942 1;
BA_ "GenMsgSendType" BO_ 1927 1;
BA_ "GenSigSendType" SG_ 1927 SWP_DiagReq 2;
BA_ "DiagRequest" BO_ 1927 1;
BA_ "GenMsgSendType" BO_ 1926 1;
BA_ "GenSigSendType" SG_ 1926 Switches_DiagReq 2;
BA_ "DiagRequest" BO_ 1926 1;
BA_ "GenMsgSendType" BO_ 1940 1;
BA_ "GenSigSendType" SG_ 1940 Switches2_DiagReq 2;
BA_ "DiagRequest" BO_ 1940 1;
BA_ "GenMsgSendType" BO_ 1929 1;
BA_ "GenSigSendType" SG_ 1929 HOD_heating_DiagReq 2;
BA_ "DiagRequest" BO_ 1929 1;
BA_ "GenMsgSendType" BO_ 1934 1;
BA_ "GenSigSendType" SG_ 1934 DIM_DiagReq 2;
BA_ "DiagRequest" BO_ 1934 1;
BA_ "GenMsgSendType" BO_ 1928 1;
BA_ "GenSigSendType" SG_ 1928 NDT_DiagReq 2;
BA_ "DiagRequest" BO_ 1928 1;
BA_ "GenMsgSendType" BO_ 1991 1;
BA_ "GenSigSendType" SG_ 1991 POD_DiagReq 2;
BA_ "DiagRequest" BO_ 1991 1;
BA_ "GenMsgSendType" BO_ 1939 1;
BA_ "GenSigSendType" SG_ 1939 BMS_DiagReq 2;
BA_ "DiagRequest" BO_ 1939 1;
BA_ "GenMsgSendType" BO_ 1992 1;
BA_ "GenSigSendType" SG_ 1992 TCU_DiagReq 2;
BA_ "DiagRequest" BO_ 1992 1;
BA_ "GenMsgSendType" BO_ 1998 1;
BA_ "GenSigSendType" SG_ 1998 AIRPTC_DiagReq 2;
BA_ "DiagRequest" BO_ 1998 1;
BA_ "GenMsgSendType" BO_ 1964 1;
BA_ "GenSigSendType" SG_ 1964 VCU_DiagReq 2;
BA_ "DiagRequest" BO_ 1964 1;
BA_ "GenMsgSendType" BO_ 1986 1;
BA_ "GenSigSendType" SG_ 1986 MCU_DiagReq 2;
BA_ "DiagRequest" BO_ 1986 1;
BA_ "GenMsgSendType" BO_ 1999 1;
BA_ "GenSigSendType" SG_ 1999 PRND_DiagReq 2;
BA_ "DiagRequest" BO_ 1999 1;
BA_ "GenMsgSendType" BO_ 1993 1;
BA_ "GenSigSendType" SG_ 1993 EVCOM_DiagReq 2;
BA_ "DiagRequest" BO_ 1993 1;
BA_ "GenMsgSendType" BO_ 1958 1;
BA_ "GenSigSendType" SG_ 1958 IBS_DiagReq 2;
BA_ "DiagRequest" BO_ 1958 1;
BA_ "GenMsgSendType" BO_ 2033 1;
BA_ "GenSigSendType" SG_ 2033 ACU_DiagReq 2;
BA_ "DiagRequest" BO_ 2033 1;
BA_ "GenMsgSendType" BO_ 1961 1;
BA_ "GenSigSendType" SG_ 1961 EPS_DiagReq 2;
BA_ "DiagRequest" BO_ 1961 1;
BA_ "GenMsgSendType" BO_ 1987 1;
BA_ "GenSigSendType" SG_ 1987 AVAS_DiagReq 2;
BA_ "DiagRequest" BO_ 1987 1;
BA_ "GenMsgSendType" BO_ 1984 1;
BA_ "GenSigSendType" SG_ 1984 ADCU_DiagReq 2;
BA_ "DiagRequest" BO_ 1984 1;
BA_ "GenMsgSendType" BO_ 1794 1;
BA_ "GenSigSendType" SG_ 1794 CGW_DiagResp 2;
BA_ "DiagResponse" BO_ 1794 1;
BA_ "GenMsgSendType" BO_ 1793 1;
BA_ "GenSigSendType" SG_ 1793 BCM1_DiagResp 2;
BA_ "DiagResponse" BO_ 1793 1;
BA_ "GenMsgSendType" BO_ 1818 1;
BA_ "GenSigSendType" SG_ 1818 BCM2_DiagResp 2;
BA_ "DiagResponse" BO_ 1818 1;
BA_ "GenMsgSendType" BO_ 1819 1;
BA_ "GenSigSendType" SG_ 1819 SCUL_DiagResp 2;
BA_ "DiagResponse" BO_ 1819 1;
BA_ "GenMsgSendType" BO_ 1820 1;
BA_ "GenSigSendType" SG_ 1820 SCUR_DiagResp 2;
BA_ "DiagResponse" BO_ 1820 1;
BA_ "GenMsgSendType" BO_ 1823 1;
BA_ "GenSigSendType" SG_ 1823 WCBS1_DiagResp 2;
BA_ "DiagResponse" BO_ 1823 1;
BA_ "GenMsgSendType" BO_ 1824 1;
BA_ "GenSigSendType" SG_ 1824 WCBS2_DiagResp 2;
BA_ "DiagResponse" BO_ 1824 1;
BA_ "GenMsgSendType" BO_ 1839 1;
BA_ "GenSigSendType" SG_ 1839 DCM_FL_DiagResp 2;
BA_ "DiagResponse" BO_ 1839 1;
BA_ "GenMsgSendType" BO_ 1847 1;
BA_ "GenSigSendType" SG_ 1847 DCM_FR_DiagResp 2;
BA_ "DiagResponse" BO_ 1847 1;
BA_ "GenMsgSendType" BO_ 1851 1;
BA_ "GenSigSendType" SG_ 1851 DCM_RL_DiagResp 2;
BA_ "DiagResponse" BO_ 1851 1;
BA_ "GenMsgSendType" BO_ 1852 1;
BA_ "GenSigSendType" SG_ 1852 DCM_RR_DiagResp 2;
BA_ "DiagResponse" BO_ 1852 1;
BA_ "GenMsgSendType" BO_ 1822 1;
BA_ "GenSigSendType" SG_ 1822 HLR_DiagResp 2;
BA_ "DiagResponse" BO_ 1822 1;
BA_ "GenMsgSendType" BO_ 1821 1;
BA_ "GenSigSendType" SG_ 1821 HLL_DiagResp 2;
BA_ "DiagResponse" BO_ 1821 1;
BA_ "GenMsgSendType" BO_ 1835 1;
BA_ "GenSigSendType" SG_ 1835 PAT_DiagResp 2;
BA_ "DiagResponse" BO_ 1835 1;
BA_ "GenMsgSendType" BO_ 1796 1;
BA_ "GenSigSendType" SG_ 1796 IVI_DiagResp 2;
BA_ "DiagResponse" BO_ 1796 1;
BA_ "GenMsgSendType" BO_ 1805 1;
BA_ "GenSigSendType" SG_ 1805 HUD_DiagResp 2;
BA_ "DiagResponse" BO_ 1805 1;
BA_ "GenMsgSendType" BO_ 1817 1;
BA_ "GenSigSendType" SG_ 1817 MFP_RC_DiagResp 2;
BA_ "DiagResponse" BO_ 1817 1;
BA_ "GenMsgSendType" BO_ 1814 1;
BA_ "GenSigSendType" SG_ 1814 MFP_FC_DiagResp 2;
BA_ "DiagResponse" BO_ 1814 1;
BA_ "GenMsgSendType" BO_ 1799 1;
BA_ "GenSigSendType" SG_ 1799 SWP_DiagResp 2;
BA_ "DiagResponse" BO_ 1799 1;
BA_ "GenMsgSendType" BO_ 1798 1;
BA_ "GenSigSendType" SG_ 1798 Switches_DiagResp 2;
BA_ "DiagResponse" BO_ 1798 1;
BA_ "GenMsgSendType" BO_ 1812 1;
BA_ "GenSigSendType" SG_ 1812 Switches2_DiagResp 2;
BA_ "DiagResponse" BO_ 1812 1;
BA_ "GenMsgSendType" BO_ 1801 1;
BA_ "GenSigSendType" SG_ 1801 HOD_heating_DiagResp 2;
BA_ "DiagResponse" BO_ 1801 1;
BA_ "GenMsgSendType" BO_ 1806 1;
BA_ "GenSigSendType" SG_ 1806 DIM_DiagResp 2;
BA_ "DiagResponse" BO_ 1806 1;
BA_ "GenMsgSendType" BO_ 1800 1;
BA_ "GenSigSendType" SG_ 1800 NDT_DiagResp 2;
BA_ "DiagResponse" BO_ 1800 1;
BA_ "GenMsgSendType" BO_ 1863 1;
BA_ "GenSigSendType" SG_ 1863 POD_DiagResp 2;
BA_ "DiagResponse" BO_ 1863 1;
BA_ "GenMsgSendType" BO_ 1811 1;
BA_ "GenSigSendType" SG_ 1811 BMS_DiagResp 2;
BA_ "DiagResponse" BO_ 1811 1;
BA_ "GenMsgSendType" BO_ 1864 1;
BA_ "GenSigSendType" SG_ 1864 TCU_DiagResp 2;
BA_ "DiagResponse" BO_ 1864 1;
BA_ "GenMsgSendType" BO_ 1870 1;
BA_ "GenSigSendType" SG_ 1870 AIRPTC_DiagResp 2;
BA_ "DiagResponse" BO_ 1870 1;
BA_ "GenMsgSendType" BO_ 1836 1;
BA_ "GenSigSendType" SG_ 1836 VCU_DiagResp 2;
BA_ "DiagResponse" BO_ 1836 1;
BA_ "GenMsgSendType" BO_ 1858 1;
BA_ "GenSigSendType" SG_ 1858 MCU_DiagResp 2;
BA_ "DiagResponse" BO_ 1858 1;
BA_ "GenMsgSendType" BO_ 1871 1;
BA_ "GenSigSendType" SG_ 1871 PRND_DiagResp 2;
BA_ "DiagResponse" BO_ 1871 1;
BA_ "GenMsgSendType" BO_ 1865 1;
BA_ "GenSigSendType" SG_ 1865 EVCOM_DiagResp 2;
BA_ "DiagResponse" BO_ 1865 1;
BA_ "GenMsgSendType" BO_ 1830 1;
BA_ "GenSigSendType" SG_ 1830 IBS_DiagResp 2;
BA_ "DiagResponse" BO_ 1830 1;
BA_ "GenMsgSendType" BO_ 2041 1;
BA_ "GenSigSendType" SG_ 2041 ACU_DiagResp 2;
BA_ "DiagResponse" BO_ 2041 1;
BA_ "GenMsgSendType" BO_ 1859 1;
BA_ "GenSigSendType" SG_ 1859 AVAS_DiagResp 2;
BA_ "DiagResponse" BO_ 1859 1;
BA_ "GenMsgSendType" BO_ 1833 1;
BA_ "GenSigSendType" SG_ 1833 EPS_DiagResp 2;
BA_ "DiagResponse" BO_ 1833 1;
BA_ "GenMsgSendType" BO_ 1856 1;
BA_ "GenSigSendType" SG_ 1856 ADCU_DiagResp 2;
BA_ "DiagResponse" BO_ 1856 1;
BA_ "GenMsgCycleTime" BO_ 1027 1000;
BA_ "GenMsgCycleTime" BO_ 1029 1000;
BA_ "GenMsgCycleTime" BO_ 1034 1000;
BA_ "GenMsgCycleTime" BO_ 1026 1000;
BA_ "GenMsgCycleTime" BO_ 1025 1000;
BA_ "GenMsgCycleTime" BO_ 1050 1000;
BA_ "GenMsgCycleTime" BO_ 1051 1000;
BA_ "GenMsgCycleTime" BO_ 1052 1000;
BA_ "GenMsgCycleTime" BO_ 1055 1000;
BA_ "GenMsgCycleTime" BO_ 1056 1000;
BA_ "GenMsgCycleTime" BO_ 1071 1000;
BA_ "GenMsgCycleTime" BO_ 1083 1000;
BA_ "GenMsgCycleTime" BO_ 1079 1000;
BA_ "GenMsgCycleTime" BO_ 1084 1000;
BA_ "GenMsgCycleTime" BO_ 1086 1000;
BA_ "GenMsgCycleTime" BO_ 1053 1000;
BA_ "GenMsgCycleTime" BO_ 1067 1000;
BA_ "GenMsgCycleTime" BO_ 1088 1000;
BA_ "GenMsgCycleTime" BO_ 1092 1000;
BA_ "GenMsgCycleTime" BO_ 1037 1000;
BA_ "GenMsgCycleTime" BO_ 1049 1000;
BA_ "GenMsgCycleTime" BO_ 1046 1000;
BA_ "GenMsgCycleTime" BO_ 1031 1000;
BA_ "GenMsgCycleTime" BO_ 1030 1000;
BA_ "GenMsgCycleTime" BO_ 1033 1000;
BA_ "GenMsgCycleTime" BO_ 1038 1000;
BA_ "GenMsgCycleTime" BO_ 1032 1000;
BA_ "GenMsgCycleTime" BO_ 1095 1000;
BA_ "GenMsgCycleTime" BO_ 1043 1000;
BA_ "GenMsgCycleTime" BO_ 1096 1000;
BA_ "GenMsgCycleTime" BO_ 1102 1000;
BA_ "GenMsgCycleTime" BO_ 1068 1000;
BA_ "GenMsgCycleTime" BO_ 1090 1000;
BA_ "GenMsgCycleTime" BO_ 1103 1000;
BA_ "GenMsgCycleTime" BO_ 1097 1000;
BA_ "GenMsgCycleTime" BO_ 1062 1000;
BA_ "GenMsgCycleTime" BO_ 1273 1000;
BA_ "GenMsgCycleTime" BO_ 1091 1000;
BA_ "GenMsgCycleTime" BO_ 1065 1000;
BA_ "GenMsgCycleTime" BO_ 947 1000;
BA_ "GenMsgCycleTime" BO_ 948 1000;
BA_ "GenMsgCycleTime" BO_ 1537 50;
BA_ "GenMsgCycleTime" BO_ 1538 50;
VAL_ 852 IVI_FLAmbientColorReq 0 "NO Request" 1 "Colour1" 2 "Colour2" 3 "Colour3" 4 "Colour4" 5 "Colour5" 6 "Colour6" 7 "Colour7" 8 "Colour8" 9 "Colour9" 10 "Colour10" 11 "Colour11" 12 "Colour12" 13 "Colour13" 14 "Colour14" 15 "Colour15" 16 "Colour16" 17 "Colour17" 18 "Colour18" 19 "Colour19" 20 "Colour20" 21 "Colour21" 22 "Colour22" 23 "Colour23" 24 "Colour24" 25 "Colour25" 26 "Colour26" 27 "Colour27" 28 "Colour28" 29 "Colour29" 30 "Colour30" 31 "Colour31" 32 "Colour32" 33 "Colour33" 34 "Colour34" 35 "Colour35" 36 "Colour36" 37 "Colour37" 38 "Colour38" 39 "Colour39" 40 "Colour40" 41 "Colour41" 42 "Colour42" 43 "Colour43" 44 "Colour44" 45 "Colour45" 46 "Colour46" 47 "Colour47" 48 "Colour48" 49 "Colour49" 50 "Colour50" 51 "Colour51" 52 "Colour52" 53 "Colour53" 54 "Colour54" 55 "Colour55" 56 "Colour56" 57 "Colour57" 58 "Colour58" 59 "Colour59" 60 "Colour60" 61 "Colour61" 62 "Colour62" 63 "Colour63" 64 "Colour64" 65 "Reserved" 66 "Reserved" 67 "Reserved" 68 "Reserved" 69 "Reserved" 70 "Reserved" 71 "Reserved" 72 "Reserved" 73 "Reserved" 74 "Reserved" 75 "Reserved" 76 "Reserved" 77 "Reserved" 78 "Reserved" 79 "Reserved" 80 "Reserved" 81 "Reserved" 82 "Reserved" 83 "Reserved" 84 "Reserved" 85 "Reserved" 86 "Reserved" 87 "Reserved" 88 "Reserved" 89 "Reserved" 90 "Reserved" 91 "Reserved" 92 "Reserved" 93 "Reserved" 94 "Reserved" 95 "Reserved" 96 "Reserved" 97 "Reserved" 98 "Reserved" 99 "Reserved" 100 "Reserved" 101 "Reserved" 102 "Reserved" 103 "Reserved" 104 "Reserved" 105 "Reserved" 106 "Reserved" 107 "Reserved" 108 "Reserved" 109 "Reserved" 110 "Reserved" 111 "Reserved" 112 "Reserved" 113 "Reserved" 114 "Reserved" 115 "Reserved" 116 "Reserved" 117 "Reserved" 118 "Reserved" 119 "Reserved" 120 "Reserved" 121 "Reserved" 122 "Reserved" 123 "Reserved" 124 "Reserved" 125 "Reserved" 126 "Reserved" 127 "Reserved" 128 "Reserved" 129 "Reserved" 130 "Reserved" 131 "Reserved" 132 "Reserved" 133 "Reserved" 134 "Reserved" 135 "Reserved" 136 "Reserved" 137 "Reserved" 138 "Reserved" 139 "Reserved" 140 "Reserved" 141 "Reserved" 142 "Reserved" 143 "Reserved" 144 "Reserved" 145 "Reserved" 146 "Reserved" 147 "Reserved" 148 "Reserved" 149 "Reserved" 150 "Reserved" 151 "Reserved" 152 "Reserved" 153 "Reserved" 154 "Reserved" 155 "Reserved" 156 "Reserved" 157 "Reserved" 158 "Reserved" 159 "Reserved" 160 "Reserved" 161 "Reserved" 162 "Reserved" 163 "Reserved" 164 "Reserved" 165 "Reserved" 166 "Reserved" 167 "Reserved" 168 "Reserved" 169 "Reserved" 170 "Reserved" 171 "Reserved" 172 "Reserved" 173 "Reserved" 174 "Reserved" 175 "Reserved" 176 "Reserved" 177 "Reserved" 178 "Reserved" 179 "Reserved" 180 "Reserved" 181 "Reserved" 182 "Reserved" 183 "Reserved" 184 "Reserved" 185 "Reserved" 186 "Reserved" 187 "Reserved" 188 "Reserved" 189 "Reserved" 190 "Reserved" 191 "Reserved" 192 "Reserved" 193 "Reserved" 194 "Reserved" 195 "Reserved" 196 "Reserved" 197 "Reserved" 198 "Reserved" 199 "Reserved" 200 "Reserved" 201 "Reserved" 202 "Reserved" 203 "Reserved" 204 "Reserved" 205 "Reserved" 206 "Reserved" 207 "Reserved" 208 "Reserved" 209 "Reserved" 210 "Reserved" 211 "Reserved" 212 "Reserved" 213 "Reserved" 214 "Reserved" 215 "Reserved" 216 "Reserved" 217 "Reserved" 218 "Reserved" 219 "Reserved" 220 "Reserved" 221 "Reserved" 222 "Reserved" 223 "Reserved" 224 "Reserved" 225 "Reserved" 226 "Reserved" 227 "Reserved" 228 "Reserved" 229 "Reserved" 230 "Reserved" 231 "Reserved" 232 "Reserved" 233 "Reserved" 234 "Reserved" 235 "Reserved" 236 "Reserved" 237 "Reserved" 238 "Reserved" 239 "Reserved" 240 "Reserved" 241 "Reserved" 242 "Reserved" 243 "Reserved" 244 "Reserved" 245 "Reserved" 246 "Reserved" 247 "Reserved" 248 "Reserved" 249 "Reserved" 250 "Reserved" 251 "Reserved" 252 "Reserved" 253 "Reserved" 254 "Reserved" 255 "Reserved" ;
VAL_ 852 IVI_FRAmbientColorReq 0 "NO Request" 1 "Colour1" 2 "Colour2" 3 "Colour3" 4 "Colour4" 5 "Colour5" 6 "Colour6" 7 "Colour7" 8 "Colour8" 9 "Colour9" 10 "Colour10" 11 "Colour11" 12 "Colour12" 13 "Colour13" 14 "Colour14" 15 "Colour15" 16 "Colour16" 17 "Colour17" 18 "Colour18" 19 "Colour19" 20 "Colour20" 21 "Colour21" 22 "Colour22" 23 "Colour23" 24 "Colour24" 25 "Colour25" 26 "Colour26" 27 "Colour27" 28 "Colour28" 29 "Colour29" 30 "Colour30" 31 "Colour31" 32 "Colour32" 33 "Colour33" 34 "Colour34" 35 "Colour35" 36 "Colour36" 37 "Colour37" 38 "Colour38" 39 "Colour39" 40 "Colour40" 41 "Colour41" 42 "Colour42" 43 "Colour43" 44 "Colour44" 45 "Colour45" 46 "Colour46" 47 "Colour47" 48 "Colour48" 49 "Colour49" 50 "Colour50" 51 "Colour51" 52 "Colour52" 53 "Colour53" 54 "Colour54" 55 "Colour55" 56 "Colour56" 57 "Colour57" 58 "Colour58" 59 "Colour59" 60 "Colour60" 61 "Colour61" 62 "Colour62" 63 "Colour63" 64 "Colour64" 65 "Reserved" 66 "Reserved" 67 "Reserved" 68 "Reserved" 69 "Reserved" 70 "Reserved" 71 "Reserved" 72 "Reserved" 73 "Reserved" 74 "Reserved" 75 "Reserved" 76 "Reserved" 77 "Reserved" 78 "Reserved" 79 "Reserved" 80 "Reserved" 81 "Reserved" 82 "Reserved" 83 "Reserved" 84 "Reserved" 85 "Reserved" 86 "Reserved" 87 "Reserved" 88 "Reserved" 89 "Reserved" 90 "Reserved" 91 "Reserved" 92 "Reserved" 93 "Reserved" 94 "Reserved" 95 "Reserved" 96 "Reserved" 97 "Reserved" 98 "Reserved" 99 "Reserved" 100 "Reserved" 101 "Reserved" 102 "Reserved" 103 "Reserved" 104 "Reserved" 105 "Reserved" 106 "Reserved" 107 "Reserved" 108 "Reserved" 109 "Reserved" 110 "Reserved" 111 "Reserved" 112 "Reserved" 113 "Reserved" 114 "Reserved" 115 "Reserved" 116 "Reserved" 117 "Reserved" 118 "Reserved" 119 "Reserved" 120 "Reserved" 121 "Reserved" 122 "Reserved" 123 "Reserved" 124 "Reserved" 125 "Reserved" 126 "Reserved" 127 "Reserved" 128 "Reserved" 129 "Reserved" 130 "Reserved" 131 "Reserved" 132 "Reserved" 133 "Reserved" 134 "Reserved" 135 "Reserved" 136 "Reserved" 137 "Reserved" 138 "Reserved" 139 "Reserved" 140 "Reserved" 141 "Reserved" 142 "Reserved" 143 "Reserved" 144 "Reserved" 145 "Reserved" 146 "Reserved" 147 "Reserved" 148 "Reserved" 149 "Reserved" 150 "Reserved" 151 "Reserved" 152 "Reserved" 153 "Reserved" 154 "Reserved" 155 "Reserved" 156 "Reserved" 157 "Reserved" 158 "Reserved" 159 "Reserved" 160 "Reserved" 161 "Reserved" 162 "Reserved" 163 "Reserved" 164 "Reserved" 165 "Reserved" 166 "Reserved" 167 "Reserved" 168 "Reserved" 169 "Reserved" 170 "Reserved" 171 "Reserved" 172 "Reserved" 173 "Reserved" 174 "Reserved" 175 "Reserved" 176 "Reserved" 177 "Reserved" 178 "Reserved" 179 "Reserved" 180 "Reserved" 181 "Reserved" 182 "Reserved" 183 "Reserved" 184 "Reserved" 185 "Reserved" 186 "Reserved" 187 "Reserved" 188 "Reserved" 189 "Reserved" 190 "Reserved" 191 "Reserved" 192 "Reserved" 193 "Reserved" 194 "Reserved" 195 "Reserved" 196 "Reserved" 197 "Reserved" 198 "Reserved" 199 "Reserved" 200 "Reserved" 201 "Reserved" 202 "Reserved" 203 "Reserved" 204 "Reserved" 205 "Reserved" 206 "Reserved" 207 "Reserved" 208 "Reserved" 209 "Reserved" 210 "Reserved" 211 "Reserved" 212 "Reserved" 213 "Reserved" 214 "Reserved" 215 "Reserved" 216 "Reserved" 217 "Reserved" 218 "Reserved" 219 "Reserved" 220 "Reserved" 221 "Reserved" 222 "Reserved" 223 "Reserved" 224 "Reserved" 225 "Reserved" 226 "Reserved" 227 "Reserved" 228 "Reserved" 229 "Reserved" 230 "Reserved" 231 "Reserved" 232 "Reserved" 233 "Reserved" 234 "Reserved" 235 "Reserved" 236 "Reserved" 237 "Reserved" 238 "Reserved" 239 "Reserved" 240 "Reserved" 241 "Reserved" 242 "Reserved" 243 "Reserved" 244 "Reserved" 245 "Reserved" 246 "Reserved" 247 "Reserved" 248 "Reserved" 249 "Reserved" 250 "Reserved" 251 "Reserved" 252 "Reserved" 253 "Reserved" 254 "Reserved" 255 "Reserved" ;
VAL_ 852 IVI_RLAmbientColorReq 0 "NO Request" 1 "Colour1" 2 "Colour2" 3 "Colour3" 4 "Colour4" 5 "Colour5" 6 "Colour6" 7 "Colour7" 8 "Colour8" 9 "Colour9" 10 "Colour10" 11 "Colour11" 12 "Colour12" 13 "Colour13" 14 "Colour14" 15 "Colour15" 16 "Colour16" 17 "Colour17" 18 "Colour18" 19 "Colour19" 20 "Colour20" 21 "Colour21" 22 "Colour22" 23 "Colour23" 24 "Colour24" 25 "Colour25" 26 "Colour26" 27 "Colour27" 28 "Colour28" 29 "Colour29" 30 "Colour30" 31 "Colour31" 32 "Colour32" 33 "Colour33" 34 "Colour34" 35 "Colour35" 36 "Colour36" 37 "Colour37" 38 "Colour38" 39 "Colour39" 40 "Colour40" 41 "Colour41" 42 "Colour42" 43 "Colour43" 44 "Colour44" 45 "Colour45" 46 "Colour46" 47 "Colour47" 48 "Colour48" 49 "Colour49" 50 "Colour50" 51 "Colour51" 52 "Colour52" 53 "Colour53" 54 "Colour54" 55 "Colour55" 56 "Colour56" 57 "Colour57" 58 "Colour58" 59 "Colour59" 60 "Colour60" 61 "Colour61" 62 "Colour62" 63 "Colour63" 64 "Colour64" 65 "Reserved" 66 "Reserved" 67 "Reserved" 68 "Reserved" 69 "Reserved" 70 "Reserved" 71 "Reserved" 72 "Reserved" 73 "Reserved" 74 "Reserved" 75 "Reserved" 76 "Reserved" 77 "Reserved" 78 "Reserved" 79 "Reserved" 80 "Reserved" 81 "Reserved" 82 "Reserved" 83 "Reserved" 84 "Reserved" 85 "Reserved" 86 "Reserved" 87 "Reserved" 88 "Reserved" 89 "Reserved" 90 "Reserved" 91 "Reserved" 92 "Reserved" 93 "Reserved" 94 "Reserved" 95 "Reserved" 96 "Reserved" 97 "Reserved" 98 "Reserved" 99 "Reserved" 100 "Reserved" 101 "Reserved" 102 "Reserved" 103 "Reserved" 104 "Reserved" 105 "Reserved" 106 "Reserved" 107 "Reserved" 108 "Reserved" 109 "Reserved" 110 "Reserved" 111 "Reserved" 112 "Reserved" 113 "Reserved" 114 "Reserved" 115 "Reserved" 116 "Reserved" 117 "Reserved" 118 "Reserved" 119 "Reserved" 120 "Reserved" 121 "Reserved" 122 "Reserved" 123 "Reserved" 124 "Reserved" 125 "Reserved" 126 "Reserved" 127 "Reserved" 128 "Reserved" 129 "Reserved" 130 "Reserved" 131 "Reserved" 132 "Reserved" 133 "Reserved" 134 "Reserved" 135 "Reserved" 136 "Reserved" 137 "Reserved" 138 "Reserved" 139 "Reserved" 140 "Reserved" 141 "Reserved" 142 "Reserved" 143 "Reserved" 144 "Reserved" 145 "Reserved" 146 "Reserved" 147 "Reserved" 148 "Reserved" 149 "Reserved" 150 "Reserved" 151 "Reserved" 152 "Reserved" 153 "Reserved" 154 "Reserved" 155 "Reserved" 156 "Reserved" 157 "Reserved" 158 "Reserved" 159 "Reserved" 160 "Reserved" 161 "Reserved" 162 "Reserved" 163 "Reserved" 164 "Reserved" 165 "Reserved" 166 "Reserved" 167 "Reserved" 168 "Reserved" 169 "Reserved" 170 "Reserved" 171 "Reserved" 172 "Reserved" 173 "Reserved" 174 "Reserved" 175 "Reserved" 176 "Reserved" 177 "Reserved" 178 "Reserved" 179 "Reserved" 180 "Reserved" 181 "Reserved" 182 "Reserved" 183 "Reserved" 184 "Reserved" 185 "Reserved" 186 "Reserved" 187 "Reserved" 188 "Reserved" 189 "Reserved" 190 "Reserved" 191 "Reserved" 192 "Reserved" 193 "Reserved" 194 "Reserved" 195 "Reserved" 196 "Reserved" 197 "Reserved" 198 "Reserved" 199 "Reserved" 200 "Reserved" 201 "Reserved" 202 "Reserved" 203 "Reserved" 204 "Reserved" 205 "Reserved" 206 "Reserved" 207 "Reserved" 208 "Reserved" 209 "Reserved" 210 "Reserved" 211 "Reserved" 212 "Reserved" 213 "Reserved" 214 "Reserved" 215 "Reserved" 216 "Reserved" 217 "Reserved" 218 "Reserved" 219 "Reserved" 220 "Reserved" 221 "Reserved" 222 "Reserved" 223 "Reserved" 224 "Reserved" 225 "Reserved" 226 "Reserved" 227 "Reserved" 228 "Reserved" 229 "Reserved" 230 "Reserved" 231 "Reserved" 232 "Reserved" 233 "Reserved" 234 "Reserved" 235 "Reserved" 236 "Reserved" 237 "Reserved" 238 "Reserved" 239 "Reserved" 240 "Reserved" 241 "Reserved" 242 "Reserved" 243 "Reserved" 244 "Reserved" 245 "Reserved" 246 "Reserved" 247 "Reserved" 248 "Reserved" 249 "Reserved" 250 "Reserved" 251 "Reserved" 252 "Reserved" 253 "Reserved" 254 "Reserved" 255 "Reserved" ;
VAL_ 852 IVI_RRAmbientColorReq 0 "NO Request" 1 "Colour1" 2 "Colour2" 3 "Colour3" 4 "Colour4" 5 "Colour5" 6 "Colour6" 7 "Colour7" 8 "Colour8" 9 "Colour9" 10 "Colour10" 11 "Colour11" 12 "Colour12" 13 "Colour13" 14 "Colour14" 15 "Colour15" 16 "Colour16" 17 "Colour17" 18 "Colour18" 19 "Colour19" 20 "Colour20" 21 "Colour21" 22 "Colour22" 23 "Colour23" 24 "Colour24" 25 "Colour25" 26 "Colour26" 27 "Colour27" 28 "Colour28" 29 "Colour29" 30 "Colour30" 31 "Colour31" 32 "Colour32" 33 "Colour33" 34 "Colour34" 35 "Colour35" 36 "Colour36" 37 "Colour37" 38 "Colour38" 39 "Colour39" 40 "Colour40" 41 "Colour41" 42 "Colour42" 43 "Colour43" 44 "Colour44" 45 "Colour45" 46 "Colour46" 47 "Colour47" 48 "Colour48" 49 "Colour49" 50 "Colour50" 51 "Colour51" 52 "Colour52" 53 "Colour53" 54 "Colour54" 55 "Colour55" 56 "Colour56" 57 "Colour57" 58 "Colour58" 59 "Colour59" 60 "Colour60" 61 "Colour61" 62 "Colour62" 63 "Colour63" 64 "Colour64" 65 "Reserved" 66 "Reserved" 67 "Reserved" 68 "Reserved" 69 "Reserved" 70 "Reserved" 71 "Reserved" 72 "Reserved" 73 "Reserved" 74 "Reserved" 75 "Reserved" 76 "Reserved" 77 "Reserved" 78 "Reserved" 79 "Reserved" 80 "Reserved" 81 "Reserved" 82 "Reserved" 83 "Reserved" 84 "Reserved" 85 "Reserved" 86 "Reserved" 87 "Reserved" 88 "Reserved" 89 "Reserved" 90 "Reserved" 91 "Reserved" 92 "Reserved" 93 "Reserved" 94 "Reserved" 95 "Reserved" 96 "Reserved" 97 "Reserved" 98 "Reserved" 99 "Reserved" 100 "Reserved" 101 "Reserved" 102 "Reserved" 103 "Reserved" 104 "Reserved" 105 "Reserved" 106 "Reserved" 107 "Reserved" 108 "Reserved" 109 "Reserved" 110 "Reserved" 111 "Reserved" 112 "Reserved" 113 "Reserved" 114 "Reserved" 115 "Reserved" 116 "Reserved" 117 "Reserved" 118 "Reserved" 119 "Reserved" 120 "Reserved" 121 "Reserved" 122 "Reserved" 123 "Reserved" 124 "Reserved" 125 "Reserved" 126 "Reserved" 127 "Reserved" 128 "Reserved" 129 "Reserved" 130 "Reserved" 131 "Reserved" 132 "Reserved" 133 "Reserved" 134 "Reserved" 135 "Reserved" 136 "Reserved" 137 "Reserved" 138 "Reserved" 139 "Reserved" 140 "Reserved" 141 "Reserved" 142 "Reserved" 143 "Reserved" 144 "Reserved" 145 "Reserved" 146 "Reserved" 147 "Reserved" 148 "Reserved" 149 "Reserved" 150 "Reserved" 151 "Reserved" 152 "Reserved" 153 "Reserved" 154 "Reserved" 155 "Reserved" 156 "Reserved" 157 "Reserved" 158 "Reserved" 159 "Reserved" 160 "Reserved" 161 "Reserved" 162 "Reserved" 163 "Reserved" 164 "Reserved" 165 "Reserved" 166 "Reserved" 167 "Reserved" 168 "Reserved" 169 "Reserved" 170 "Reserved" 171 "Reserved" 172 "Reserved" 173 "Reserved" 174 "Reserved" 175 "Reserved" 176 "Reserved" 177 "Reserved" 178 "Reserved" 179 "Reserved" 180 "Reserved" 181 "Reserved" 182 "Reserved" 183 "Reserved" 184 "Reserved" 185 "Reserved" 186 "Reserved" 187 "Reserved" 188 "Reserved" 189 "Reserved" 190 "Reserved" 191 "Reserved" 192 "Reserved" 193 "Reserved" 194 "Reserved" 195 "Reserved" 196 "Reserved" 197 "Reserved" 198 "Reserved" 199 "Reserved" 200 "Reserved" 201 "Reserved" 202 "Reserved" 203 "Reserved" 204 "Reserved" 205 "Reserved" 206 "Reserved" 207 "Reserved" 208 "Reserved" 209 "Reserved" 210 "Reserved" 211 "Reserved" 212 "Reserved" 213 "Reserved" 214 "Reserved" 215 "Reserved" 216 "Reserved" 217 "Reserved" 218 "Reserved" 219 "Reserved" 220 "Reserved" 221 "Reserved" 222 "Reserved" 223 "Reserved" 224 "Reserved" 225 "Reserved" 226 "Reserved" 227 "Reserved" 228 "Reserved" 229 "Reserved" 230 "Reserved" 231 "Reserved" 232 "Reserved" 233 "Reserved" 234 "Reserved" 235 "Reserved" 236 "Reserved" 237 "Reserved" 238 "Reserved" 239 "Reserved" 240 "Reserved" 241 "Reserved" 242 "Reserved" 243 "Reserved" 244 "Reserved" 245 "Reserved" 246 "Reserved" 247 "Reserved" 248 "Reserved" 249 "Reserved" 250 "Reserved" 251 "Reserved" 252 "Reserved" 253 "Reserved" 254 "Reserved" 255 "Reserved" ;
VAL_ 852 IVI_IPAmbientColorReq 0 "NO Request" 1 "Colour1" 2 "Colour2" 3 "Colour3" 4 "Colour4" 5 "Colour5" 6 "Colour6" 7 "Colour7" 8 "Colour8" 9 "Colour9" 10 "Colour10" 11 "Colour11" 12 "Colour12" 13 "Colour13" 14 "Colour14" 15 "Colour15" 16 "Colour16" 17 "Colour17" 18 "Colour18" 19 "Colour19" 20 "Colour20" 21 "Colour21" 22 "Colour22" 23 "Colour23" 24 "Colour24" 25 "Colour25" 26 "Colour26" 27 "Colour27" 28 "Colour28" 29 "Colour29" 30 "Colour30" 31 "Colour31" 32 "Colour32" 33 "Colour33" 34 "Colour34" 35 "Colour35" 36 "Colour36" 37 "Colour37" 38 "Colour38" 39 "Colour39" 40 "Colour40" 41 "Colour41" 42 "Colour42" 43 "Colour43" 44 "Colour44" 45 "Colour45" 46 "Colour46" 47 "Colour47" 48 "Colour48" 49 "Colour49" 50 "Colour50" 51 "Colour51" 52 "Colour52" 53 "Colour53" 54 "Colour54" 55 "Colour55" 56 "Colour56" 57 "Colour57" 58 "Colour58" 59 "Colour59" 60 "Colour60" 61 "Colour61" 62 "Colour62" 63 "Colour63" 64 "Colour64" 65 "Reserved" 66 "Reserved" 67 "Reserved" 68 "Reserved" 69 "Reserved" 70 "Reserved" 71 "Reserved" 72 "Reserved" 73 "Reserved" 74 "Reserved" 75 "Reserved" 76 "Reserved" 77 "Reserved" 78 "Reserved" 79 "Reserved" 80 "Reserved" 81 "Reserved" 82 "Reserved" 83 "Reserved" 84 "Reserved" 85 "Reserved" 86 "Reserved" 87 "Reserved" 88 "Reserved" 89 "Reserved" 90 "Reserved" 91 "Reserved" 92 "Reserved" 93 "Reserved" 94 "Reserved" 95 "Reserved" 96 "Reserved" 97 "Reserved" 98 "Reserved" 99 "Reserved" 100 "Reserved" 101 "Reserved" 102 "Reserved" 103 "Reserved" 104 "Reserved" 105 "Reserved" 106 "Reserved" 107 "Reserved" 108 "Reserved" 109 "Reserved" 110 "Reserved" 111 "Reserved" 112 "Reserved" 113 "Reserved" 114 "Reserved" 115 "Reserved" 116 "Reserved" 117 "Reserved" 118 "Reserved" 119 "Reserved" 120 "Reserved" 121 "Reserved" 122 "Reserved" 123 "Reserved" 124 "Reserved" 125 "Reserved" 126 "Reserved" 127 "Reserved" 128 "Reserved" 129 "Reserved" 130 "Reserved" 131 "Reserved" 132 "Reserved" 133 "Reserved" 134 "Reserved" 135 "Reserved" 136 "Reserved" 137 "Reserved" 138 "Reserved" 139 "Reserved" 140 "Reserved" 141 "Reserved" 142 "Reserved" 143 "Reserved" 144 "Reserved" 145 "Reserved" 146 "Reserved" 147 "Reserved" 148 "Reserved" 149 "Reserved" 150 "Reserved" 151 "Reserved" 152 "Reserved" 153 "Reserved" 154 "Reserved" 155 "Reserved" 156 "Reserved" 157 "Reserved" 158 "Reserved" 159 "Reserved" 160 "Reserved" 161 "Reserved" 162 "Reserved" 163 "Reserved" 164 "Reserved" 165 "Reserved" 166 "Reserved" 167 "Reserved" 168 "Reserved" 169 "Reserved" 170 "Reserved" 171 "Reserved" 172 "Reserved" 173 "Reserved" 174 "Reserved" 175 "Reserved" 176 "Reserved" 177 "Reserved" 178 "Reserved" 179 "Reserved" 180 "Reserved" 181 "Reserved" 182 "Reserved" 183 "Reserved" 184 "Reserved" 185 "Reserved" 186 "Reserved" 187 "Reserved" 188 "Reserved" 189 "Reserved" 190 "Reserved" 191 "Reserved" 192 "Reserved" 193 "Reserved" 194 "Reserved" 195 "Reserved" 196 "Reserved" 197 "Reserved" 198 "Reserved" 199 "Reserved" 200 "Reserved" 201 "Reserved" 202 "Reserved" 203 "Reserved" 204 "Reserved" 205 "Reserved" 206 "Reserved" 207 "Reserved" 208 "Reserved" 209 "Reserved" 210 "Reserved" 211 "Reserved" 212 "Reserved" 213 "Reserved" 214 "Reserved" 215 "Reserved" 216 "Reserved" 217 "Reserved" 218 "Reserved" 219 "Reserved" 220 "Reserved" 221 "Reserved" 222 "Reserved" 223 "Reserved" 224 "Reserved" 225 "Reserved" 226 "Reserved" 227 "Reserved" 228 "Reserved" 229 "Reserved" 230 "Reserved" 231 "Reserved" 232 "Reserved" 233 "Reserved" 234 "Reserved" 235 "Reserved" 236 "Reserved" 237 "Reserved" 238 "Reserved" 239 "Reserved" 240 "Reserved" 241 "Reserved" 242 "Reserved" 243 "Reserved" 244 "Reserved" 245 "Reserved" 246 "Reserved" 247 "Reserved" 248 "Reserved" 249 "Reserved" 250 "Reserved" 251 "Reserved" 252 "Reserved" 253 "Reserved" 254 "Reserved" 255 "Reserved" ;
VAL_ 852 IVI_FLAmbientLightReq 0 "NO Request" 1 "OFF" 2 "ON" ;
VAL_ 852 IVI_FRAmbientLightReq 0 "NO Request" 1 "OFF" 2 "ON" ;
VAL_ 852 IVI_RLAmbientLightReq 0 "NO Request" 1 "OFF" 2 "ON" ;
VAL_ 852 IVI_RRAmbientLightReq 0 "NO Request" 1 "OFF" 2 "ON" ;
VAL_ 852 IVI_IPAmbientLightReq 0 "NO Request" 1 "OFF" 2 "ON" ;
VAL_ 575 SGW_L_RearSeatHeatSet 0 "No Request" 1 "OFF" 2 "ON" 3 "INVALID" ;
VAL_ 575 SGW_R_RearSeatHeatSet 0 "No Request" 1 "OFF" 2 "ON" 3 "INVALID" ;
VAL_ 575 SGW_DrSeatWelcomeLevelSet 0 "NO Request" 1 "Low" 2 "High" 3 "INVALID" ;
VAL_ 575 SGW_PsSeatWelcomeLevelSet 0 "NO Request" 1 "Low" 2 "High" 3 "INVALID" ;
VAL_ 575 SGW_MirrorAutoTurnDownSet 0 "NO Request" 1 "OFF" 2 "ON" 3 "INVALID" ;
VAL_ 575 SGW_WelcomeOnOffSet 0 "Default" 1 "OFF" 2 "ON" 3 "INVALID" ;
VAL_ 575 SGW_PassWelcomeOnOffSet 0 "Default" 1 "OFF" 2 "ON" 3 "INVALID" ;
VAL_ 256 IVI_ResetReq 0 "NO Request" 1 "ON" ;
VAL_ 256 IVI_AutoScreenBacklight 0 "No request" 1 "OFF" 2 "ON" 3 "Reserved" ;
VAL_ 256 IVI_ScreenBrightnessSet 0 "0Level" 1 "1Level" 2 "2Level" 3 "3Level" 4 "4Level" 5 "5Level" 6 "6Level" 7 "7Level" 8 "8Level" 9 "9Level" 10 "10Level" 11 "Reserved" 12 "Reserved" 13 "Reserved" 14 "Reserved" 15 "Reserved" 16 "Reserved" 17 "Reserved" 18 "Reserved" 19 "Reserved" 20 "Reserved" 21 "Reserved" 22 "Reserved" 23 "Reserved" 24 "Reserved" 25 "Reserved" 26 "Reserved" 27 "Reserved" 28 "Reserved" 29 "Reserved" 30 "Reserved" 31 "Invalid" ;
VAL_ 256 IVI_AVASOnOffSet 0 "NO Request" 1 "OFF" 2 "ON" 3 "Reserved" ;
VAL_ 256 IVI_AVASSoundSet 0 "No request" 1 "Sound1" 2 "Sound2" 3 "Sound3" 4 "Sound4" 5 "Sound5" 6 "Reserve" 7 "Reserve" 8 "Reserve" 9 "Reserve" ;
VAL_ 256 IVI_PassAirbagOpenSet 0 "NO Request" 1 "CLOSE" 2 "OPEN" 3 "Reserved" ;
VAL_ 256 IVI_WCBSReminderSet 0 "No Request" 1 "Disable" 2 "Enable" 3 "Reserved" ;
VAL_ 256 IVI_HazardWarmReq 0 "No Request" 1 "Off" 2 "On" ;
VAL_ 256 IVI_ThanksHazardWarmReq 0 "No request" 1 "Request" ;
VAL_ 256 IVI_WelInteriorLightSet 0 "No request" 1 "Disable" 2 "Enable" ;
VAL_ 256 IVI_PriorSoundSet 0 "NO Request" 1 "Disable" 2 "Enable" 3 "Reserved" ;
VAL_ 256 IVI_FrontKeepOpenSet 0 "NO Request" 1 "Disable" 2 "Enable" 3 "Reserved" ;
VAL_ 259 IVI_L_DsSeatBackPos 254 "No Request" 255 "OFF" ;
VAL_ 259 IVI_L_DsSeatHeightPos 254 "No Request" 255 "OFF" ;
VAL_ 259 IVI_L_DsSeatSlidePos 254 "No Request" 255 "OFF" ;
VAL_ 259 IVI_DrSeatHeatLevelSet 0 "No Request" 1 "Seat Heat Off" 2 "Level1" 3 "Level2" 4 "Level3" 5 "Reserved" 6 "Reserved" 7 "Reserved" ;
VAL_ 259 IVI_DrSeatWelcomeLevelSet 0 "NO Request" 1 "Low" 2 "High" 3 "Reserved" ;
VAL_ 260 IVI_R_DsSeatSlidePos 254 "No Request" 255 "OFF" ;
VAL_ 260 IVI_R_DsSeatHeightPos 254 "No Request" 255 "OFF" ;
VAL_ 260 IVI_R_DsSeatBackPos 254 "No Request" 255 "OFF" ;
VAL_ 260 IVI_PassSeatHeatLevelSet 0 "No Request" 1 "Seat Heat Off" 2 "Level1" 3 "Level2" 4 "Level3" 5 "Reserved" 6 "Reserved" 7 "Reserved" ;
VAL_ 260 IVI_PsSeatWelcomeLevelSet 0 "NO Request" 1 "Low" 2 "High" 3 "Reserved" ;
VAL_ 264 SGW_FR_FrontRearReq 0 "Noactive" 1 "Front" 2 "Rear" ;
VAL_ 264 SGW_FR_HeightMotorReq 0 "Noactive" 1 "Up" 2 "Down" ;
VAL_ 264 SGW_FR_BackrestMotorReq 0 "Noactive" 1 "Front" 2 "Rear" ;
VAL_ 710 IVI_StWAnglePos 254 "No Request" 255 "OFF" ;
VAL_ 710 IVI_StWLengthPos 254 "No Request" 255 "OFF" ;
VAL_ 563 IVI_MirrorFold_UnfoldSet 0 "SW Not Pressed" 1 "SW Pressed" ;
VAL_ 563 IVI_MirrorAutoTurnDownSet 0 "No Request" 1 "OFF" 2 "ON" 3 "Reserved" ;
VAL_ 563 IVI_MirrorAutoFoldUnfoldSet 0 "NO Request" 1 "OFF" 2 "ON" 3 "Reserved" ;
VAL_ 563 IVI_LeftMirrorHorizontalPos 254 "No Request" 255 "OFF" ;
VAL_ 563 IVI_LeftMirrorVerticalPos 254 "No Request" 255 "OFF" ;
VAL_ 563 IVI_RightMirrorHorizontalPos 254 "No Request" 255 "OFF" ;
VAL_ 563 IVI_RightMirrorVerticalPos 254 "No Request" 255 "OFF" ;
VAL_ 574 IVI_FLDoorLockSet 0 "No Request" 1 "UNLOCK" 2 "LOCK" 3 "Reserved" ;
VAL_ 574 IVI_FRDoorLockSet 0 "No Request" 1 "UNLOCK" 2 "LOCK" 3 "Reserved" ;
VAL_ 574 IVI_RLDoorLockSet 0 "No Request" 1 "UNLOCK" 2 "LOCK" 3 "Reserved" ;
VAL_ 574 IVI_RRDoorLockSet 0 "No Request" 1 "UNLOCK" 2 "LOCK" 3 "Reserved" ;
VAL_ 574 IVI_PassWindowLockSet 0 "NO Request" 1 "UNLOCK" 2 "LOCK" 3 "Reserved" ;
VAL_ 574 IVI_ModeEnterReq 0 "No request" 1 "Ventilation mode" 2 "Close mode" 3 "Reserved" 4 "Reserved" 5 "Reserved" 6 "Reserved" 7 "Reserved" 8 "Reserved" 9 "Reserved" 10 "Reserved" 11 "Reserved" 12 "Reserved" 13 "Reserved" 14 "Reserved" 15 "Reserved" ;
VAL_ 689 IVI_HUDALTITUDESet 0 "No request" 1 "-8 level" 2 "-7 level" 3 "-6 level" 4 "-5 level" 5 "-4 level" 6 "-3 level" 7 "-2 level" 8 "-1 level" 9 "0 level" 10 "1 level" 11 "2 level" 12 "3 level" 13 "4 level" 14 "5 level" 15 "6 level" 16 "7 level" 17 "8 level" 18 "reserved" 19 "reserved" 20 "reserved" 21 "reserved" 22 "reserved" 23 "reserved" 24 "reserved" 25 "reserved" 26 "reserved" 27 "reserved" 28 "reserved" 29 "reserved" 30 "reserved" 31 "reserved" 32 "reserved" 33 "reserved" 34 "reserved" 35 "reserved" 36 "reserved" 37 "reserved" 38 "reserved" 39 "reserved" 40 "reserved" 41 "reserved" 42 "reserved" 43 "reserved" 44 "reserved" 45 "reserved" 46 "reserved" 47 "reserved" 48 "reserved" 49 "reserved" 50 "reserved" 51 "reserved" 52 "reserved" 53 "reserved" 54 "reserved" 55 "reserved" 56 "reserved" 57 "reserved" 58 "reserved" 59 "reserved" 60 "reserved" 61 "reserved" 62 "reserved" 63 "reserved" 64 "reserved" 65 "reserved" 66 "reserved" 67 "reserved" 68 "reserved" 69 "reserved" 70 "reserved" 71 "reserved" 72 "reserved" 73 "reserved" 74 "reserved" 75 "reserved" 76 "reserved" 77 "reserved" 78 "reserved" 79 "reserved" 80 "reserved" 81 "reserved" 82 "reserved" 83 "reserved" 84 "reserved" 85 "reserved" 86 "reserved" 87 "reserved" 88 "reserved" 89 "reserved" 90 "reserved" 91 "reserved" 92 "reserved" 93 "reserved" 94 "reserved" 95 "reserved" 96 "reserved" 97 "reserved" 98 "reserved" 99 "reserved" 100 "reserved" 101 "reserved" 102 "reserved" 103 "reserved" 104 "reserved" 105 "reserved" 106 "reserved" 107 "reserved" 108 "reserved" 109 "reserved" 110 "reserved" 111 "reserved" 112 "reserved" 113 "reserved" 114 "reserved" 115 "reserved" 116 "reserved" 117 "reserved" 118 "reserved" 119 "reserved" 120 "reserved" 121 "reserved" 122 "reserved" 123 "reserved" 124 "reserved" 125 "reserved" 126 "reserved" 127 "reserved" 128 "reserved" 129 "reserved" 130 "reserved" 131 "reserved" 132 "reserved" 133 "reserved" 134 "reserved" 135 "reserved" 136 "reserved" 137 "reserved" 138 "reserved" 139 "reserved" 140 "reserved" 141 "reserved" 142 "reserved" 143 "reserved" 144 "reserved" 145 "reserved" 146 "reserved" 147 "reserved" 148 "reserved" 149 "reserved" 150 "reserved" 151 "reserved" 152 "reserved" 153 "reserved" 154 "reserved" 155 "reserved" 156 "reserved" 157 "reserved" 158 "reserved" 159 "reserved" 160 "reserved" 161 "reserved" 162 "reserved" 163 "reserved" 164 "reserved" 165 "reserved" 166 "reserved" 167 "reserved" 168 "reserved" 169 "reserved" 170 "reserved" 171 "reserved" 172 "reserved" 173 "reserved" 174 "reserved" 175 "reserved" 176 "reserved" 177 "reserved" 178 "reserved" 179 "reserved" 180 "reserved" 181 "reserved" 182 "reserved" 183 "reserved" 184 "reserved" 185 "reserved" 186 "reserved" 187 "reserved" 188 "reserved" 189 "reserved" 190 "reserved" 191 "reserved" 192 "reserved" 193 "reserved" 194 "reserved" 195 "reserved" 196 "reserved" 197 "reserved" 198 "reserved" 199 "reserved" 200 "reserved" 201 "reserved" 202 "reserved" 203 "reserved" 204 "reserved" 205 "reserved" 206 "reserved" 207 "reserved" 208 "reserved" 209 "reserved" 210 "reserved" 211 "reserved" 212 "reserved" 213 "reserved" 214 "reserved" 215 "reserved" 216 "reserved" 217 "reserved" 218 "reserved" 219 "reserved" 220 "reserved" 221 "reserved" 222 "reserved" 223 "reserved" 224 "reserved" 225 "reserved" 226 "reserved" 227 "reserved" 228 "reserved" 229 "reserved" 230 "reserved" 231 "reserved" 232 "reserved" 233 "reserved" 234 "reserved" 235 "reserved" 236 "reserved" 237 "reserved" 238 "reserved" 239 "reserved" 240 "reserved" 241 "reserved" 242 "reserved" 243 "reserved" 244 "reserved" 245 "reserved" 246 "reserved" 247 "reserved" 248 "reserved" 249 "reserved" 250 "reserved" 251 "reserved" 252 "reserved" 253 "reserved" 254 "reserved" 255 "reserved" ;
VAL_ 689 IVI_HUDOnOffSet 0 "No Request" 1 "OFF" 2 "ON" 3 "RESERVED" ;
VAL_ 561 IVI_ESCOffSet 0 "NO Request" 1 "OFF" 2 "ON" 3 "Reserved" ;
VAL_ 561 IVI_TPMS_Reset 0 "No request" 1 "Active" ;
VAL_ 561 IVI_HDCOffSet 0 "No Request" 1 "OFF" 2 "ON" 3 "RESERVED" ;
VAL_ 561 IVI_AVHSet 0 "No Request" 1 "OFF" 2 "ON" 3 "RESERVED" ;
VAL_ 561 IVI_SteeringModeSet 0 "No Request" 1 "Normal" 2 "Sport" 3 "Comfort" ;
VAL_ 561 IVI_BrakeCompensateCmd 0 "NO Request" 1 "OFF" 2 "ON" 3 "Reserved" ;
VAL_ 561 IVI_CRLevelSet 0 "No request" 1 "OFF" 2 "Primary energy recovery (weak)" 3 "Secondary energy recovery(medium)" 4 "Tertiary energy recovery (strong)" 5 "Reserved" 6 "Reserved" 7 "Reserved" ;
VAL_ 790 VCU_OdometerInforValid 0 "Invalid" 1 "Valid" ;
VAL_ 790 VCU_VINComparisonResults 0 "Not equal" 1 "Equal" ;
VAL_ 945 SGW_OdometerInforValid 0 "Invalid" 1 "Valid" ;
VAL_ 946 SGW_VIN 0 "Invalid" 1 "Valid" ;
VAL_ 693 IVI_AppointChargeCmd 0 "No Request" 1 "Charge ON" 2 "Charge OFF" ;
VAL_ 693 IVI_ForwardVmaxlimitSw 0 "No Request" 1 "OFF" 2 "ON" 3 "Reserved" ;
VAL_ 693 IVI_KeepWarmRequest 0 "No request" 1 "OFF" 2 "ON" ;
VAL_ 693 IVI_LockACPlug 0 "No request" 1 "UnLock" 2 "Lock" ;
VAL_ 693 IVI_LV_LimitPop 0 "No request" 1 "Cancel" 2 "Open" ;
VAL_ 694 IVI_GearRequest 0 "NO request" 1 "P" 2 "N" 3 "R" 4 "D" 5 "Invaild" ;
VAL_ 261 SGW_RemoteAirCondAUTOReq 0 "No action" 1 "Pressed" 2 "Reserved" 3 "Reserved" ;
VAL_ 261 SGW_RemoteAirCondOnOFFReq 0 "No action" 1 "On" 2 "Off" 3 "INVALID" ;
VAL_ 261 SGW_RearDoorAngleSet 0 "No Request" 1 "Fully Open" 2 "Half Open" ;
VAL_ 261 SGW_FrontDoorAngleSet 0 "No Request" 1 "Fully Open" 2 "Half Open" ;
VAL_ 261 SGW_RemoteFrontDefrostReq 0 "No action" 1 "On" 2 "Off" 3 "INVALID" ;
VAL_ 261 SGW_RemoteSteerHeatReq 0 "No Request" 1 "OFF" 2 "ON" 3 "INVALID" ;
VAL_ 261 SGW_RemoteDrSeatHeatReq 0 "No Request" 1 "Seat Heat Off" 2 "Level1" 3 "Level2" 4 "Level3" ;
VAL_ 261 SGW_LeftChdLockCtrlReq 0 "No request" 1 "Deactive" 2 "Active" ;
VAL_ 261 SGW_RearDefrostCtrlSet 0 "OFF" 1 "ON" ;
VAL_ 261 SGW_RemoteFrontWindHeatReq 0 "NO_COMMAND" 1 "OFF" 2 "ON" 3 "INVALID" ;
VAL_ 261 SGW_RemoteRearMirHeatReq 0 "NO_COMMAND" 1 "OFF" 2 "ON" 3 "INVALID" ;
VAL_ 261 SGW_RemotePassSeatHeatReq 0 "No Request" 1 "Seat Heat Off" 2 "Level1" 3 "Level2" 4 "Level3" ;
VAL_ 261 SGW_oneTouchCoolSet 0 "No Request" 1 "Open" 2 "Close" ;
VAL_ 261 SGW_RemoteRearWindHeatReq 0 "NO_COMMAND" 1 "OFF" 2 "ON" 3 "INVALID" ;
VAL_ 261 SGW_TakePicCtrl 0 "No Request" 1 "DVR photo" 2 "ROA photo" 3 "DMS photo" 4 "DVR video" 5 "ROA video" 6 "DMS VIdeo" 7 "Reserved" ;
VAL_ 261 SGW_RemoteACOnOffReq 0 "NO_REQUEST" 1 "OFF" 2 "ON" ;
VAL_ 261 SGW_RightChdLockCtrlReq 0 "No request" 1 "Deactive" 2 "Active" ;
VAL_ 261 SGW_RemoteTailgateLockCtrlReq 0 "No Request" 1 "Unlock" 2 "Lock" 3 "Reserved" ;
VAL_ 261 SGW_HDCOffSet 0 "No Request" 1 "OFF" 2 "ON" 3 "Reserved" ;
VAL_ 261 SGW_AVHSet 0 "No Request" 1 "OFF" 2 "ON" 3 "Reserved" ;
VAL_ 261 SGW_SteeringModeSet 0 "No Request" 1 "Normal" 2 "Sport" 3 "Comfort" ;
VAL_ 261 SGW_AVASSoundSet 0 "No request" 1 "Sound1" 2 "Sound2" 3 "Sound3" 4 "Sound4" 5 "Sound5" 6 "Reserved" 7 "Reserved" 8 "Reserved" 9 "Reserved" ;
VAL_ 261 SGW_DriveModeSet 0 "No Request" 1 "ECO" 2 "NORMAL" 3 "SPORT" 4 "OnePedal" ;
VAL_ 261 SGW_ImuCarParkBeStolen 0 "No warning" 1 "Lifting" 2 "Towing" 3 "Jacking" 4 "Crash" ;
VAL_ 262 IVI_HUDScreenBrightnessSet 0 "0Level" 1 "1Level" 2 "2Level" 3 "3Level" 4 "4Level" 5 "5Level" 6 "6Level" 7 "7Level" 8 "8Level" 9 "9Level" 10 "10Level" 11 "Reserved" 12 "Reserved" 13 "Reserved" 14 "Reserved" 15 "Reserved" 16 "Reserved" 17 "Reserved" 18 "Reserved" 19 "Reserved" 20 "Reserved" 21 "Reserved" 22 "Reserved" 23 "Reserved" 24 "Reserved" 25 "Reserved" 26 "Reserved" 27 "Reserved" 28 "Reserved" 29 "Reserved" 30 "Reserved" 31 "Invalid" ;
VAL_ 263 SGW_AutoCloseWinFunSet 0 "No Request" 1 "No Active" 2 "Active" ;
VAL_ 263 SGW_RemoteDrvSetTempSteplsReq 0 "No request" 1 "17(Low)" 2 "17.5" 3 "18" 4 "18.5" 5 "19" 6 "19.5" 7 "20" 8 "20.5" 9 "21" 10 "21.5" 11 "22" 12 "22.5" 13 "23" 14 "23.5" 15 "24" 16 "24.5" 17 "25" 18 "25.5" 19 "26" 20 "26.5" 21 "27" 22 "27.5" 23 "28(High)" 24 "Reserved" 25 "Reserved" 26 "Reserved" 27 "Reserved" 28 "Reserved" 29 "Reserved" 30 "Reserved" 31 "Reserved" 32 "Reserved" 33 "Reserved" 34 "Reserved" 35 "Reserved" 36 "Reserved" 37 "Reserved" 38 "Reserved" 39 "Reserved" 40 "Reserved" 41 "Reserved" 42 "Reserved" 43 "Reserved" 44 "Reserved" 45 "Reserved" 46 "Reserved" 47 "Reserved" 48 "Reserved" 49 "Reserved" 50 "Reserved" 51 "Reserved" 52 "Reserved" 53 "Reserved" 54 "Reserved" 55 "Reserved" 56 "Reserved" 57 "Reserved" 58 "Reserved" 59 "Reserved" 60 "Reserved" 61 "Reserved" 62 "Reserved" 63 "Reserved" ;
VAL_ 263 SGW_FrontWiperAutoSet 0 "No Request" 1 "Disable" 2 "Enable" ;
VAL_ 263 SGW_RemotePassSetTempSteplsReq 0 "No request" 1 "17(Low)" 2 "17.5" 3 "18" 4 "18.5" 5 "19" 6 "19.5" 7 "20" 8 "20.5" 9 "21" 10 "21.5" 11 "22" 12 "22.5" 13 "23" 14 "23.5" 15 "24" 16 "24.5" 17 "25" 18 "25.5" 19 "26" 20 "26.5" 21 "27" 22 "27.5" 23 "28(High)" 24 "Reserved" 25 "Reserved" 26 "Reserved" 27 "Reserved" 28 "Reserved" 29 "Reserved" 30 "Reserved" 31 "Reserved" 32 "Reserved" 33 "Reserved" 34 "Reserved" 35 "Reserved" 36 "Reserved" 37 "Reserved" 38 "Reserved" 39 "Reserved" 40 "Reserved" 41 "Reserved" 42 "Reserved" 43 "Reserved" 44 "Reserved" 45 "Reserved" 46 "Reserved" 47 "Reserved" 48 "Reserved" 49 "Reserved" 50 "Reserved" 51 "Reserved" 52 "Reserved" 53 "Reserved" 54 "Reserved" 55 "Reserved" 56 "Reserved" 57 "Reserved" 58 "Reserved" 59 "Reserved" 60 "Reserved" 61 "Reserved" 62 "Reserved" 63 "Reserved" ;
VAL_ 263 SGW_AllDoorReq 0 "No request" 1 "Open" 2 "Closed" ;
VAL_ 263 SGW_RemoteCarSearchReq 0 "NO_REQUEST" 1 "OFF" 2 "ON" 3 "Reserved" ;
VAL_ 263 SGW_RemoteLockCtrlReq 0 "No Request" 1 "Unlock" 2 "Lock" 3 "Reserved" ;
VAL_ 263 SGW_RRDoorReq 0 "No request" 1 "Open" 2 "Closed" ;
VAL_ 263 SGW_RLDoorReq 0 "No request" 1 "Open" 2 "Closed" ;
VAL_ 263 SGW_FRDoorReq 0 "No request" 1 "Open" 2 "Closed" ;
VAL_ 263 SGW_FLDoorReq 0 "No request" 1 "Open" 2 "Closed" ;
VAL_ 263 SGW_WelInteriorLightSet 0 "No request" 1 "Disable" 2 "Enable" ;
VAL_ 263 SGW_CarSharingLightSet 0 "No request" 1 "Disable" 2 "Enable" ;
VAL_ 263 SGW_CarSharingColorSet 0 "NO Request" 1 "Colour1" 2 "Colour2" 3 "Colour3" 4 "Colour4" 5 "Colour5" 6 "Colour6" 7 "Colour7" 8 "Colour8" 9 "Colour9" 10 "Colour10" 11 "Colour11" 12 "Colour12" 13 "Colour13" 14 "Colour14" 15 "Colour15" 16 "Colour16" 17 "Colour17" 18 "Colour18" 19 "Colour19" 20 "Colour20" 21 "Colour21" 22 "Colour22" 23 "Colour23" 24 "Colour24" 25 "Colour25" 26 "Colour26" 27 "Colour27" 28 "Colour28" 29 "Colour29" 30 "Colour30" 31 "Colour31" 32 "Colour32" 33 "Colour33" 34 "Colour34" 35 "Colour35" 36 "Colour36" 37 "Colour37" 38 "Colour38" 39 "Colour39" 40 "Colour40" 41 "Colour41" 42 "Colour42" 43 "Colour43" 44 "Colour44" 45 "Colour45" 46 "Colour46" 47 "Colour47" 48 "Colour48" 49 "Colour49" 50 "Colour50" 51 "Colour51" 52 "Colour52" 53 "Colour53" 54 "Colour54" 55 "Colour55" 56 "Colour56" 57 "Colour57" 58 "Colour58" 59 "Colour59" 60 "Colour60" 61 "Colour61" 62 "Colour62" 63 "Colour63" 64 "Colour64" 65 "Reserved" 66 "Reserved" 67 "Reserved" 68 "Reserved" 69 "Reserved" 70 "Reserved" 71 "Reserved" 72 "Reserved" 73 "Reserved" 74 "Reserved" 75 "Reserved" 76 "Reserved" 77 "Reserved" 78 "Reserved" 79 "Reserved" 80 "Reserved" 81 "Reserved" 82 "Reserved" 83 "Reserved" 84 "Reserved" 85 "Reserved" 86 "Reserved" 87 "Reserved" 88 "Reserved" 89 "Reserved" 90 "Reserved" 91 "Reserved" 92 "Reserved" 93 "Reserved" 94 "Reserved" 95 "Reserved" 96 "Reserved" 97 "Reserved" 98 "Reserved" 99 "Reserved" 100 "Reserved" 101 "Reserved" 102 "Reserved" 103 "Reserved" 104 "Reserved" 105 "Reserved" 106 "Reserved" 107 "Reserved" 108 "Reserved" 109 "Reserved" 110 "Reserved" 111 "Reserved" 112 "Reserved" 113 "Reserved" 114 "Reserved" 115 "Reserved" 116 "Reserved" 117 "Reserved" 118 "Reserved" 119 "Reserved" 120 "Reserved" 121 "Reserved" 122 "Reserved" 123 "Reserved" 124 "Reserved" 125 "Reserved" 126 "Reserved" 127 "Reserved" 128 "Reserved" 129 "Reserved" 130 "Reserved" 131 "Reserved" 132 "Reserved" 133 "Reserved" 134 "Reserved" 135 "Reserved" 136 "Reserved" 137 "Reserved" 138 "Reserved" 139 "Reserved" 140 "Reserved" 141 "Reserved" 142 "Reserved" 143 "Reserved" 144 "Reserved" 145 "Reserved" 146 "Reserved" 147 "Reserved" 148 "Reserved" 149 "Reserved" 150 "Reserved" 151 "Reserved" 152 "Reserved" 153 "Reserved" 154 "Reserved" 155 "Reserved" 156 "Reserved" 157 "Reserved" 158 "Reserved" 159 "Reserved" 160 "Reserved" 161 "Reserved" 162 "Reserved" 163 "Reserved" 164 "Reserved" 165 "Reserved" 166 "Reserved" 167 "Reserved" 168 "Reserved" 169 "Reserved" 170 "Reserved" 171 "Reserved" 172 "Reserved" 173 "Reserved" 174 "Reserved" 175 "Reserved" 176 "Reserved" 177 "Reserved" 178 "Reserved" 179 "Reserved" 180 "Reserved" 181 "Reserved" 182 "Reserved" 183 "Reserved" 184 "Reserved" 185 "Reserved" 186 "Reserved" 187 "Reserved" 188 "Reserved" 189 "Reserved" 190 "Reserved" 191 "Reserved" 192 "Reserved" 193 "Reserved" 194 "Reserved" 195 "Reserved" 196 "Reserved" 197 "Reserved" 198 "Reserved" 199 "Reserved" 200 "Reserved" 201 "Reserved" 202 "Reserved" 203 "Reserved" 204 "Reserved" 205 "Reserved" 206 "Reserved" 207 "Reserved" 208 "Reserved" 209 "Reserved" 210 "Reserved" 211 "Reserved" 212 "Reserved" 213 "Reserved" 214 "Reserved" 215 "Reserved" 216 "Reserved" 217 "Reserved" 218 "Reserved" 219 "Reserved" 220 "Reserved" 221 "Reserved" 222 "Reserved" 223 "Reserved" 224 "Reserved" 225 "Reserved" 226 "Reserved" 227 "Reserved" 228 "Reserved" 229 "Reserved" 230 "Reserved" 231 "Reserved" 232 "Reserved" 233 "Reserved" 234 "Reserved" 235 "Reserved" 236 "Reserved" 237 "Reserved" 238 "Reserved" 239 "Reserved" 240 "Reserved" 241 "Reserved" 242 "Reserved" 243 "Reserved" 244 "Reserved" 245 "Reserved" 246 "Reserved" 247 "Reserved" 248 "Reserved" 249 "Reserved" 250 "Reserved" 251 "Reserved" 252 "Reserved" 253 "Reserved" 254 "Reserved" 255 "Reserved" ;
VAL_ 263 SGW_CarSharingTimeSet 0 "No request" 1 "1" 2 "2" 3 "3" 4 "4" 5 "5" 6 "6" 7 "7" 8 "8" 9 "9" 10 "10" ;
VAL_ 263 SGW_FRDomeLampSet 0 "No request" 1 "OFF" 2 "ON" ;
VAL_ 263 SGW_RRDomeLampSet 0 "No request" 1 "OFF" 2 "ON" ;
VAL_ 316 SGW_L_MirrorMainHorizontalPos 254 "No Request" ;
VAL_ 316 SGW_L_MirrorMainVerticalPos 254 "No Request" ;
VAL_ 316 SGW_R_MirrorMainHorizontalPos 254 "No Request" ;
VAL_ 316 SGW_R_MirrorMainVerticalPos 254 "No Request" ;
VAL_ 316 SGW_L_MirrorTiltHorizontalPos 254 "No Request" ;
VAL_ 316 SGW_L_MirrorTiltVerticalPos 254 "No Request" ;
VAL_ 316 SGW_R_MirrorTiltHorizontalPos 254 "No Request" ;
VAL_ 316 SGW_R_MirrorTiltVerticalPos 254 "No Request" 255 "OFF" ;
VAL_ 315 SGW_DrSeatSlidePos 254 "No Request" 255 "OFF" ;
VAL_ 315 SGW_DrSeatHeightPos 254 "No Request" ;
VAL_ 315 SGW_DrSeatBackPos 254 "No Request" ;
VAL_ 315 SGW_StWLengthPos 254 "No Request" 255 "OFF" ;
VAL_ 315 SGW_StWAnglePos 254 "No Request" ;
VAL_ 315 SGW_MirrorAutoFoldUnfoldSet 0 "NO Request" 1 "OFF" 2 "ON" 3 "Reserved" ;
VAL_ 315 SGW_WCBSReminderSet 0 "NO Request" 1 "Disable" 2 "Enable" 3 "Reserved" ;
VAL_ 315 SGW_AutoLmpSet 0 "NO Request" 1 "OFF" 2 "ON" 3 "Reserved" ;
VAL_ 315 SGW_DippedBeamSet 0 "NO Request" 1 "OFF" 2 "ON" 3 "Reserved" ;
VAL_ 315 SGW_HUDHeightSet 0 "-8 level" 1 "-7 level" 2 "-6 level" 3 "-5 level" 4 "-4 level" 5 "-3 level" 6 "-2 level" 7 "-1 level" 8 "0 level" 9 "1 level" 10 "2 level" 11 "3 level" 12 "4 level" 13 "5 level" 14 "6 level" 15 "7 level" 16 "8 level" 17 "Reserved" 18 "Reserved" 19 "Reserved" 20 "Reserved" 21 "Reserved" 22 "Reserved" 23 "Reserved" 24 "Reserved" 25 "Reserved" 26 "Reserved" 27 "Reserved" 28 "Reserved" 29 "Reserved" 30 "Reserved" 31 "Reserved" 32 "Reserved" 33 "Reserved" 34 "Reserved" 35 "Reserved" 36 "Reserved" 37 "Reserved" 38 "Reserved" 39 "Reserved" 40 "Reserved" 41 "Reserved" 42 "Reserved" 43 "Reserved" 44 "Reserved" 45 "Reserved" 46 "Reserved" 47 "Reserved" 48 "Reserved" 49 "Reserved" 50 "Reserved" 51 "Reserved" 52 "Reserved" 53 "Reserved" 54 "Reserved" 55 "Reserved" 56 "Reserved" 57 "Reserved" 58 "Reserved" 59 "Reserved" 60 "Reserved" 61 "Reserved" 62 "Reserved" 63 "Reserved" 64 "Reserved" 65 "Reserved" 66 "Reserved" 67 "Reserved" 68 "Reserved" 69 "Reserved" 70 "Reserved" 71 "Reserved" 72 "Reserved" 73 "Reserved" 74 "Reserved" 75 "Reserved" 76 "Reserved" 77 "Reserved" 78 "Reserved" 79 "Reserved" 80 "Reserved" 81 "Reserved" 82 "Reserved" 83 "Reserved" 84 "Reserved" 85 "Reserved" 86 "Reserved" 87 "Reserved" 88 "Reserved" 89 "Reserved" 90 "Reserved" 91 "Reserved" 92 "Reserved" 93 "Reserved" 94 "Reserved" 95 "Reserved" 96 "Reserved" 97 "Reserved" 98 "Reserved" 99 "Reserved" 100 "Reserved" 101 "Reserved" 102 "Reserved" 103 "Reserved" 104 "Reserved" 105 "Reserved" 106 "Reserved" 107 "Reserved" 108 "Reserved" 109 "Reserved" 110 "Reserved" 111 "Reserved" 112 "Reserved" 113 "Reserved" 114 "Reserved" 115 "Reserved" 116 "Reserved" 117 "Reserved" 118 "Reserved" 119 "Reserved" 120 "Reserved" 121 "Reserved" 122 "Reserved" 123 "Reserved" 124 "Reserved" 125 "Reserved" 126 "Reserved" 127 "Reserved" 128 "Reserved" 129 "Reserved" 130 "Reserved" 131 "Reserved" 132 "Reserved" 133 "Reserved" 134 "Reserved" 135 "Reserved" 136 "Reserved" 137 "Reserved" 138 "Reserved" 139 "Reserved" 140 "Reserved" 141 "Reserved" 142 "Reserved" 143 "Reserved" 144 "Reserved" 145 "Reserved" 146 "Reserved" 147 "Reserved" 148 "Reserved" 149 "Reserved" 150 "Reserved" 151 "Reserved" 152 "Reserved" 153 "Reserved" 154 "Reserved" 155 "Reserved" 156 "Reserved" 157 "Reserved" 158 "Reserved" 159 "Reserved" 160 "Reserved" 161 "Reserved" 162 "Reserved" 163 "Reserved" 164 "Reserved" 165 "Reserved" 166 "Reserved" 167 "Reserved" 168 "Reserved" 169 "Reserved" 170 "Reserved" 171 "Reserved" 172 "Reserved" 173 "Reserved" 174 "Reserved" 175 "Reserved" 176 "Reserved" 177 "Reserved" 178 "Reserved" 179 "Reserved" 180 "Reserved" 181 "Reserved" 182 "Reserved" 183 "Reserved" 184 "Reserved" 185 "Reserved" 186 "Reserved" 187 "Reserved" 188 "Reserved" 189 "Reserved" 190 "Reserved" 191 "Reserved" 192 "Reserved" 193 "Reserved" 194 "Reserved" 195 "Reserved" 196 "Reserved" 197 "Reserved" 198 "Reserved" 199 "Reserved" 200 "Reserved" 201 "Reserved" 202 "Reserved" 203 "Reserved" 204 "Reserved" 205 "Reserved" 206 "Reserved" 207 "Reserved" 208 "Reserved" 209 "Reserved" 210 "Reserved" 211 "Reserved" 212 "Reserved" 213 "Reserved" 214 "Reserved" 215 "Reserved" 216 "Reserved" 217 "Reserved" 218 "Reserved" 219 "Reserved" 220 "Reserved" 221 "Reserved" 222 "Reserved" 223 "Reserved" 224 "Reserved" 225 "Reserved" 226 "Reserved" 227 "Reserved" 228 "Reserved" 229 "Reserved" 230 "Reserved" 231 "Reserved" 232 "Reserved" 233 "Reserved" 234 "Reserved" 235 "Reserved" 236 "Reserved" 237 "Reserved" 238 "Reserved" 239 "Reserved" 240 "Reserved" 241 "Reserved" 242 "Reserved" 243 "Reserved" 244 "Reserved" 245 "Reserved" 246 "Reserved" 247 "Reserved" 248 "Reserved" 249 "Reserved" 250 "Reserved" 251 "Reserved" 252 "Reserved" 253 "Reserved" 254 "Reserved" 255 "Reserved" ;
VAL_ 315 SGW_HUDBrightnessSet 0 "0Level" 1 "1Level" 2 "2Level" 3 "3Level" 4 "4Level" 5 "5Level" 6 "6Level" 7 "7Level" 8 "8Level" 9 "9Level" 10 "10Level" 11 "Reserved" 12 "Reserved" 13 "Reserved" 14 "Reserved" 15 "Reserved" 16 "Reserved" 17 "Reserved" 18 "Reserved" 19 "Reserved" 20 "Reserved" 21 "Reserved" 22 "Reserved" 23 "Reserved" 24 "Reserved" 25 "Reserved" 26 "Reserved" 27 "Reserved" 28 "Reserved" 29 "Reserved" 30 "Reserved" 31 "Invalid" ;
VAL_ 314 SGW_RemoteFLWinPosiCtlCmd 0 "No Request" 1 "0%" 2 "5%" 3 "10%" 4 "15%" 5 "20%" 6 "25%" 7 "30%" 8 "35%" 9 "40%" 10 "45%" 11 "50%" 12 "55%" 13 "60%" 14 "65%" 15 "70%" 16 "75%" 17 "80%" 18 "85%" 19 "90%" 20 "95%" 21 "100%" ;
VAL_ 314 SGW_RemoteFRWinPosiCtlCmd 0 "No Request" 1 "0%" 2 "5%" 3 "10%" 4 "15%" 5 "20%" 6 "25%" 7 "30%" 8 "35%" 9 "40%" 10 "45%" 11 "50%" 12 "55%" 13 "60%" 14 "65%" 15 "70%" 16 "75%" 17 "80%" 18 "85%" 19 "90%" 20 "95%" 21 "100%" ;
VAL_ 314 SGW_RemoteRLWinPosiCtlCmd 0 "No Request" 1 "0%" 2 "5%" 3 "10%" 4 "15%" 5 "20%" 6 "25%" 7 "30%" 8 "35%" 9 "40%" 10 "45%" 11 "50%" 12 "55%" 13 "60%" 14 "65%" 15 "70%" 16 "75%" 17 "80%" 18 "85%" 19 "90%" 20 "95%" 21 "100%" ;
VAL_ 314 SGW_RemoteRRWinPosiCtlCmd 0 "No Request" 1 "0%" 2 "5%" 3 "10%" 4 "15%" 5 "20%" 6 "25%" 7 "30%" 8 "35%" 9 "40%" 10 "45%" 11 "50%" 12 "55%" 13 "60%" 14 "65%" 15 "70%" 16 "75%" 17 "80%" 18 "85%" 19 "90%" 20 "95%" 21 "100%" ;
VAL_ 314 SGW_PassWindowLockSet 0 "NO Request" 1 "UNLOCK" 2 "LOCK" 3 "Reserved" ;
VAL_ 314 SGW_LeftKeyReHornMode 0 "No Request" 1 "Normal Mode" 2 "Silence Mode" ;
VAL_ 314 SGW_LockDoorOpenReHornMode 0 "No Request" 1 "Normal Mode" 2 "Silence Mode" ;
VAL_ 314 SGW_AntiTheftReHornMode 0 "No Request" 1 "Normal Mode" 2 "Silence Mode" ;
VAL_ 314 SGW_PosnLmpSet 0 "No Request" 1 "Off" 2 "On" ;
VAL_ 314 SGW_AutoLampSenReq 0 "No request" 1 "Early" 2 "Standard" 3 "Late" ;
VAL_ 314 SGW_CornerLampSet 0 "NO Request" 1 "OFF" 2 "ON" 3 "Reserved" ;
VAL_ 314 SGW_BacklightAutoSet 0 "No request" 1 "Disable" 2 "Enable" ;
VAL_ 314 SGW_BacklightadjustSet 0 "No Request" 1 "0%" 2 "10%" 3 "16%" 4 "22%" 5 "28%" 6 "34%" 7 "40%" 8 "50%" 9 "70%" 10 "80%" 11 "85%" 12 "90%" 13 "100%" ;
VAL_ 562 SGW_DrvSetTempSteplsReq 0 "No request" 1 "17(Low)" 2 "17.5" 3 "18" 4 "18.5" 5 "19" 6 "19.5" 7 "20" 8 "20.5" 9 "21" 10 "21.5" 11 "22" 12 "22.5" 13 "23" 14 "23.5" 15 "24" 16 "24.5" 17 "25" 18 "25.5" 19 "26" 20 "26.5" 21 "27" 22 "27.5" 23 "28(High)" 24 "Reserved" 25 "Reserved" 26 "Reserved" 27 "Reserved" 28 "Reserved" 29 "Reserved" 30 "Reserved" 31 "Reserved" 32 "Reserved" 33 "Reserved" 34 "Reserved" 35 "Reserved" 36 "Reserved" 37 "Reserved" 38 "Reserved" 39 "Reserved" 40 "Reserved" 41 "Reserved" 42 "Reserved" 43 "Reserved" 44 "Reserved" 45 "Reserved" 46 "Reserved" 47 "Reserved" 48 "Reserved" 49 "Reserved" 50 "Reserved" 51 "Reserved" 52 "Reserved" 53 "Reserved" 54 "Reserved" 55 "Reserved" 56 "Reserved" 57 "Reserved" 58 "Reserved" 59 "Reserved" 60 "Reserved" 61 "Reserved" 62 "Reserved" 63 "Reserved" ;
VAL_ 562 SGW_DemistReq 0 "NO Request" 1 "Off" 2 "On" 3 "Reserved" ;
VAL_ 562 SGW_HVACBatterySaveModeSetReq 0 "NO Request" 1 "Off" 2 "On" 3 "Reserved" ;
VAL_ 562 SGW_PassSetTempSteplsReq 0 "No request" 1 "17(Low)" 2 "17.5" 3 "18" 4 "18.5" 5 "19" 6 "19.5" 7 "20" 8 "20.5" 9 "21" 10 "21.5" 11 "22" 12 "22.5" 13 "23" 14 "23.5" 15 "24" 16 "24.5" 17 "25" 18 "25.5" 19 "26" 20 "26.5" 21 "27" 22 "27.5" 23 "28(High)" 24 "Reserved" 25 "Reserved" 26 "Reserved" 27 "Reserved" 28 "Reserved" 29 "Reserved" 30 "Reserved" 31 "Reserved" 32 "Reserved" 33 "Reserved" 34 "Reserved" 35 "Reserved" 36 "Reserved" 37 "Reserved" 38 "Reserved" 39 "Reserved" 40 "Reserved" 41 "Reserved" 42 "Reserved" 43 "Reserved" 44 "Reserved" 45 "Reserved" 46 "Reserved" 47 "Reserved" 48 "Reserved" 49 "Reserved" 50 "Reserved" 51 "Reserved" 52 "Reserved" 53 "Reserved" 54 "Reserved" 55 "Reserved" 56 "Reserved" 57 "Reserved" 58 "Reserved" 59 "Reserved" 60 "Reserved" 61 "Reserved" 62 "Reserved" 63 "Reserved" ;
VAL_ 562 SGW_AirCondAUTOReq 0 "No Request" 1 "Pressed" 2 "Reserved" 3 "Reserved" ;
VAL_ 562 SGW_DualReq 0 "No Request" 1 "Close" 2 "Open" 3 "Reserved" ;
VAL_ 562 SGW_AirDistributionModeReq 0 "No Request" 1 "Face" 2 "Bilevel(Foot face)" 3 "Foot" 4 "Foot Screen" 5 "Screen" 6 "Reserved" 7 "Reserved" ;
VAL_ 562 SGW_FrontDefrostReq 0 "NO Request" 1 "Off" 2 "On" 3 "Reserved" ;
VAL_ 562 SGW_AqsReq 0 "NO Request" 1 "Off" 2 "On" 3 "Reserved" ;
VAL_ 562 SGW_ClimateSystemStsReq 0 "NO Request" 1 "Off" 2 "On" 3 "Reserved" ;
VAL_ 562 SGW_ACCmprStsReq 0 "NO Request" 1 "Off" 2 "On" 3 "Reserved" ;
VAL_ 562 SGW_AirCirclnReq 0 "NO Request" 1 "Internal" 2 "External" 3 "Automatic" ;
VAL_ 562 SGW_BlowersteplsSpdReq 0 "No Request" 1 "Stepless Speed1_Low" 2 "Stepless Speed2" 3 "Stepless Speed3" 4 "Stepless Speed4" 5 "Stepless Speed5" 6 "Stepless Speed6" 7 "Stepless Speed7" 8 "Stepless Speed8_High" 9 "Reserved" 10 "Reserved" 11 "Reserved" 12 "Reserved" 13 "Reserved" 14 "Reserved" 15 "Reserved" ;
VAL_ 562 SGW_PresetModeEnable 0 "NO Request" 1 "Off" 2 "On" ;
VAL_ 562 SGW_PresetModeReq 0 "NO Request" 1 "Maximum heating" 2 "Foot heating" 3 "Hand heating" 4 "Rear seats MAX heat" 5 "Maximum cooling" 6 "Cooling foot and face areas" 7 "Rear Seats cooling" ;
VAL_ 562 SGW_VentilationModeReq 0 "NO Request" 1 "Off" 2 "On" ;
VAL_ 562 SGW_AirCondEcoSet 0 "NO Request" 1 "Off" 2 "On" 3 "Reserved" ;
VAL_ 560 IVI_DschrgOnOffSet 0 "No Request" 1 "OFF" 2 "ON" 3 "Reserved" ;
VAL_ 560 IVI_DriveModeSet 0 "No Request" 1 "ECO" 2 "NORMAL" 3 "SPORT" 4 "OnePedal" ;
VAL_ 560 IVI_ForwardVmaxAllowed 36001 "No request" ;
VAL_ 560 IVI_MaxChrgSocSet 254 "No Request" 255 "Invalid" ;
VAL_ 560 IVI_V2LidisSet 254 "No Request" 255 "Invalid" ;
VAL_ 564 SGW_TimeValid 0 "INVALID" 1 "VALID" ;
VAL_ 659 MessageCounter_293 15 "Invalid" ;
VAL_ 659 Switches_WiperSelection 0 "No request" 1 "Single wipe" 2 "Washer" 3 "Switch mode" 4 "Rush mode" 5 "Open menu" ;
VAL_ 659 Switches_MainBeamReq 0 "No Request" 1 "Half pressed" 2 "Short full pressed" 3 "Long full pressed" ;
VAL_ 659 Switches_ChangeLaneSW 0 "No request" 1 "Change lane to left" 2 "Change lane to Right" 3 "Reserve" ;
VAL_ 659 Switches_TurnSW 0 "OFF" 1 "Turn Left" 2 "Turn Right" 3 "Reserve" ;
VAL_ 659 Switches_BacklightadjustSts 0 "0%" 1 "10%" 2 "16%" 3 "22%" 4 "28%" 5 "34%" 6 "40%" 7 "50%" 8 "70%" 9 "80%" 10 "85%" 11 "90%" 12 "100%" ;
VAL_ 659 Switches_BacklightAutoSts 0 "Disable" 1 "Enable" ;
VAL_ 657 MessageCounter_291 15 "Invalid" ;
VAL_ 657 Switches_R_Up_Cmd 0 "No Press" 1 "Press" 2 "Error" ;
VAL_ 657 Switches_R_Down_Cmd 0 "No Press" 1 "Press" 2 "Error" ;
VAL_ 657 Switches_R_Left_Cmd 0 "No Press" 1 "Press" 2 "Error" ;
VAL_ 657 Switches_R_Right_Cmd 0 "No Press" 1 "Press" 2 "Error" ;
VAL_ 657 Switches_R_Accept_Cmd 0 "No Press" 1 "Press" 2 "Error" ;
VAL_ 657 Switches_L_Up_Cmd 0 "No Press" 1 "Press" 2 "Error" ;
VAL_ 657 Switches_L_Down_Cmd 0 "No Press" 1 "Press" 2 "Error" ;
VAL_ 657 Switches_L_Left_Cmd 0 "No Press" 1 "Press" 2 "Error" ;
VAL_ 657 Switches_L_Right_Cmd 0 "No Press" 1 "Press" 2 "Error" ;
VAL_ 657 Switches_L_Accept_Cmd 0 "No Press" 1 "Press" 2 "Error" ;
VAL_ 657 Switches_ButtonFaultWarn 0 "Normal" 1 "Fault" ;
VAL_ 271 Switches_L_SWipe_Cmd 0 "No Request" 1 "Fully Swipe From Top To Bottom(reserved)" 2 "Fully Swipe From Bottom To Top(reserved)" 3 "Semi Swipe From Top To Bottom(reserved)" 4 "Fully Swipe From Left To Right" 5 "Semi Swipe From Left To Center" 6 "Semi Swipe From Center To Right" 7 "Fully Swipe From Right To Left" 8 "Semi Swipe From Right To Center" 9 "Semi Swipe From Center To Left" 10 "Reserved" 11 "Reserved" 12 "Reserved" 13 "Reserved" 14 "Reserved" 15 "Reserved" ;
VAL_ 608 TCU_EVCompState 0 "off" 1 "running" 2 "limit" 3 "pre_heat" 4 "fault" 5 "reserved" 6 "reserved" 7 "reserved" ;
VAL_ 608 TCU_TMSState 0 "NotActive" 1 "Active" 2 "reserved" ;
VAL_ 608 TCU_TMSFaultLevel 0 "No Fault" 1 "Fault Level 1" 2 "Fault Level 2" 3 "Fault Level 3" 4 "Fault Level 4" 5 "Reserved" 6 "Reserved" 7 "Reserved" ;
VAL_ 608 TCU_HvOnReq 0 "No Request" 1 "Request" ;
VAL_ 608 TCU_HVCHState 0 "Default" 1 "OFF" 2 "ON" 3 "Reserved" ;
VAL_ 608 TCU_APTCState 0 "Default" 1 "OFF" 2 "ON" 3 "Reserved" ;
VAL_ 608 TCU_BattTMState 0 "sleep mode and no coolant flow" 1 "cooling mode" 2 "heating mode" 3 "pump only mode" 4 "exception mode" 5 "Reserved" 6 "Reserved" 7 "Reserved" ;
VAL_ 608 TCU_HVPwrState 0 "Default" 1 "OFF" 2 "ON" 3 "Reserved" ;
VAL_ 608 TCU_HVACACState 0 "Default" 1 "Auto" 2 "Manual" 3 "Reserved" ;
VAL_ 609 TCU_HVCHHighVoltage 509 "Invalid";
VAL_ 609 TCU_APTC1Enable 0 "Not Allowed" 1 "Allowed" ;
VAL_ 609 TCU_CompEnable 0 "Disabled" 1 "Enabled" ;
VAL_ 609 TCU_HVCHHVDCCurrent 255 "Invalid";
VAL_ 610 TCU_CabinTemperatureValid 0 "Invalid" 1 "Valid" ;
VAL_ 768 TCU_AirCondAUTOSts 0 "OFF" 1 "ON" ;
VAL_ 768 TCU_AirCirclnSts 0 "Internal" 1 "External" 2 "AUTO" ;
VAL_ 768 TCU_AirCondEcoSetSts 0 "OFF" 1 "ON" ;
VAL_ 768 TCU_SelfDryingSetSts 0 "OFF" 1 "ON" ;
VAL_ 768 TCU_DrvTempSts 0 "17(Low)" 1 "17.5" 2 "18" 3 "18.5" 4 "19" 5 "19.5" 6 "20" 7 "20.5" 8 "21" 9 "21.5" 10 "22" 11 "22.5" 12 "23" 13 "23.5" 14 "24" 15 "24.5" 16 "25" 17 "25.5" 18 "26" 19 "26.5" 20 "27" 21 "27.5" 22 "28(High)" 23 "Reserved" 24 "Reserved" 25 "Reserved" 26 "Reserved" 27 "Reserved" 28 "Reserved" 29 "Reserved" 30 "Reserved" 31 "Reserved" 32 "Reserved" 33 "Reserved" 34 "Reserved" 35 "Reserved" 36 "Reserved" 37 "Reserved" 38 "Reserved" 39 "Reserved" 40 "Reserved" 41 "Reserved" 42 "Reserved" 43 "Reserved" 44 "Reserved" 45 "Reserved" 46 "Reserved" 47 "Reserved" 48 "Reserved" 49 "Reserved" 50 "Reserved" 51 "Reserved" 52 "Reserved" 53 "Reserved" 54 "Reserved" 55 "Reserved" 56 "Reserved" 57 "Reserved" 58 "Reserved" 59 "Reserved" 60 "Reserved" 61 "Reserved" 62 "Reserved" 63 "Reserved" ;
VAL_ 768 TCU_AqsSts 0 "OFF" 1 "ON" ;
VAL_ 768 TCU_DualSts 0 "Single" 1 "Dual" ;
VAL_ 768 TCU_PassTempSts 0 "17(Low)" 1 "17.5" 2 "18" 3 "18.5" 4 "19" 5 "19.5" 6 "20" 7 "20.5" 8 "21" 9 "21.5" 10 "22" 11 "22.5" 12 "23" 13 "23.5" 14 "24" 15 "24.5" 16 "25" 17 "25.5" 18 "26" 19 "26.5" 20 "27" 21 "27.5" 22 "28(High)" 23 "Reserved" 24 "Reserved" 25 "Reserved" 26 "Reserved" 27 "Reserved" 28 "Reserved" 29 "Reserved" 30 "Reserved" 31 "Reserved" 32 "Reserved" 33 "Reserved" 34 "Reserved" 35 "Reserved" 36 "Reserved" 37 "Reserved" 38 "Reserved" 39 "Reserved" 40 "Reserved" 41 "Reserved" 42 "Reserved" 43 "Reserved" 44 "Reserved" 45 "Reserved" 46 "Reserved" 47 "Reserved" 48 "Reserved" 49 "Reserved" 50 "Reserved" 51 "Reserved" 52 "Reserved" 53 "Reserved" 54 "Reserved" 55 "Reserved" 56 "Reserved" 57 "Reserved" 58 "Reserved" 59 "Reserved" 60 "Reserved" 61 "Reserved" 62 "Reserved" 63 "Reserved" ;
VAL_ 768 TCU_CoolantLowWarnReq 0 "No Fault" 1 "Fault" 2 "Reserved" 3 "Invalid" ;
VAL_ 768 TCU_FreonLowWarnReq 0 "No Fault" 1 "Fault" 2 "Reserved" 3 "Invalid" ;
VAL_ 768 TCU_BlowerSpdSts 0 "OFF" 1 "Stepless Speed1_Low" 2 "Stepless Speed2" 3 "Stepless Speed3" 4 "Stepless Speed4" 5 "Stepless Speed5" 6 "Stepless Speed6" 7 "Stepless Speed7" 8 "Stepless Speed8_High" 9 "Reserved" 10 "Reserved" 11 "Reserved" 12 "Reserved" 13 "Reserved" 14 "Reserved" 15 "Reserved" ;
VAL_ 768 TCU_AirDistributionModeSts 0 "Face" 1 "Bilevel(Foot face)" 2 "Foot" 3 "Foot Screen" 4 "Screen" 5 "Reserved" 6 "Reserved" 7 "Not set" ;
VAL_ 768 TCU_PresetModeSts 0 "OFF" 1 "Maximum heating" 2 "Foot heating" 3 "Hand heating" 4 "Rear seats MAX heat" 5 "Maximum cooling" 6 "Cooling foot and face areas" 7 "Rear Seats cooling" ;
VAL_ 768 TCU_VentilationModeSts 0 "OFF" 1 "ON" ;
VAL_ 768 TCU_ACCmprSts 0 "OFF" 1 "ON" ;
VAL_ 768 TCU_ClimateSystemSts 0 "OFF" 1 "ON" ;
VAL_ 768 TCU_PowerLimitSts 0 "No  Power Limit" 1 "Power Limit" ;
VAL_ 768 TCU_OutsideAQSLevel 0 "Clean air level" 1 "Level 1 Low increase in pollution" 2 "Level 2 Mild increase in pollution" 3 "Level 3 Significant increase in pollution" 4 "Level 4 High increase in pollution" 5 "Level 5 Very high increase in pollution" 6 "Error" 7 "Reserved" ;
VAL_ 768 TCU_WindowClosRemind 0 "No hint" 1 "Reminder to close windows" ;
VAL_ 768 TCU_DemistSts 0 "OFF" 1 "ON" ;
VAL_ 793 VCU_BS_IBSBatSOC 255 "Invalid";
VAL_ 793 VCU_BS_IndicatorSts 0 "No request" 1 "Low SOH" ;
VAL_ 793 VCU_BS_Resistance 255 "Invalid";
VAL_ 546 VCU_BrakeCompensateStatus 0 "Invalid" 1 "OFF" 2 "ON" 3 "Reserved" ;
VAL_ 546 VCU_ChargeProcessComment 0 "No comment" 1 "Charge Fault and slow" 2 "Reserved" 3 "Reserved" ;
VAL_ 546 VCU_MemoryChargeFault 0 "Normal" 1 "Charge Fault" ;
VAL_ 547 VCU_ForwardVmaxlimitStatus 0 "Inactive" 1 "Active" ;
VAL_ 547 VCU_ManuallyUnlockComment 0 "False" 1 "True" ;
VAL_ 549 VCU_PermitPackPTC 0 "not permit" 1 "permit" ;
VAL_ 210 MessageCounter_0D2 15 "Invalid" ;
VAL_ 210 VCU_AccelerationPedalValid 0 "Invalid" 1 "Valid" ;
VAL_ 210 VCU_EPBReq 0 "Not Request" 1 "Apply Request" 2 "Release Request" 3 "Reserved" ;
VAL_ 210 VCU_TargetGear 0 "Reserve" 1 "P" 2 "N" 3 "R" 4 "D" ;
VAL_ 210 VCU_VehicleSpeedValid 0 "invalid" 1 "valid" ;
VAL_ 210 VCU_VirtualACPedalValid 0 "Invalid" 1 "Valid" ;
VAL_ 210 VCU_VLCTorqueRequestActive 0 "Not Active" 1 "Active" ;
VAL_ 210 VCU_VLCTorqueRequestAvailable 0 "Not Available" 1 "Available" ;
VAL_ 209 MessageCounter_0D1 15 "Invalid" ;
VAL_ 209 VCU_IsoMeasurementSwitch 0 "OFF" 1 "ON" ;
VAL_ 209 VCU_RequestedModeBMS 0 "InActive" 1 "HVActive" 2 "Reserved" 3 "Reserved" 4 "Reserved" 5 "EmergencyOff" 6 "Reserved" 7 "Invalid" ;
VAL_ 209 VCU_HVStatus 0 "Init" 1 "Standby" 2 "HV Ready" 3 "Drive ready" 4 "Preheating" 5 "Sleep" ;
VAL_ 209 VCU_ChargeStatus 0 "Init" 1 "Off Plug" 2 "AC Plug Detected" 3 "DC Plug Detected" 4 "V2L Plug Detected" 5 "AC Charging" 6 "DC Charging" 7 "V2L Discharging" 8 "Charging Completed" 9 "Charging Fault" 10 "AC Preheating" 11 "DC Preheating" 12 "V2L completed" 13 "KeepWarming" 14 "V2L Fault" ;
VAL_ 209 VCU_LimitLevel 0 "level 0-No limit" 1 "level 1" 2 "level 2" 3 "level 3" ;
VAL_ 209 VCU_ActDriveMode 0 "INVALID" 1 "ECO" 2 "NORMAL" 3 "SPORT" 4 "OnePedal" ;
VAL_ 209 VCU_DrvModSwitchWarn 0 "RESERVE" 1 "unrecommed Sport-Low SOC" 2 "Vehicle not in P gear,single pedal unavailable" 3 "Vehicle failure, single pedal unavailable." 4 "Reserved" 5 "Reserved" 6 "Reserved" 7 "Reserved" ;
VAL_ 209 VCU_RegenBrakeLightReqVld 0 "INVALID" 1 "VALID" ;
VAL_ 209 VCU_RegenBrakeLightRequest 0 "Brake lights Off" 1 "Brake lights On" ;
VAL_ 209 VCU_BMSTargetThermLevel 0 "Level 1(low)" 1 "Level 2(medium)" 2 "Level 3(high)" 3 "Reserved" ;
VAL_ 209 VCU_BMS_Control_of_PosRelay 0 "Invaild" 1 "Open" 2 "Close" ;
VAL_ 211 MessageCounter_0D3 15 "Invalid" ;
VAL_ 211 VCU_TorqueRequestAvailable 0 "Not Available" 1 "Available" ;
VAL_ 211 VCU_TorqueRequestActive 0 "Not Active" 1 "Active" ;
VAL_ 211 VCU_RegenTorqueCapValid 0 "invalid" 1 "valid" ;
VAL_ 211 VCU_ADASOverride 0 "off" 1 "on" ;
VAL_ 211 VCU_APSTorqueRequestActive 0 "Not Active" 1 "Active" ;
VAL_ 211 VCU_APSTorqueRequestAvailable 0 "Not Available" 1 "Available" ;
VAL_ 211 VCU_DecelerationReqactive 0 "Inactive;" 1 "Active" ;
VAL_ 211 VCU_RegStatus 0 "Reserve" 1 "OFF" 2 "Primary energy recovery (weak)" 3 "Secondary energy recovery(medium)" 4 "Tertiary energy recovery (strong)" 5 "Reserved" 6 "Reserved" 7 "Reserved" ;
VAL_ 211 VCU_BrakeCompensateWarn 0 "No display" 1 "Vehicle failure, brake compensation failed to open." 2 "Reserved" 3 "Reserved" ;
VAL_ 211 VCU_EnergyManagementWarn 0 "OFF" 1 "Battery is discharging, recommended to turn off the air conditioner or other loads." 2 "Reserved" 3 "Reserved" ;
VAL_ 544 VCU_VoltageDemandLV 510 "Init" 511 "Error" ;
VAL_ 544 VCU_RequestedModeDCDC 0 "OFF" 1 "Buck" 2 "Disable" ;
VAL_ 791 MessageCounter_317 15 "Invalid" ;
VAL_ 791 VCU_ReachLimitStd 0 "No request" 1 "Request" ;
VAL_ 791 VCU_DriveMotOvrTemp 0 "False" 1 "True" ;
VAL_ 791 VCU_DCDCFail 0 "False" 1 "True" ;
VAL_ 791 VCU_HVBatOvrTemp 0 "False" 1 "True" ;
VAL_ 791 VCU_HVILError 0 "False" 1 "True" ;
VAL_ 791 VCU_HVInsulResFault 0 "False" 1 "True" ;
VAL_ 791 VCU_LimpHome 0 "False" 1 "True" ;
VAL_ 791 VCU_BatteryPerformance 0 "Normal" 1 "Battery temperature abnormal,power limited" 2 "Battery temperature fault" 3 "Reserved" ;
VAL_ 791 VCU_HVBatCriFail 0 "False" 1 "Yellow" 2 "Red" 3 "Reserve" ;
VAL_ 791 VCU_CriSysFailure 0 "No_Warning" 1 "Leve1 (lighting prompt only)" 2 "Leve2 (power loss)" 3 "Leve3 (emergency power off)" ;
VAL_ 791 VCU_PlugStatus 0 "Init" 1 "No_Plug_connected" 2 "AC_Plug_connected_Unlock" 3 "AC_Plug_connected_Locked" 4 "DC_Plug_connected" 5 "V2L_Plug_connected" 6 "AC Plug&DC Plug Connected" 7 "Fault" ;
VAL_ 791 VCU_InvldGearSel 0 "Normal" 1 "Shifting fails, please brake" 2 "Danger _ Too high speed _ do not switch D gear" 3 "Danger _ Too high speed _ do not switch R gear" 4 "Danger _ Too high speed _ do not switch P gear" 5 "Danger _ The accelerator pedal is too large _ it is forbidden to switch driving gear" 6 "Charging gun connected, do not switch gear" 7 "The shift button is faulty _ Screen shift is recommended" 8 "The vehicle is not ready_it is forbidden to switch driving gears" 9 "EPB unresponsive_unable to engage in P gear" 10 "EPB unresponsive_unable to exit in P gear" 11 "SWP is faulty _ PRND button is recommended" 12 "Fault detected, shift failed, please restart the vehicle or contact customer service" 13 "Danger _ Too high speed _ do not switch N gear" 14 "Gun insertion detected. execute automatic P-gear" 15 "Immo state enable,forbid gear shifting" ;
VAL_ 792 MessageCounter_318 15 "Invalid" ;
VAL_ 792 VCU_MCU_FaultLampReq 0 "No Request" 1 "Yellow-LED request" 2 "Red-LED request" 3 "Reserve" ;
VAL_ 792 VCU_SystemReady 0 "Not Ready" 1 "Ready" ;
VAL_ 792 VCU_maxChargeSOC 254 "No Request" 255 "Invalid" ;
VAL_ 792 VCU_ForwardVmaxAllowed 0 "No request" 1 "1-170" 2 "1-170" 3 "1-170" 4 "1-170" 5 "1-170" 6 "1-170" 7 "1-170" 8 "1-170" 9 "1-170" 10 "1-170" 11 "1-170" 12 "1-170" 13 "1-170" 14 "1-170" 15 "1-170" 16 "1-170" 17 "1-170" 18 "1-170" 19 "1-170" 20 "1-170" 21 "1-170" 22 "1-170" 23 "1-170" 24 "1-170" 25 "1-170" 26 "1-170" 27 "1-170" 28 "1-170" 29 "1-170" 30 "1-170" 31 "1-170" 32 "1-170" 33 "1-170" 34 "1-170" 35 "1-170" 36 "1-170" 37 "1-170" 38 "1-170" 39 "1-170" 40 "1-170" 41 "1-170" 42 "1-170" 43 "1-170" 44 "1-170" 45 "1-170" 46 "1-170" 47 "1-170" 48 "1-170" 49 "1-170" 50 "1-170" 51 "1-170" 52 "1-170" 53 "1-170" 54 "1-170" 55 "1-170" 56 "1-170" 57 "1-170" 58 "1-170" 59 "1-170" 60 "1-170" 61 "1-170" 62 "1-170" 63 "1-170" 64 "1-170" 65 "1-170" 66 "1-170" 67 "1-170" 68 "1-170" 69 "1-170" 70 "1-170" 71 "1-170" 72 "1-170" 73 "1-170" 74 "1-170" 75 "1-170" 76 "1-170" 77 "1-170" 78 "1-170" 79 "1-170" 80 "1-170" 81 "1-170" 82 "1-170" 83 "1-170" 84 "1-170" 85 "1-170" 86 "1-170" 87 "1-170" 88 "1-170" 89 "1-170" 90 "1-170" 91 "1-170" 92 "1-170" 93 "1-170" 94 "1-170" 95 "1-170" 96 "1-170" 97 "1-170" 98 "1-170" 99 "1-170" 100 "1-170" 101 "1-170" 102 "1-170" 103 "1-170" 104 "1-170" 105 "1-170" 106 "1-170" 107 "1-170" 108 "1-170" 109 "1-170" 110 "1-170" 111 "1-170" 112 "1-170" 113 "1-170" 114 "1-170" 115 "1-170" 116 "1-170" 117 "1-170" 118 "1-170" 119 "1-170" 120 "1-170" 121 "1-170" 122 "1-170" 123 "1-170" 124 "1-170" 125 "1-170" 126 "1-170" 127 "1-170" 128 "1-170" 129 "1-170" 130 "1-170" 131 "1-170" 132 "1-170" 133 "1-170" 134 "1-170" 135 "1-170" 136 "1-170" 137 "1-170" 138 "1-170" 139 "1-170" 140 "1-170" 141 "1-170" 142 "1-170" 143 "1-170" 144 "1-170" 145 "1-170" 146 "1-170" 147 "1-170" 148 "1-170" 149 "1-170" 150 "1-170" 151 "1-170" 152 "1-170" 153 "1-170" 154 "1-170" 155 "1-170" 156 "1-170" 157 "1-170" 158 "1-170" 159 "1-170" 160 "1-170" 161 "1-170" 162 "1-170" 163 "1-170" 164 "1-170" 165 "1-170" 166 "1-170" 167 "1-170" 168 "1-170" 169 "1-170" 170 "1-170" 171 "Reserved" 172 "Reserved" 173 "Reserved" 174 "Reserved" 175 "Reserved" 176 "Reserved" 177 "Reserved" 178 "Reserved" 179 "Reserved" 180 "Reserved" 181 "Reserved" 182 "Reserved" 183 "Reserved" 184 "Reserved" 185 "Reserved" 186 "Reserved" 187 "Reserved" 188 "Reserved" 189 "Reserved" 190 "Reserved" 191 "Reserved" 192 "Reserved" 193 "Reserved" 194 "Reserved" 195 "Reserved" 196 "Reserved" 197 "Reserved" 198 "Reserved" 199 "Reserved" 200 "Reserved" 201 "Reserved" 202 "Reserved" 203 "Reserved" 204 "Reserved" 205 "Reserved" 206 "Reserved" 207 "Reserved" 208 "Reserved" 209 "Reserved" 210 "Reserved" 211 "Reserved" 212 "Reserved" 213 "Reserved" 214 "Reserved" 215 "Reserved" 216 "Reserved" 217 "Reserved" 218 "Reserved" 219 "Reserved" 220 "Reserved" 221 "Reserved" 222 "Reserved" 223 "Reserved" 224 "Reserved" 225 "Reserved" 226 "Reserved" 227 "Reserved" 228 "Reserved" 229 "Reserved" 230 "Reserved" 231 "Reserved" 232 "Reserved" 233 "Reserved" 234 "Reserved" 235 "Reserved" 236 "Reserved" 237 "Reserved" 238 "Reserved" 239 "Reserved" 240 "Reserved" 241 "Reserved" 242 "Reserved" 243 "Reserved" 244 "Reserved" 245 "Reserved" 246 "Reserved" 247 "Reserved" 248 "Reserved" 249 "Reserved" 250 "Reserved" 251 "Reserved" 252 "Reserved" 253 "Reserved" 254 "Reserved" 255 "Reserved" ;
VAL_ 148 MessageCounter_094 15 "Invalid" ;
VAL_ 148 VCU_MotorActualTorqueValid 0 "Invalid" 1 "Valid" ;
VAL_ 148 VCU_WheelTrqACTValid 0 "invalid" 1 "valid" ;
VAL_ 150 VCU_MotorSpdReq 65535 "Invalid";
VAL_ 150 VCU_MaxSpdLimit 65535 "Invalid";
VAL_ 150 VCU_MCUActHeatPwr 254 "Init" 255 "Error" ;
VAL_ 149 MessageCounter_095 15 "Invalid" ;
VAL_ 149 VCU_PWTErrorLevel 0 "Fault Level0" 1 "Fault Level1" 2 "Fault Level2" 3 "Fault Level3" 4 "Fault Level4" 5 "Fault Level5" 6 "Fault Level6" 7 "Fault Level7" 8 "Fault Level8" 9 "Fault Level9" 10 "Fault Level10" 11 "Fault Level11" 12 "Fault Level12" 13 "Fault Level13" 14 "Fault Level14" 15 "Fault Level15" ;
VAL_ 149 VCU_MCUDesiredTorque 2046 "Init" 2047 "Error" ;
VAL_ 149 VCU_KL15eOn 0 "Off" 1 "On" ;
VAL_ 149 VCU_TCSActive 0 "NotActive" 1 "Active" ;
VAL_ 149 VCU_MCUSurgeDamperState 0 "DstC_off" 1 "DstC_ext" 2 "DstC_int_ext" ;
VAL_ 149 VCU_ActualGear 0 "Reserve" 1 "P" 2 "N" 3 "R" 4 "D" ;
VAL_ 149 VCU_BrakepedalStatus 0 "No pressed" 1 "pressed" 2 "Invalid" ;
VAL_ 149 VCU_RequestedModeMCU 0 "Ready" 1 "TrqCtrl" 2 "Active Hearting" 3 "Discharge" 4 "SpeedCtrl" ;
VAL_ 149 VCU_TrqThresholdDampgCtl 254 "Init" 255 "Error" ;
VAL_ 214 VCU_MaxTorqueGradient 16382 "Init" 16383 "Error" ;
VAL_ 214 VCU_MinTorqueLimit 2046 "Init" 2047 "Error" ;
VAL_ 214 VCU_MaxTorqueLimit 2046 "Init" 2047 "Error" ;
VAL_ 913 VCU_RemainChrgTime 1022 "Init" 1023 "Error" ;
VAL_ 913 VCU_HVConnectFault 0 "Normal" 1 "Fault" ;
VAL_ 913 VCU_ChargeEndReason 0 "No Display" 1 "Reach the charge cut-off SOC" 2 "reserved" 3 "reserved" ;
VAL_ 913 VCU_DischargeEndReason 0 "No Display" 1 "Reach the discharge cut-off SOC" 2 "reserved" 3 "reserved" ;
VAL_ 289 VCU_Enable_DC_Relay 0 "Close Request" 1 "Open Request" ;
VAL_ 289 VCU_OBC_Control_of_S2_SW 0 "Close" 1 "Open" ;
VAL_ 289 VCU_OBC_Control_of_em_lock 0 "Close" 1 "Open" ;
VAL_ 289 VCU_EnableOBC 0 "Reserve" 1 "Reserve" 2 "Enable" 3 "Disable" ;
VAL_ 545 VCU_RequestedModeTCU 0 "Init" 1 "Standby" 2 "Disable" 3 "Enable" ;
VAL_ 663 WCBS1_Reminder 0 "no warning" 1 "warning" ;
VAL_ 663 WCBS1_ReminderSts 0 "Disabled" 1 "Enabled" ;
VAL_ 664 WCBS2_Reminder 0 "no warning" 1 "warning" ;
VAL_ 664 WCBS2_ReminderSts 0 "Disabled" 1 "Enabled" ;
VAL_ 898 CGW_VERSION1 0 "concept" 1 "Sample A" 2 "Sample B" 3 "Sample C" 4 "Sample D" 5 "Sample SW" ;
VAL_ 858 CGW_SGWSts 0 "Sleep" 1 "Wake up" ;
VAL_ 858 CGW_CGWSts 0 "Sleep" 1 "Wake up" ;
VAL_ 858 CGW_CBMSts 0 "Sleep" 1 "Wake up" ;
VAL_ 858 CGW_DCM_FLSts 0 "Sleep" 1 "Wake up" ;
VAL_ 858 CGW_DCM_FRSts 0 "Sleep" 1 "Wake up" ;
VAL_ 858 CGW_DCM_RLSts 0 "Sleep" 1 "Wake up" ;
VAL_ 858 CGW_DCM_RRSts 0 "Sleep" 1 "Wake up" ;
VAL_ 858 CGW_SCU_LSts 0 "Sleep" 1 "Wake up" ;
VAL_ 858 CGW_SCU_RSts 0 "Sleep" 1 "Wake up" ;
VAL_ 858 CGW_HLRSts 0 "Sleep" 1 "Wake up" ;
VAL_ 858 CGW_HLLSts 0 "Sleep" 1 "Wake up" ;
VAL_ 858 CGW_MFP_RCSts 0 "Sleep" 1 "Wake up" ;
VAL_ 858 CGW_MFP_FCSts 0 "Sleep" 1 "Wake up" ;
VAL_ 858 CGW_IVISts 0 "Sleep" 1 "Wake up" ;
VAL_ 858 CGW_ADCUSts 0 "Sleep" 1 "Wake up" ;
VAL_ 858 CGW_VCUSts 0 "Sleep" 1 "Wake up" ;
VAL_ 858 CGW_BMSSts 0 "Sleep" 1 "Wake up" ;
VAL_ 858 CGW_BCMSts 0 "Sleep" 1 "Wake up" ;
VAL_ 858 CGW_SWPSts 0 "Sleep" 1 "Wake up" ;
VAL_ 858 CGW_HOD_HeatingSts 0 "Sleep" 1 "Wake up" ;
VAL_ 858 CGW_SwichesSts 0 "Sleep" 1 "Wake up" ;
VAL_ 858 CGW_PRNDSts 0 "Sleep" 1 "Wake up" ;
VAL_ 857 SGW_SGWSts 0 "Sleep" 1 "Wake up" ;
VAL_ 857 SGW_CGWSts 0 "Sleep" 1 "Wake up" ;
VAL_ 857 SGW_CBMSts 0 "Sleep" 1 "Wake up" ;
VAL_ 857 SGW_DCM_FLSts 0 "Sleep" 1 "Wake up" ;
VAL_ 857 SGW_DCM_FRSts 0 "Sleep" 1 "Wake up" ;
VAL_ 857 SGW_DCM_RLSts 0 "Sleep" 1 "Wake up" ;
VAL_ 857 SGW_DCM_RRSts 0 "Sleep" 1 "Wake up" ;
VAL_ 857 SGW_SCU_LSts 0 "Sleep" 1 "Wake up" ;
VAL_ 857 SGW_SCU_RSts 0 "Sleep" 1 "Wake up" ;
VAL_ 857 SGW_HLRSts 0 "Sleep" 1 "Wake up" ;
VAL_ 857 SGW_HLLSts 0 "Sleep" 1 "Wake up" ;
VAL_ 857 SGW_MFP_RCSts 0 "Sleep" 1 "Wake up" ;
VAL_ 857 SGW_MFP_FCSts 0 "Sleep" 1 "Wake up" ;
VAL_ 857 SGW_IVISts 0 "Sleep" 1 "Wake up" ;
VAL_ 857 SGW_ADCUSts 0 "Sleep" 1 "Wake up" ;
VAL_ 857 SGW_VCUSts 0 "Sleep" 1 "Wake up" ;
VAL_ 857 SGW_BMSSts 0 "Sleep" 1 "Wake up" ;
VAL_ 857 SGW_BCMSts 0 "Sleep" 1 "Wake up" ;
VAL_ 857 SGW_SWPSts 0 "Sleep" 1 "Wake up" ;
VAL_ 857 SGW_HOD_HeatingSts 0 "Sleep" 1 "Wake up" ;
VAL_ 857 SGW_SwichesSts 0 "Sleep" 1 "Wake up" ;
VAL_ 857 SGW_PRNDSts 0 "Sleep" 1 "Wake up" ;
VAL_ 1283 SGW_RMR 0 "Repeat Message State not requested" 1 "Repeat Message State requested" ;
VAL_ 1283 SGW_AWB 0 "Node has not woken up the network (passive wakeup)" 1 "Node has woken up the network (active Wakeup)" ;
VAL_ 1283 SGW_PNI 0 "The NM message does not contain Partial network management request information;" 1 "The NM message contains Partial network management request information." ;
VAL_ 1283 SGW_PNC0 0 "Inactive" 1 "Active" ;
VAL_ 1283 SGW_PNC1 0 "Inactive" 1 "Active" ;
VAL_ 1283 SGW_PNC2 0 "Inactive" 1 "Active" ;
VAL_ 1283 SGW_PNC3 0 "Inactive" 1 "Active" ;
VAL_ 1283 SGW_PNC4 0 "Inactive" 1 "Active" ;
VAL_ 1283 SGW_PNC5 0 "Inactive" 1 "Active" ;
VAL_ 1283 SGW_PNC6 0 "Inactive" 1 "Active" ;
VAL_ 1283 SGW_PNC7 0 "Inactive" 1 "Active" ;
VAL_ 1283 SGW_PNC8 0 "Inactive" 1 "Active" ;
VAL_ 1283 SGW_PNC9 0 "Inactive" 1 "Active" ;
VAL_ 1283 SGW_PNC10 0 "Inactive" 1 "Active" ;
VAL_ 1283 SGW_PNC11 0 "Inactive" 1 "Active" ;
VAL_ 1283 SGW_PNC12 0 "Inactive" 1 "Active" ;
VAL_ 1283 SGW_PNC13 0 "Inactive" 1 "Active" ;
VAL_ 1283 SGW_PNC14 0 "Inactive" 1 "Active" ;
VAL_ 1283 SGW_PNC15 0 "Inactive" 1 "Active" ;
VAL_ 1283 SGW_PNC16 0 "Inactive" 1 "Active" ;
VAL_ 1283 SGW_PNC17 0 "Inactive" 1 "Active" ;
VAL_ 1283 SGW_PNC18 0 "Inactive" 1 "Active" ;
VAL_ 1283 SGW_PNC19 0 "Inactive" 1 "Active" ;
VAL_ 1283 SGW_PNC20 0 "Inactive" 1 "Active" ;
VAL_ 1283 SGW_PNC21 0 "Inactive" 1 "Active" ;
VAL_ 1283 SGW_PNC22 0 "Inactive" 1 "Active" ;
VAL_ 1283 SGW_PNC23 0 "Inactive" 1 "Active" ;
VAL_ 1283 SGW_PNC24 0 "Inactive" 1 "Active" ;
VAL_ 1283 SGW_PNC25 0 "Inactive" 1 "Active" ;
VAL_ 1283 SGW_PNC26 0 "Inactive" 1 "Active" ;
VAL_ 1283 SGW_PNC27 0 "Inactive" 1 "Active" ;
VAL_ 1283 SGW_PNC28 0 "Inactive" 1 "Active" ;
VAL_ 1283 SGW_PNC29 0 "Inactive" 1 "Active" ;
VAL_ 1283 SGW_PNC30 0 "Inactive" 1 "Active" ;
VAL_ 1283 SGW_PNC31 0 "Inactive" 1 "Active" ;
VAL_ 1283 SGW_PNC32 0 "Inactive" 1 "Active" ;
VAL_ 1283 SGW_PNC33 0 "Inactive" 1 "Active" ;
VAL_ 1283 SGW_PNC34 0 "Inactive" 1 "Active" ;
VAL_ 1283 SGW_PNC35 0 "Inactive" 1 "Active" ;
VAL_ 1283 SGW_PNC36 0 "Inactive" 1 "Active" ;
VAL_ 1283 SGW_PNC37 0 "Inactive" 1 "Active" ;
VAL_ 1283 SGW_PNC38 0 "Inactive" 1 "Active" ;
VAL_ 1283 SGW_PNC39 0 "Inactive" 1 "Active" ;
VAL_ 1282 CGW_RMR 0 "Repeat Message State not requested" 1 "Repeat Message State requested" ;
VAL_ 1282 CGW_AWB 0 "Node has not woken up the network (passive wakeup)" 1 "Node has woken up the network (active Wakeup)" ;
VAL_ 1282 CGW_PNI 0 "The NM message does not contain Partial network management request information;" 1 "The NM message contains Partial network management request information." ;
VAL_ 1282 CGW_PNC0 0 "Inactive" 1 "Active" ;
VAL_ 1282 CGW_PNC1 0 "Inactive" 1 "Active" ;
VAL_ 1282 CGW_PNC2 0 "Inactive" 1 "Active" ;
VAL_ 1282 CGW_PNC3 0 "Inactive" 1 "Active" ;
VAL_ 1282 CGW_PNC4 0 "Inactive" 1 "Active" ;
VAL_ 1282 CGW_PNC5 0 "Inactive" 1 "Active" ;
VAL_ 1282 CGW_PNC6 0 "Inactive" 1 "Active" ;
VAL_ 1282 CGW_PNC7 0 "Inactive" 1 "Active" ;
VAL_ 1282 CGW_PNC8 0 "Inactive" 1 "Active" ;
VAL_ 1282 CGW_PNC9 0 "Inactive" 1 "Active" ;
VAL_ 1282 CGW_PNC10 0 "Inactive" 1 "Active" ;
VAL_ 1282 CGW_PNC11 0 "Inactive" 1 "Active" ;
VAL_ 1282 CGW_PNC12 0 "Inactive" 1 "Active" ;
VAL_ 1282 CGW_PNC13 0 "Inactive" 1 "Active" ;
VAL_ 1282 CGW_PNC14 0 "Inactive" 1 "Active" ;
VAL_ 1282 CGW_PNC15 0 "Inactive" 1 "Active" ;
VAL_ 1282 CGW_PNC16 0 "Inactive" 1 "Active" ;
VAL_ 1282 CGW_PNC17 0 "Inactive" 1 "Active" ;
VAL_ 1282 CGW_PNC18 0 "Inactive" 1 "Active" ;
VAL_ 1282 CGW_PNC19 0 "Inactive" 1 "Active" ;
VAL_ 1282 CGW_PNC20 0 "Inactive" 1 "Active" ;
VAL_ 1282 CGW_PNC21 0 "Inactive" 1 "Active" ;
VAL_ 1282 CGW_PNC22 0 "Inactive" 1 "Active" ;
VAL_ 1282 CGW_PNC23 0 "Inactive" 1 "Active" ;
VAL_ 1282 CGW_PNC24 0 "Inactive" 1 "Active" ;
VAL_ 1282 CGW_PNC25 0 "Inactive" 1 "Active" ;
VAL_ 1282 CGW_PNC26 0 "Inactive" 1 "Active" ;
VAL_ 1282 CGW_PNC27 0 "Inactive" 1 "Active" ;
VAL_ 1282 CGW_PNC28 0 "Inactive" 1 "Active" ;
VAL_ 1282 CGW_PNC29 0 "Inactive" 1 "Active" ;
VAL_ 1282 CGW_PNC30 0 "Inactive" 1 "Active" ;
VAL_ 1282 CGW_PNC31 0 "Inactive" 1 "Active" ;
VAL_ 1282 CGW_PNC32 0 "Inactive" 1 "Active" ;
VAL_ 1282 CGW_PNC33 0 "Inactive" 1 "Active" ;
VAL_ 1282 CGW_PNC34 0 "Inactive" 1 "Active" ;
VAL_ 1282 CGW_PNC35 0 "Inactive" 1 "Active" ;
VAL_ 1282 CGW_PNC36 0 "Inactive" 1 "Active" ;
VAL_ 1282 CGW_PNC37 0 "Inactive" 1 "Active" ;
VAL_ 1282 CGW_PNC38 0 "Inactive" 1 "Active" ;
VAL_ 1282 CGW_PNC39 0 "Inactive" 1 "Active" ;
